VERSION "canboat-NMEA2000-curated"

NS_ :

BS_:

BU_: Vector__XXX
BO_ 2582645504 PGN_126987_alertThreshold: 18 Vector__XXX
 SG_ Alert_Type : 0|4@1+ (1.0,0) [0|15] "" Vector__XXX
 SG_ Alert_Category : 4|4@1+ (1.0,0) [0|15] "" Vector__XXX
 SG_ Alert_System : 8|8@1+ (1.0,0) [0|255] "" Vector__XXX
 SG_ Alert_Sub_System : 16|8@1+ (1.0,0) [0|255] "" Vector__XXX
 SG_ Alert_ID : 24|16@1+ (1.0,0) [0|65535] "" Vector__XXX
 SG_ Data_Source_Network_ID_NAME : 40|64@1+ (1.0,0) [0|18446744073709551615] "" Vector__XXX
 SG_ Data_Source_Instance : 104|8@1+ (1.0,0) [0|255] "" Vector__XXX
 SG_ Data_Source_Index_Source : 112|8@1+ (1.0,0) [0|255] "" Vector__XXX
 SG_ Alert_Occurrence_Number : 120|8@1+ (1.0,0) [0|255] "" Vector__XXX
 SG_ Number_of_Parameters : 128|8@1+ (1.0,0) [0|255] "" Vector__XXX
 SG_ field136 : 136|8@1+ (1.0,0) [0|255] "" Vector__XXX

BO_ 2582645760 PGN_126988_alertValue: 18 Vector__XXX
 SG_ Alert_Type : 0|4@1+ (1.0,0) [0|15] "" Vector__XXX
 SG_ Alert_Category : 4|4@1+ (1.0,0) [0|15] "" Vector__XXX
 SG_ Alert_System : 8|8@1+ (1.0,0) [0|255] "" Vector__XXX
 SG_ Alert_Sub_System : 16|8@1+ (1.0,0) [0|255] "" Vector__XXX
 SG_ Alert_ID : 24|16@1+ (1.0,0) [0|65535] "" Vector__XXX
 SG_ Data_Source_Network_ID_NAME : 40|64@1+ (1.0,0) [0|18446744073709551615] "" Vector__XXX
 SG_ Data_Source_Instance : 104|8@1+ (1.0,0) [0|255] "" Vector__XXX
 SG_ Data_Source_Index_Source : 112|8@1+ (1.0,0) [0|255] "" Vector__XXX
 SG_ Alert_Occurrence_Number : 120|8@1+ (1.0,0) [0|255] "" Vector__XXX
 SG_ Number_of_Parameters : 128|8@1+ (1.0,0) [0|255] "" Vector__XXX
 SG_ field136 : 136|8@1+ (1.0,0) [0|255] "" Vector__XXX

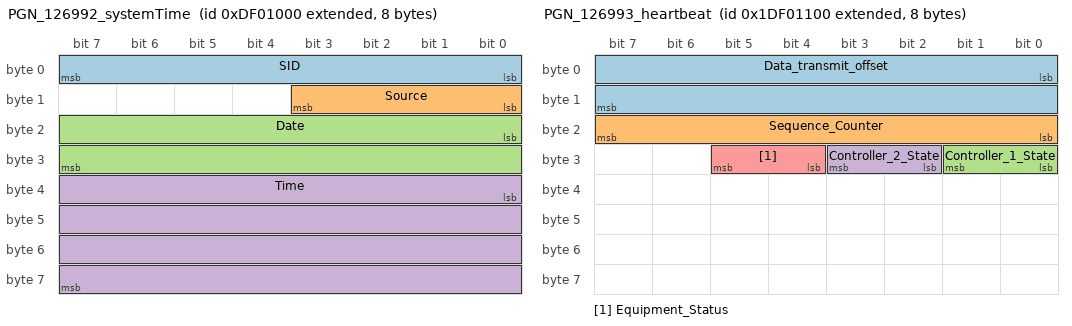
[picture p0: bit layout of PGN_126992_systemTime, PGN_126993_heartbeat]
BO_ 2381320192 PGN_126992_systemTime: 8 Vector__XXX
 SG_ SID : 0|8@1+ (1.0,0) [0|255] "" Vector__XXX
 SG_ Source : 8|4@1+ (1.0,0) [0|15] "" Vector__XXX
 SG_ Date : 16|16@1+ (1.0,0) [0|65535] "" Vector__XXX
 SG_ Time : 32|32@1+ (0.0001,0) [0.0|86401.0] "" Vector__XXX

BO_ 2649755904 PGN_126993_heartbeat: 8 Vector__XXX
 SG_ Data_transmit_offset : 0|16@1+ (0.001,0) [0.0|65.535] "" Vector__XXX
 SG_ Sequence_Counter : 16|8@1+ (1.0,0) [0|255] "" Vector__XXX
 SG_ Controller_1_State : 24|2@1+ (1.0,0) [0|3] "" Vector__XXX
 SG_ Controller_2_State : 26|2@1+ (1.0,0) [0|3] "" Vector__XXX
 SG_ Equipment_Status : 28|2@1+ (1.0,0) [0|3] "" Vector__XXX

BO_ 2582647808 PGN_126996_productInformation: 134 Vector__XXX
 SG_ NMEA_2000_Version : 0|16@1+ (0.001,0) [0.0|65.535] "" Vector__XXX
 SG_ Product_Code : 16|16@1+ (1.0,0) [0|65535] "" Vector__XXX
 SG_ Model_ID : 32|256@1+ (1.0,0) [0|115792089237316195423570985008687907853269984665640564039457584007913129639935] "" Vector__XXX
 SG_ Software_Version_Code : 288|256@1+ (1.0,0) [0|115792089237316195423570985008687907853269984665640564039457584007913129639935] "" Vector__XXX
 SG_ Model_Version : 544|256@1+ (1.0,0) [0|115792089237316195423570985008687907853269984665640564039457584007913129639935] "" Vector__XXX
 SG_ Model_Serial_Code : 800|256@1+ (1.0,0) [0|115792089237316195423570985008687907853269984665640564039457584007913129639935] "" Vector__XXX
 SG_ Certification_Level : 1056|8@1+ (1.0,0) [0|255] "" Vector__XXX
 SG_ Load_Equivalency : 1064|8@1+ (1.0,0) [0|255] "" Vector__XXX

BO_ 2582648320 PGN_126998_configurationInformation: 8 Vector__XXX
 SG_ Installation_Description__1 : 0|8@1+ (1.0,0) [0|255] "" Vector__XXX
 SG_ Installation_Description__2 : 8|8@1+ (1.0,0) [0|255] "" Vector__XXX
 SG_ Manufacturer_Information : 16|8@1+ (1.0,0) [0|255] "" Vector__XXX

BO_ 2582708480 PGN_127233_manOverboardNotification: 35 Vector__XXX
 SG_ SID : 0|8@1+ (1.0,0) [0|255] "" Vector__XXX
 SG_ MOB_Emitter_ID : 8|32@1+ (1.0,0) [0|4294967295] "" Vector__XXX
 SG_ Man_Overboard_Status : 40|3@1+ (1.0,0) [0|7] "" Vector__XXX
 SG_ Activation_Time : 48|32@1+ (0.0001,0) [0.0|86401.0] "" Vector__XXX
 SG_ Position_Source : 80|3@1+ (1.0,0) [0|7] "" Vector__XXX
 SG_ Position_Date : 88|16@1+ (1.0,0) [0|65535] "" Vector__XXX
 SG_ Position_Time : 104|32@1+ (0.0001,0) [0.0|86401.0] "" Vector__XXX
 SG_ Latitude : 136|32@1- (1e-07,0) [-90.0|90.0] "" Vector__XXX
 SG_ Longitude : 168|32@1- (1e-07,0) [-180.0|180.0] "" Vector__XXX
 SG_ COG_Reference : 200|2@1+ (1.0,0) [0|3] "" Vector__XXX
 SG_ COG : 208|16@1+ (0.0001,0) [0.0|6.5535000000000005] "" Vector__XXX
 SG_ SOG : 224|16@1+ (0.01,0) [0.0|655.35] "" Vector__XXX
 SG_ MMSI_of_vessel_of_origin : 240|32@1+ (1.0,0) [2000000.0|999999999.0] "" Vector__XXX
 SG_ MOB_Emitter_Battery_Low_Status : 272|3@1+ (1.0,0) [0|7] "" Vector__XXX

BO_ 2314274048 PGN_127237_headingTrackControl: 21 Vector__XXX
 SG_ Rudder_Limit_Exceeded : 0|2@1+ (1.0,0) [0|3] "" Vector__XXX
 SG_ Off_Heading_Limit_Exceeded : 2|2@1+ (1.0,0) [0|3] "" Vector__XXX
 SG_ Off_Track_Limit_Exceeded : 4|2@1+ (1.0,0) [0|3] "" Vector__XXX
 SG_ Override : 6|2@1+ (1.0,0) [0|3] "" Vector__XXX
 SG_ Steering_Mode : 8|3@1+ (1.0,0) [0|7] "" Vector__XXX
 SG_ Turn_Mode : 11|3@1+ (1.0,0) [0|7] "" Vector__XXX
 SG_ Heading_Reference : 14|2@1+ (1.0,0) [0|3] "" Vector__XXX
 SG_ Commanded_Rudder_Direction : 21|3@1+ (1.0,0) [0|7] "" Vector__XXX
 SG_ Commanded_Rudder_Angle : 24|16@1- (0.0001,0) [-3.2768|3.2767] "" Vector__XXX
 SG_ Heading_To_Steer__Course_ : 40|16@1+ (0.0001,0) [0.0|6.5535000000000005] "" Vector__XXX
 SG_ Track : 56|16@1+ (0.0001,0) [0.0|6.5535000000000005] "" Vector__XXX
 SG_ Rudder_Limit : 72|16@1+ (0.0001,0) [0.0|6.5535000000000005] "" Vector__XXX
 SG_ Off_Heading_Limit : 88|16@1+ (0.0001,0) [0.0|6.5535000000000005] "" Vector__XXX
 SG_ Radius_of_Turn_Order : 104|16@1- (1.0,0) [-32768|32767] "" Vector__XXX
 SG_ Rate_of_Turn_Order : 120|16@1- (3.125e-05,0) [-1.024|1.02396875] "" Vector__XXX
 SG_ Off_Track_Limit : 136|16@1- (1.0,0) [-32768|32767] "" Vector__XXX
 SG_ Vessel_Heading : 152|16@1+ (0.0001,0) [0.0|6.5535000000000005] "" Vector__XXX

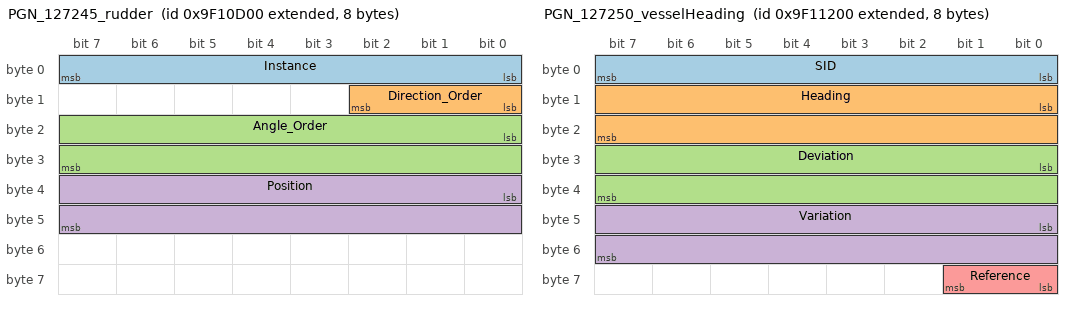
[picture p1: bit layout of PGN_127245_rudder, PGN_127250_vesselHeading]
BO_ 2314276096 PGN_127245_rudder: 8 Vector__XXX
 SG_ Instance : 0|8@1+ (1.0,0) [0|255] "" Vector__XXX
 SG_ Direction_Order : 8|3@1+ (1.0,0) [0|7] "" Vector__XXX
 SG_ Angle_Order : 16|16@1- (0.0001,0) [-3.2768|3.2767] "" Vector__XXX
 SG_ Position : 32|16@1- (0.0001,0) [-3.2768|3.2767] "" Vector__XXX

BO_ 2314277376 PGN_127250_vesselHeading: 8 Vector__XXX
 SG_ SID : 0|8@1+ (1.0,0) [0|255] "" Vector__XXX
 SG_ Heading : 8|16@1+ (0.0001,0) [0.0|6.5535000000000005] "" Vector__XXX
 SG_ Deviation : 24|16@1- (0.0001,0) [-3.2768|3.2767] "" Vector__XXX
 SG_ Variation : 40|16@1- (0.0001,0) [-3.2768|3.2767] "" Vector__XXX
 SG_ Reference : 56|2@1+ (1.0,0) [0|3] "" Vector__XXX

BO_ 2314277632 PGN_127251_rateOfTurn: 8 Vector__XXX
 SG_ SID : 0|8@1+ (1.0,0) [0|255] "" Vector__XXX
 SG_ Rate : 8|32@1- (3.125e-08,0) [-67.108864|67.10886396875] "" Vector__XXX

BO_ 2381386752 PGN_127252_heave: 8 Vector__XXX
 SG_ SID : 0|8@1+ (1.0,0) [0|255] "" Vector__XXX
 SG_ Heave : 8|16@1- (0.01,0) [-327.68|327.67] "" Vector__XXX

BO_ 2381388032 PGN_127257_attitude: 8 Vector__XXX
 SG_ SID : 0|8@1+ (1.0,0) [0|255] "" Vector__XXX
 SG_ Yaw : 8|16@1- (0.0001,0) [-3.2768|3.2767] "" Vector__XXX
 SG_ Pitch : 24|16@1- (0.0001,0) [-3.2768|3.2767] "" Vector__XXX
 SG_ Roll : 40|16@1- (0.0001,0) [-3.2768|3.2767] "" Vector__XXX

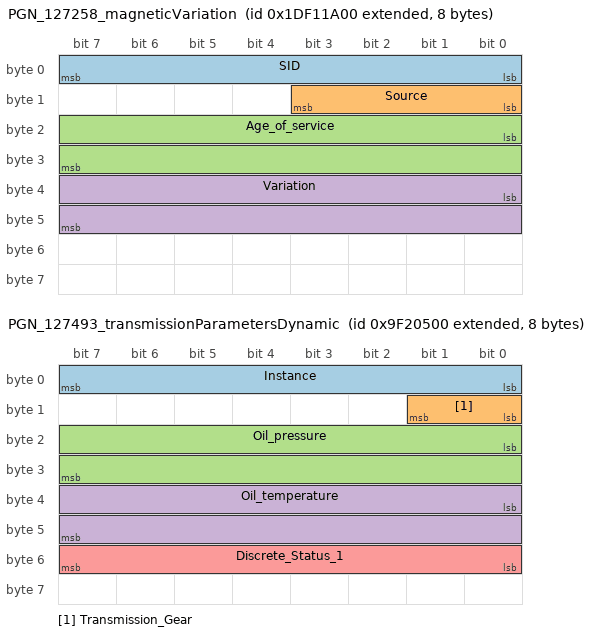
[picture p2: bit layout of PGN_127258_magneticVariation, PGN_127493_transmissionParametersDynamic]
BO_ 2649823744 PGN_127258_magneticVariation: 8 Vector__XXX
 SG_ SID : 0|8@1+ (1.0,0) [0|255] "" Vector__XXX
 SG_ Source : 8|4@1+ (1.0,0) [0|15] "" Vector__XXX
 SG_ Age_of_service : 16|16@1+ (1.0,0) [0|65535] "" Vector__XXX
 SG_ Variation : 32|16@1- (0.0001,0) [-3.2768|3.2767] "" Vector__XXX

BO_ 2314338304 PGN_127488_engineParametersRapidUpdate: 8 Vector__XXX
 SG_ Instance : 0|8@1+ (1.0,0) [0|255] "" Vector__XXX
 SG_ Speed : 8|16@1+ (0.25,0) [0.0|16383.75] "rpm" Vector__XXX
 SG_ Boost_Pressure : 24|16@1+ (100.0,0) [0.0|6553500.0] "" Vector__XXX
 SG_ Tilt_Trim : 40|8@1- (1.0,0) [-128|127] "%" Vector__XXX

BO_ 2314338560 PGN_127489_engineParametersDynamic: 26 Vector__XXX
 SG_ Instance : 0|8@1+ (1.0,0) [0|255] "" Vector__XXX
 SG_ Oil_pressure : 8|16@1+ (100.0,0) [0.0|6553500.0] "" Vector__XXX
 SG_ Oil_temperature : 24|16@1+ (0.1,0) [0.0|6553.5] "" Vector__XXX
 SG_ Temperature : 40|16@1+ (0.01,0) [0.0|655.35] "" Vector__XXX
 SG_ Alternator_Potential : 56|16@1- (0.01,0) [-327.68|327.67] "" Vector__XXX
 SG_ Fuel_Rate : 72|16@1- (0.1,0) [-3276.8|3276.7000000000003] "" Vector__XXX
 SG_ Total_Engine_hours : 88|32@1+ (1.0,0) [0|4294967295] "" Vector__XXX
 SG_ Coolant_Pressure : 120|16@1+ (100.0,0) [0.0|6553500.0] "" Vector__XXX
 SG_ Fuel_Pressure : 136|16@1+ (1000.0,0) [0.0|65535000.0] "" Vector__XXX
 SG_ Discrete_Status_1 : 160|16@1+ (1.0,0) [0|65535] "" Vector__XXX
 SG_ Discrete_Status_2 : 176|16@1+ (1.0,0) [0|65535] "" Vector__XXX
 SG_ Engine_Load : 192|8@1- (1.0,0) [-128|127] "%" Vector__XXX
 SG_ Engine_Torque : 200|8@1- (1.0,0) [-128|127] "%" Vector__XXX

BO_ 2582774272 PGN_127490_electricDriveStatusDynamic: 12 Vector__XXX
 SG_ Inverter_Motor_Identifier : 0|8@1+ (1.0,0) [0|255] "" Vector__XXX
 SG_ Operating_Mode : 8|4@1+ (1.0,0) [0|15] "" Vector__XXX
 SG_ Motor_Temperature : 16|16@1+ (0.01,0) [0.0|655.35] "" Vector__XXX
 SG_ Inverter_Temperature : 32|16@1+ (0.01,0) [0.0|655.35] "" Vector__XXX
 SG_ Coolant_Temperature : 48|16@1+ (0.01,0) [0.0|655.35] "" Vector__XXX
 SG_ Gear_Temperature : 64|16@1+ (0.01,0) [0.0|655.35] "" Vector__XXX
 SG_ Shaft_Torque : 80|16@1+ (1.0,0) [0|65535] "" Vector__XXX

BO_ 2582774528 PGN_127491_electricEnergyStorageStatusDynamic: 15 Vector__XXX
 SG_ Energy_Storage_Identifier : 0|8@1+ (1.0,0) [0|255] "" Vector__XXX
 SG_ State_of_Charge : 8|8@1+ (1.0,0) [0|255] "%" Vector__XXX
 SG_ Time_Remaining : 16|16@1+ (60.0,0) [0.0|3932100.0] "" Vector__XXX
 SG_ Highest_Cell_Temperature : 32|16@1+ (0.01,0) [0.0|655.35] "" Vector__XXX
 SG_ Lowest_Cell_Temperature : 48|16@1+ (0.01,0) [0.0|655.35] "" Vector__XXX
 SG_ Average_Cell_Temperature : 64|16@1+ (0.01,0) [0.0|655.35] "" Vector__XXX
 SG_ Max_Discharge_Current : 80|16@1- (0.1,0) [-3276.8|3276.7000000000003] "" Vector__XXX
 SG_ Max_Charge_Current : 96|16@1- (0.1,0) [-3276.8|3276.7000000000003] "" Vector__XXX
 SG_ Cooling_System_Status : 112|4@1+ (1.0,0) [0|15] "" Vector__XXX
 SG_ Heating_System_Status : 116|4@1+ (1.0,0) [0|15] "" Vector__XXX

BO_ 2314339584 PGN_127493_transmissionParametersDynamic: 8 Vector__XXX
 SG_ Instance : 0|8@1+ (1.0,0) [0|255] "" Vector__XXX
 SG_ Transmission_Gear : 8|2@1+ (1.0,0) [0|3] "" Vector__XXX
 SG_ Oil_pressure : 16|16@1+ (100.0,0) [0.0|6553500.0] "" Vector__XXX
 SG_ Oil_temperature : 32|16@1+ (0.1,0) [0.0|6553.5] "" Vector__XXX
 SG_ Discrete_Status_1 : 48|8@1+ (1.0,0) [0|255] "" Vector__XXX

BO_ 2582775296 PGN_127494_electricDriveInformation: 28 Vector__XXX
 SG_ Inverter_Motor_Identifier : 0|8@1+ (1.0,0) [0|255] "" Vector__XXX
 SG_ Motor_Type : 8|4@1+ (1.0,0) [0|15] "" Vector__XXX
 SG_ Motor_Voltage_Rating : 16|16@1+ (0.1,0) [0.0|6553.5] "" Vector__XXX
 SG_ Maximum_Continuous_Motor_Power : 32|32@1+ (1.0,0) [0|4294967295] "" Vector__XXX
 SG_ Maximum_Boost_Motor_Power : 64|32@1+ (1.0,0) [0|4294967295] "" Vector__XXX
 SG_ Maximum_Motor_Temperature_Rating : 96|16@1+ (0.01,0) [0.0|655.35] "" Vector__XXX
 SG_ Rated_Motor_Speed : 112|16@1+ (0.25,0) [0.0|16383.75] "rpm" Vector__XXX
 SG_ Maximum_Controller_Temperature_Rating : 128|16@1+ (0.01,0) [0.0|655.35] "" Vector__XXX
 SG_ Motor_Shaft_Torque_Rating : 144|16@1+ (1.0,0) [0|65535] "" Vector__XXX
 SG_ Motor_DC_Voltage_Derating_Threshold : 160|16@1+ (0.1,0) [0.0|6553.5] "" Vector__XXX
 SG_ Motor_DC_Voltage_Cut_Off_Threshold : 176|16@1+ (0.1,0) [0.0|6553.5] "" Vector__XXX
 SG_ Drive_Motor_Hours : 192|32@1+ (1.0,0) [0|4294967295] "" Vector__XXX

BO_ 2582775552 PGN_127495_electricEnergyStorageInformation: 21 Vector__XXX
 SG_ Energy_Storage_Identifier : 0|8@1+ (1.0,0) [0|255] "" Vector__XXX
 SG_ Motor_Type : 8|4@1+ (1.0,0) [0|15] "" Vector__XXX
 SG_ Storage_Chemistry_Conversion : 16|8@1+ (1.0,0) [0|255] "" Vector__XXX
 SG_ Maximum_Temperature_Derating : 24|16@1+ (0.01,0) [0.0|655.35] "" Vector__XXX
 SG_ Maximum_Temperature_Shut_Off : 40|16@1+ (0.01,0) [0.0|655.35] "" Vector__XXX
 SG_ Minimum_Temperature_Derating : 56|16@1+ (0.01,0) [0.0|655.35] "" Vector__XXX
 SG_ Minimum_Temperature_Shut_Off : 72|16@1+ (0.01,0) [0.0|655.35] "" Vector__XXX
 SG_ Usable_Battery_Energy : 88|32@1+ (1.0,0) [0|4294967295] "" Vector__XXX
 SG_ State_of_Health : 120|8@1+ (1.0,0) [0|255] "" Vector__XXX
 SG_ Battery_Cycle_Counter : 128|16@1+ (1.0,0) [0|65535] "" Vector__XXX
 SG_ Battery_Full_Status : 144|2@1+ (1.0,0) [0|3] "" Vector__XXX
 SG_ Battery_Empty_Status : 146|2@1+ (1.0,0) [0|3] "" Vector__XXX
 SG_ Maximum_Charge__SOC_ : 152|8@1+ (1.0,0) [0|255] "" Vector__XXX
 SG_ Minimum_Charge__SOC_ : 160|8@1+ (1.0,0) [0|255] "" Vector__XXX

BO_ 2515666944 PGN_127496_tripParametersVessel: 14 Vector__XXX
 SG_ Time_to_Empty : 0|32@1+ (0.001,0) [0.0|4294967.295] "" Vector__XXX
 SG_ Distance_to_Empty : 32|32@1+ (0.01,0) [0.0|42949672.95] "" Vector__XXX
 SG_ Estimated_Fuel_Remaining : 64|16@1+ (1.0,0) [0|65535] "" Vector__XXX
 SG_ Trip_Run_Time : 80|32@1+ (0.001,0) [0.0|4294967.295] "" Vector__XXX

BO_ 2515667200 PGN_127497_tripParametersEngine: 9 Vector__XXX
 SG_ Instance : 0|8@1+ (1.0,0) [0|255] "" Vector__XXX
 SG_ Trip_Fuel_Used : 8|16@1+ (1.0,0) [0|65535] "" Vector__XXX
 SG_ Fuel_Rate__Average : 24|16@1- (0.1,0) [-3276.8|3276.7000000000003] "" Vector__XXX
 SG_ Fuel_Rate__Economy : 40|16@1- (0.1,0) [-3276.8|3276.7000000000003] "" Vector__XXX
 SG_ Instantaneous_Fuel_Economy : 56|16@1- (0.1,0) [-3276.8|3276.7000000000003] "" Vector__XXX

BO_ 2515667456 PGN_127498_engineParametersStatic: 8 Vector__XXX
 SG_ Instance : 0|8@1+ (1.0,0) [0|255] "" Vector__XXX
 SG_ Rated_Engine_Speed : 8|16@1+ (0.25,0) [0.0|16383.75] "rpm" Vector__XXX
 SG_ VIN : 24|8@1+ (1.0,0) [0|255] "" Vector__XXX
 SG_ Software_ID : 32|8@1+ (1.0,0) [0|255] "" Vector__XXX

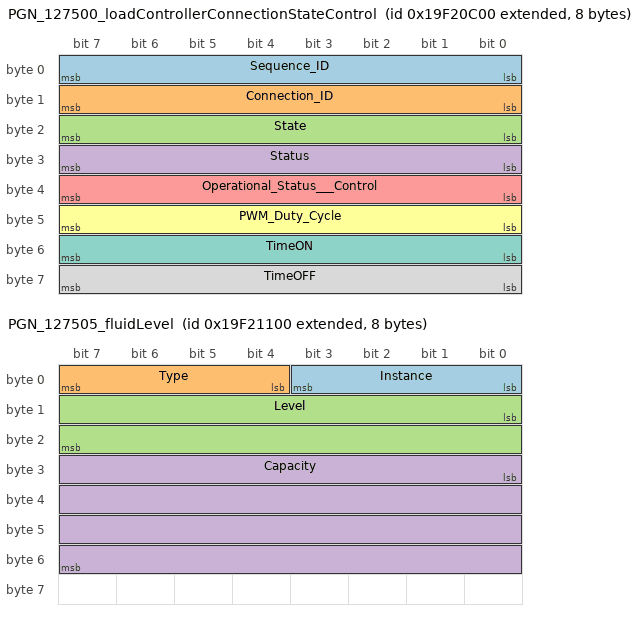
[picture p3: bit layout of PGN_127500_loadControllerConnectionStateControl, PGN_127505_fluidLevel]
BO_ 2582776832 PGN_127500_loadControllerConnectionStateControl: 8 Vector__XXX
 SG_ Sequence_ID : 0|8@1+ (1.0,0) [0|255] "" Vector__XXX
 SG_ Connection_ID : 8|8@1+ (1.0,0) [0|255] "" Vector__XXX
 SG_ State : 16|8@1+ (1.0,0) [0|255] "" Vector__XXX
 SG_ Status : 24|8@1+ (1.0,0) [0|255] "" Vector__XXX
 SG_ Operational_Status___Control : 32|8@1+ (1.0,0) [0|255] "" Vector__XXX
 SG_ PWM_Duty_Cycle : 40|8@1+ (1.0,0) [0|255] "" Vector__XXX
 SG_ TimeON : 48|8@1+ (1.0,0) [0|255] "" Vector__XXX
 SG_ TimeOFF : 56|8@1+ (1.0,0) [0|255] "" Vector__XXX

BO_ 2381450496 PGN_127501_binarySwitchBankStatus: 8 Vector__XXX
 SG_ Instance : 0|8@1+ (1.0,0) [0|255] "" Vector__XXX
 SG_ Indicator1 : 8|2@1+ (1.0,0) [0|3] "" Vector__XXX
 SG_ Indicator2 : 10|2@1+ (1.0,0) [0|3] "" Vector__XXX
 SG_ Indicator3 : 12|2@1+ (1.0,0) [0|3] "" Vector__XXX
 SG_ Indicator4 : 14|2@1+ (1.0,0) [0|3] "" Vector__XXX
 SG_ Indicator5 : 16|2@1+ (1.0,0) [0|3] "" Vector__XXX
 SG_ Indicator6 : 18|2@1+ (1.0,0) [0|3] "" Vector__XXX
 SG_ Indicator7 : 20|2@1+ (1.0,0) [0|3] "" Vector__XXX
 SG_ Indicator8 : 22|2@1+ (1.0,0) [0|3] "" Vector__XXX
 SG_ Indicator9 : 24|2@1+ (1.0,0) [0|3] "" Vector__XXX
 SG_ Indicator10 : 26|2@1+ (1.0,0) [0|3] "" Vector__XXX
 SG_ Indicator11 : 28|2@1+ (1.0,0) [0|3] "" Vector__XXX
 SG_ Indicator12 : 30|2@1+ (1.0,0) [0|3] "" Vector__XXX
 SG_ Indicator13 : 32|2@1+ (1.0,0) [0|3] "" Vector__XXX
 SG_ Indicator14 : 34|2@1+ (1.0,0) [0|3] "" Vector__XXX
 SG_ Indicator15 : 36|2@1+ (1.0,0) [0|3] "" Vector__XXX
 SG_ Indicator16 : 38|2@1+ (1.0,0) [0|3] "" Vector__XXX
 SG_ Indicator17 : 40|2@1+ (1.0,0) [0|3] "" Vector__XXX
 SG_ Indicator18 : 42|2@1+ (1.0,0) [0|3] "" Vector__XXX
 SG_ Indicator19 : 44|2@1+ (1.0,0) [0|3] "" Vector__XXX
 SG_ Indicator20 : 46|2@1+ (1.0,0) [0|3] "" Vector__XXX
 SG_ Indicator21 : 48|2@1+ (1.0,0) [0|3] "" Vector__XXX
 SG_ Indicator22 : 50|2@1+ (1.0,0) [0|3] "" Vector__XXX
 SG_ Indicator23 : 52|2@1+ (1.0,0) [0|3] "" Vector__XXX
 SG_ Indicator24 : 54|2@1+ (1.0,0) [0|3] "" Vector__XXX
 SG_ Indicator25 : 56|2@1+ (1.0,0) [0|3] "" Vector__XXX
 SG_ Indicator26 : 58|2@1+ (1.0,0) [0|3] "" Vector__XXX
 SG_ Indicator27 : 60|2@1+ (1.0,0) [0|3] "" Vector__XXX
 SG_ Indicator28 : 62|2@1+ (1.0,0) [0|3] "" Vector__XXX

BO_ 2381450752 PGN_127502_switchBankControl: 8 Vector__XXX
 SG_ Instance : 0|8@1+ (1.0,0) [0|255] "" Vector__XXX
 SG_ Switch1 : 8|2@1+ (1.0,0) [0|3] "" Vector__XXX
 SG_ Switch2 : 10|2@1+ (1.0,0) [0|3] "" Vector__XXX
 SG_ Switch3 : 12|2@1+ (1.0,0) [0|3] "" Vector__XXX
 SG_ Switch4 : 14|2@1+ (1.0,0) [0|3] "" Vector__XXX
 SG_ Switch5 : 16|2@1+ (1.0,0) [0|3] "" Vector__XXX
 SG_ Switch6 : 18|2@1+ (1.0,0) [0|3] "" Vector__XXX
 SG_ Switch7 : 20|2@1+ (1.0,0) [0|3] "" Vector__XXX
 SG_ Switch8 : 22|2@1+ (1.0,0) [0|3] "" Vector__XXX
 SG_ Switch9 : 24|2@1+ (1.0,0) [0|3] "" Vector__XXX
 SG_ Switch10 : 26|2@1+ (1.0,0) [0|3] "" Vector__XXX
 SG_ Switch11 : 28|2@1+ (1.0,0) [0|3] "" Vector__XXX
 SG_ Switch12 : 30|2@1+ (1.0,0) [0|3] "" Vector__XXX
 SG_ Switch13 : 32|2@1+ (1.0,0) [0|3] "" Vector__XXX
 SG_ Switch14 : 34|2@1+ (1.0,0) [0|3] "" Vector__XXX
 SG_ Switch15 : 36|2@1+ (1.0,0) [0|3] "" Vector__XXX
 SG_ Switch16 : 38|2@1+ (1.0,0) [0|3] "" Vector__XXX
 SG_ Switch17 : 40|2@1+ (1.0,0) [0|3] "" Vector__XXX
 SG_ Switch18 : 42|2@1+ (1.0,0) [0|3] "" Vector__XXX
 SG_ Switch19 : 44|2@1+ (1.0,0) [0|3] "" Vector__XXX
 SG_ Switch20 : 46|2@1+ (1.0,0) [0|3] "" Vector__XXX
 SG_ Switch21 : 48|2@1+ (1.0,0) [0|3] "" Vector__XXX
 SG_ Switch22 : 50|2@1+ (1.0,0) [0|3] "" Vector__XXX
 SG_ Switch23 : 52|2@1+ (1.0,0) [0|3] "" Vector__XXX
 SG_ Switch24 : 54|2@1+ (1.0,0) [0|3] "" Vector__XXX
 SG_ Switch25 : 56|2@1+ (1.0,0) [0|3] "" Vector__XXX
 SG_ Switch26 : 58|2@1+ (1.0,0) [0|3] "" Vector__XXX
 SG_ Switch27 : 60|2@1+ (1.0,0) [0|3] "" Vector__XXX
 SG_ Switch28 : 62|2@1+ (1.0,0) [0|3] "" Vector__XXX

BO_ 2582777600 PGN_127503_acInputStatus: 8 Vector__XXX
 SG_ Instance : 0|8@1+ (1.0,0) [0|255] "" Vector__XXX
 SG_ Number_of_Lines : 8|8@1+ (1.0,0) [0|255] "" Vector__XXX
 SG_ field16 : 16|8@1+ (1.0,0) [0|255] "" Vector__XXX

BO_ 2582777856 PGN_127504_acOutputStatus: 8 Vector__XXX
 SG_ Instance : 0|8@1+ (1.0,0) [0|255] "" Vector__XXX
 SG_ Number_of_Lines : 8|8@1+ (1.0,0) [0|255] "" Vector__XXX
 SG_ field16 : 16|8@1+ (1.0,0) [0|255] "" Vector__XXX

BO_ 2582778112 PGN_127505_fluidLevel: 8 Vector__XXX
 SG_ Instance : 0|4@1+ (1.0,0) [0|15] "" Vector__XXX
 SG_ Type : 4|4@1+ (1.0,0) [0|15] "" Vector__XXX
 SG_ Level : 8|16@1- (0.004,0) [-131.072|131.068] "%" Vector__XXX
 SG_ Capacity : 24|32@1+ (0.1,0) [0.0|429496729.5] "" Vector__XXX

BO_ 2582778368 PGN_127506_dcDetailedStatus: 11 Vector__XXX
 SG_ SID : 0|8@1+ (1.0,0) [0|255] "" Vector__XXX
 SG_ Instance : 8|8@1+ (1.0,0) [0|255] "" Vector__XXX
 SG_ DC_Type : 16|8@1+ (1.0,0) [0|255] "" Vector__XXX
 SG_ State_of_Charge : 24|8@1+ (1.0,0) [0|255] "%" Vector__XXX
 SG_ State_of_Health : 32|8@1+ (1.0,0) [0|255] "%" Vector__XXX
 SG_ Time_Remaining : 40|16@1+ (60.0,0) [0.0|3932100.0] "" Vector__XXX
 SG_ Ripple_Voltage : 56|16@1+ (0.001,0) [0.0|65.535] "" Vector__XXX
 SG_ Remaining_capacity : 72|16@1+ (1.0,0) [0|65535] "Ah" Vector__XXX

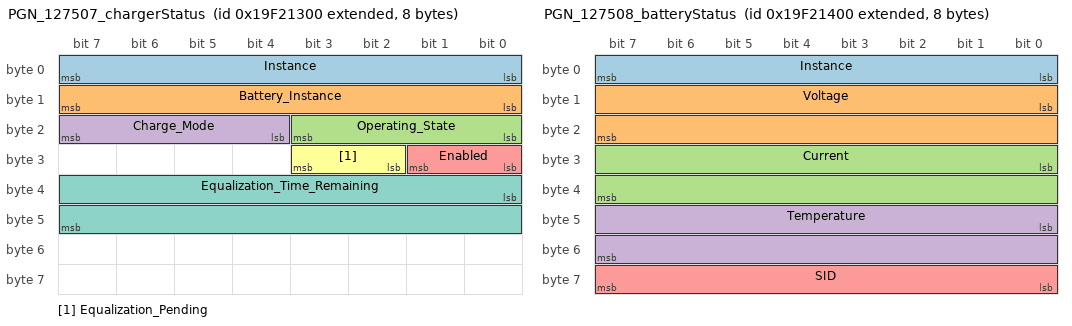
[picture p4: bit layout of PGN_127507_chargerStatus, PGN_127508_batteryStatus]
BO_ 2582778624 PGN_127507_chargerStatus: 8 Vector__XXX
 SG_ Instance : 0|8@1+ (1.0,0) [0|255] "" Vector__XXX
 SG_ Battery_Instance : 8|8@1+ (1.0,0) [0|255] "" Vector__XXX
 SG_ Operating_State : 16|4@1+ (1.0,0) [0|15] "" Vector__XXX
 SG_ Charge_Mode : 20|4@1+ (1.0,0) [0|15] "" Vector__XXX
 SG_ Enabled : 24|2@1+ (1.0,0) [0|3] "" Vector__XXX
 SG_ Equalization_Pending : 26|2@1+ (1.0,0) [0|3] "" Vector__XXX
 SG_ Equalization_Time_Remaining : 32|16@1+ (60.0,0) [0.0|3932100.0] "" Vector__XXX

BO_ 2582778880 PGN_127508_batteryStatus: 8 Vector__XXX
 SG_ Instance : 0|8@1+ (1.0,0) [0|255] "" Vector__XXX
 SG_ Voltage : 8|16@1- (0.01,0) [-327.68|327.67] "" Vector__XXX
 SG_ Current : 24|16@1- (0.1,0) [-3276.8|3276.7000000000003] "" Vector__XXX
 SG_ Temperature : 40|16@1+ (0.01,0) [0.0|655.35] "" Vector__XXX
 SG_ SID : 56|8@1+ (1.0,0) [0|255] "" Vector__XXX

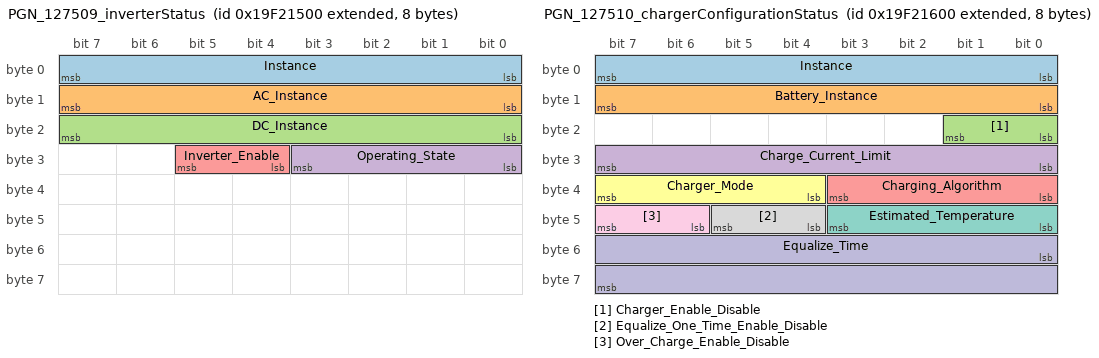
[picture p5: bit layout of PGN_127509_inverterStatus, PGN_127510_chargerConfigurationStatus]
BO_ 2582779136 PGN_127509_inverterStatus: 8 Vector__XXX
 SG_ Instance : 0|8@1+ (1.0,0) [0|255] "" Vector__XXX
 SG_ AC_Instance : 8|8@1+ (1.0,0) [0|255] "" Vector__XXX
 SG_ DC_Instance : 16|8@1+ (1.0,0) [0|255] "" Vector__XXX
 SG_ Operating_State : 24|4@1+ (1.0,0) [0|15] "" Vector__XXX
 SG_ Inverter_Enable : 28|2@1+ (1.0,0) [0|3] "" Vector__XXX

BO_ 2582779392 PGN_127510_chargerConfigurationStatus: 8 Vector__XXX
 SG_ Instance : 0|8@1+ (1.0,0) [0|255] "" Vector__XXX
 SG_ Battery_Instance : 8|8@1+ (1.0,0) [0|255] "" Vector__XXX
 SG_ Charger_Enable_Disable : 16|2@1+ (1.0,0) [0|3] "" Vector__XXX
 SG_ Charge_Current_Limit : 24|8@1+ (1.0,0) [0|255] "%" Vector__XXX
 SG_ Charging_Algorithm : 32|4@1+ (1.0,0) [0|15] "" Vector__XXX
 SG_ Charger_Mode : 36|4@1+ (1.0,0) [0|15] "" Vector__XXX
 SG_ Estimated_Temperature : 40|4@1+ (1.0,0) [0|15] "" Vector__XXX
 SG_ Equalize_One_Time_Enable_Disable : 44|2@1+ (1.0,0) [0|3] "" Vector__XXX
 SG_ Over_Charge_Enable_Disable : 46|2@1+ (1.0,0) [0|3] "" Vector__XXX
 SG_ Equalize_Time : 48|16@1+ (60.0,0) [0.0|3932100.0] "" Vector__XXX

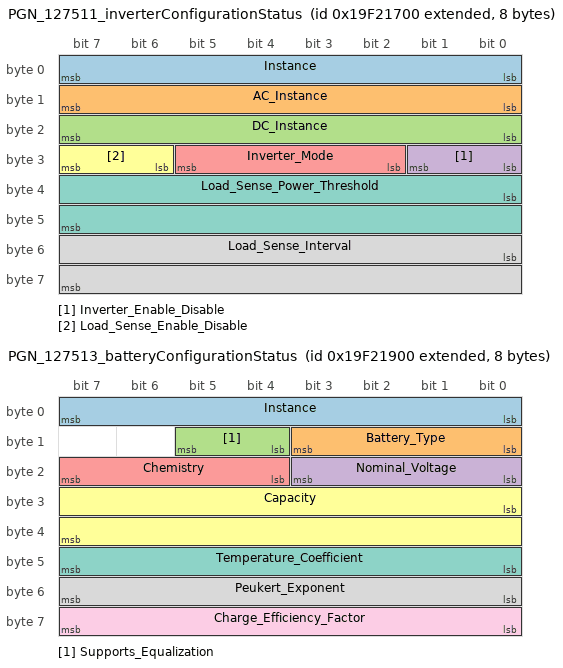
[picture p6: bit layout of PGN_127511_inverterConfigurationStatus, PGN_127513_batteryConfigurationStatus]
BO_ 2582779648 PGN_127511_inverterConfigurationStatus: 8 Vector__XXX
 SG_ Instance : 0|8@1+ (1.0,0) [0|255] "" Vector__XXX
 SG_ AC_Instance : 8|8@1+ (1.0,0) [0|255] "" Vector__XXX
 SG_ DC_Instance : 16|8@1+ (1.0,0) [0|255] "" Vector__XXX
 SG_ Inverter_Enable_Disable : 24|2@1+ (1.0,0) [0|3] "" Vector__XXX
 SG_ Inverter_Mode : 26|4@1+ (1.0,0) [0|15] "" Vector__XXX
 SG_ Load_Sense_Enable_Disable : 30|2@1+ (1.0,0) [0|3] "" Vector__XXX
 SG_ Load_Sense_Power_Threshold : 32|16@1+ (1.0,0) [0|65535] "" Vector__XXX
 SG_ Load_Sense_Interval : 48|16@1+ (0.01,0) [0.0|655.35] "" Vector__XXX

BO_ 2582779904 PGN_127512_agsConfigurationStatus: 8 Vector__XXX
 SG_ Instance : 0|8@1+ (1.0,0) [0|255] "" Vector__XXX
 SG_ Generator_Instance : 8|8@1+ (1.0,0) [0|255] "" Vector__XXX
 SG_ AGS_Mode : 16|4@1+ (1.0,0) [0|15] "" Vector__XXX

BO_ 2582780160 PGN_127513_batteryConfigurationStatus: 8 Vector__XXX
 SG_ Instance : 0|8@1+ (1.0,0) [0|255] "" Vector__XXX
 SG_ Battery_Type : 8|4@1+ (1.0,0) [0|15] "" Vector__XXX
 SG_ Supports_Equalization : 12|2@1+ (1.0,0) [0|3] "" Vector__XXX
 SG_ Nominal_Voltage : 16|4@1+ (1.0,0) [0|15] "" Vector__XXX
 SG_ Chemistry : 20|4@1+ (1.0,0) [0|15] "" Vector__XXX
 SG_ Capacity : 24|16@1+ (1.0,0) [0|65535] "Ah" Vector__XXX
 SG_ Temperature_Coefficient : 40|8@1- (1.0,0) [-128|127] "%" Vector__XXX
 SG_ Peukert_Exponent : 48|8@1+ (0.002,0) [1.0|1.5] "" Vector__XXX
 SG_ Charge_Efficiency_Factor : 56|8@1- (1.0,0) [-128|127] "%" Vector__XXX

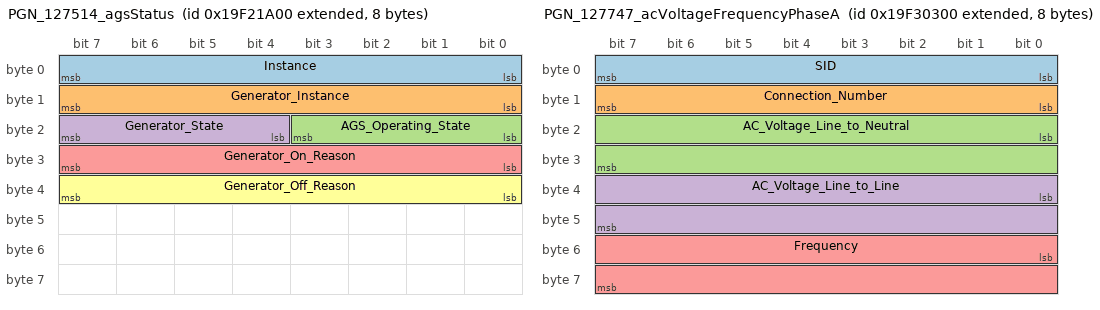
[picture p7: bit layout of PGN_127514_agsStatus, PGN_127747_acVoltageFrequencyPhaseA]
BO_ 2582780416 PGN_127514_agsStatus: 8 Vector__XXX
 SG_ Instance : 0|8@1+ (1.0,0) [0|255] "" Vector__XXX
 SG_ Generator_Instance : 8|8@1+ (1.0,0) [0|255] "" Vector__XXX
 SG_ AGS_Operating_State : 16|4@1+ (1.0,0) [0|15] "" Vector__XXX
 SG_ Generator_State : 20|4@1+ (1.0,0) [0|15] "" Vector__XXX
 SG_ Generator_On_Reason : 24|8@1+ (1.0,0) [0|255] "" Vector__XXX
 SG_ Generator_Off_Reason : 32|8@1+ (1.0,0) [0|255] "" Vector__XXX

BO_ 2582839296 PGN_127744_acPowerCurrentPhaseA: 8 Vector__XXX
 SG_ SID : 0|8@1+ (1.0,0) [0|255] "" Vector__XXX
 SG_ Connection_Number : 8|8@1+ (1.0,0) [0|255] "" Vector__XXX
 SG_ AC_RMS_Current : 16|16@1+ (0.1,0) [0.0|6553.5] "" Vector__XXX
 SG_ Power : 32|32@1- (1.0,0) [-2147483648|2147483647] "" Vector__XXX

BO_ 2582839552 PGN_127745_acPowerCurrentPhaseB: 8 Vector__XXX
 SG_ SID : 0|8@1+ (1.0,0) [0|255] "" Vector__XXX
 SG_ Connection_Number : 8|8@1+ (1.0,0) [0|255] "" Vector__XXX
 SG_ AC_RMS_Current : 16|16@1+ (0.1,0) [0.0|6553.5] "" Vector__XXX
 SG_ Power : 32|32@1- (1.0,0) [-2147483648|2147483647] "" Vector__XXX

BO_ 2582839808 PGN_127746_acPowerCurrentPhaseC: 8 Vector__XXX
 SG_ SID : 0|8@1+ (1.0,0) [0|255] "" Vector__XXX
 SG_ Connection_Number : 8|8@1+ (1.0,0) [0|255] "" Vector__XXX
 SG_ AC_RMS_Current : 16|16@1+ (0.1,0) [0.0|6553.5] "" Vector__XXX
 SG_ Power : 32|32@1- (1.0,0) [-2147483648|2147483647] "" Vector__XXX

BO_ 2582840064 PGN_127747_acVoltageFrequencyPhaseA: 8 Vector__XXX
 SG_ SID : 0|8@1+ (1.0,0) [0|255] "" Vector__XXX
 SG_ Connection_Number : 8|8@1+ (1.0,0) [0|255] "" Vector__XXX
 SG_ AC_Voltage_Line_to_Neutral : 16|16@1+ (0.1,0) [0.0|6553.5] "" Vector__XXX
 SG_ AC_Voltage_Line_to_Line : 32|16@1+ (0.1,0) [0.0|6553.5] "" Vector__XXX
 SG_ Frequency : 48|16@1+ (0.1,0) [0.0|6553.5] "" Vector__XXX

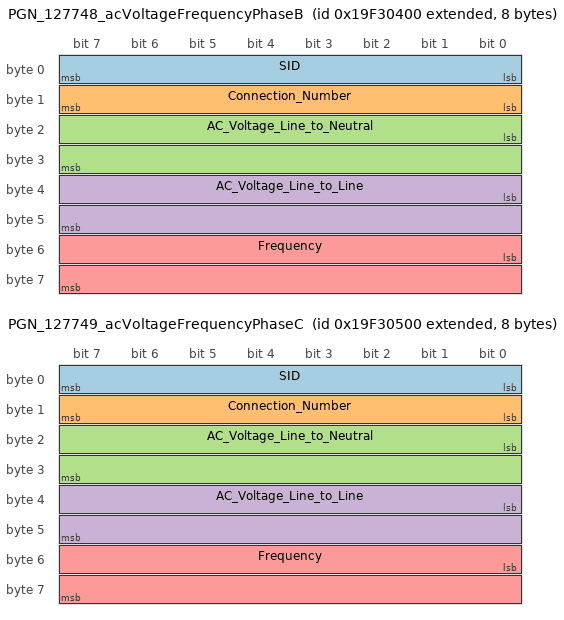
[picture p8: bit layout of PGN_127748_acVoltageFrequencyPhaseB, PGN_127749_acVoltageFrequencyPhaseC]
BO_ 2582840320 PGN_127748_acVoltageFrequencyPhaseB: 8 Vector__XXX
 SG_ SID : 0|8@1+ (1.0,0) [0|255] "" Vector__XXX
 SG_ Connection_Number : 8|8@1+ (1.0,0) [0|255] "" Vector__XXX
 SG_ AC_Voltage_Line_to_Neutral : 16|16@1+ (0.1,0) [0.0|6553.5] "" Vector__XXX
 SG_ AC_Voltage_Line_to_Line : 32|16@1+ (0.1,0) [0.0|6553.5] "" Vector__XXX
 SG_ Frequency : 48|16@1+ (0.1,0) [0.0|6553.5] "" Vector__XXX

BO_ 2582840576 PGN_127749_acVoltageFrequencyPhaseC: 8 Vector__XXX
 SG_ SID : 0|8@1+ (1.0,0) [0|255] "" Vector__XXX
 SG_ Connection_Number : 8|8@1+ (1.0,0) [0|255] "" Vector__XXX
 SG_ AC_Voltage_Line_to_Neutral : 16|16@1+ (0.1,0) [0.0|6553.5] "" Vector__XXX
 SG_ AC_Voltage_Line_to_Line : 32|16@1+ (0.1,0) [0.0|6553.5] "" Vector__XXX
 SG_ Frequency : 48|16@1+ (0.1,0) [0.0|6553.5] "" Vector__XXX

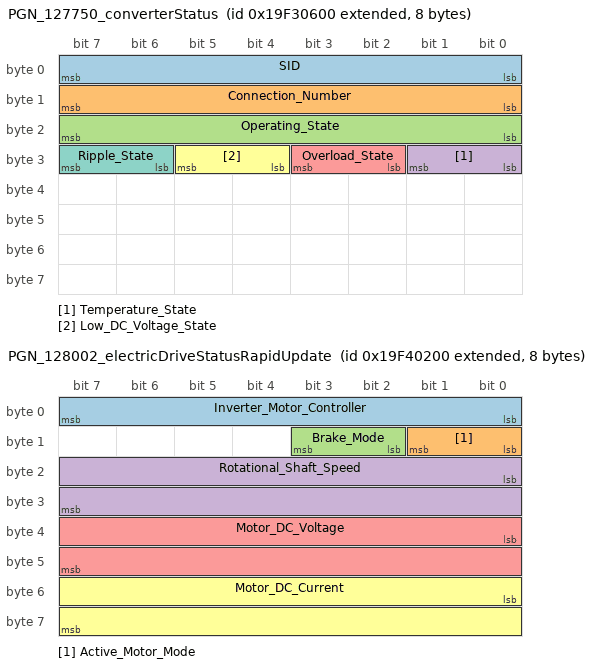
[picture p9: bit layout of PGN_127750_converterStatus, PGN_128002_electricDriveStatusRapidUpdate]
BO_ 2582840832 PGN_127750_converterStatus: 8 Vector__XXX
 SG_ SID : 0|8@1+ (1.0,0) [0|255] "" Vector__XXX
 SG_ Connection_Number : 8|8@1+ (1.0,0) [0|255] "" Vector__XXX
 SG_ Operating_State : 16|8@1+ (1.0,0) [0|255] "" Vector__XXX
 SG_ Temperature_State : 24|2@1+ (1.0,0) [0|3] "" Vector__XXX
 SG_ Overload_State : 26|2@1+ (1.0,0) [0|3] "" Vector__XXX
 SG_ Low_DC_Voltage_State : 28|2@1+ (1.0,0) [0|3] "" Vector__XXX
 SG_ Ripple_State : 30|2@1+ (1.0,0) [0|3] "" Vector__XXX

BO_ 2582841088 PGN_127751_dcVoltageCurrent: 8 Vector__XXX
 SG_ SID : 0|8@1+ (1.0,0) [0|255] "" Vector__XXX
 SG_ Connection_Number : 8|8@1+ (1.0,0) [0|255] "" Vector__XXX
 SG_ DC_Voltage : 16|16@1+ (0.1,0) [0.0|6553.5] "" Vector__XXX
 SG_ DC_Current : 32|24@1- (0.01,0) [-83886.08|83886.07] "" Vector__XXX

BO_ 2582904832 PGN_128000_leewayAngle: 8 Vector__XXX
 SG_ SID : 0|8@1+ (1.0,0) [0|255] "" Vector__XXX
 SG_ Leeway_Angle : 8|16@1- (0.0001,0) [-3.2768|3.2767] "" Vector__XXX

BO_ 2582905088 PGN_128001_vesselAcceleration: 8 Vector__XXX
 SG_ SID : 0|8@1+ (1.0,0) [0|255] "" Vector__XXX
 SG_ Longitudinal_Acceleration : 8|16@1- (1.0,0) [-32768|32767] "" Vector__XXX
 SG_ Transverse_Acceleration : 24|16@1- (1.0,0) [-32768|32767] "" Vector__XXX
 SG_ Vertical_Acceleration : 40|16@1- (1.0,0) [-32768|32767] "" Vector__XXX

BO_ 2582905344 PGN_128002_electricDriveStatusRapidUpdate: 8 Vector__XXX
 SG_ Inverter_Motor_Controller : 0|8@1+ (1.0,0) [0|255] "" Vector__XXX
 SG_ Active_Motor_Mode : 8|2@1+ (1.0,0) [0|3] "" Vector__XXX
 SG_ Brake_Mode : 10|2@1+ (1.0,0) [0|3] "" Vector__XXX
 SG_ Rotational_Shaft_Speed : 16|16@1+ (0.25,0) [0.0|16383.75] "rpm" Vector__XXX
 SG_ Motor_DC_Voltage : 32|16@1+ (0.1,0) [0.0|6553.5] "" Vector__XXX
 SG_ Motor_DC_Current : 48|16@1- (0.1,0) [-3276.8|3276.7000000000003] "" Vector__XXX

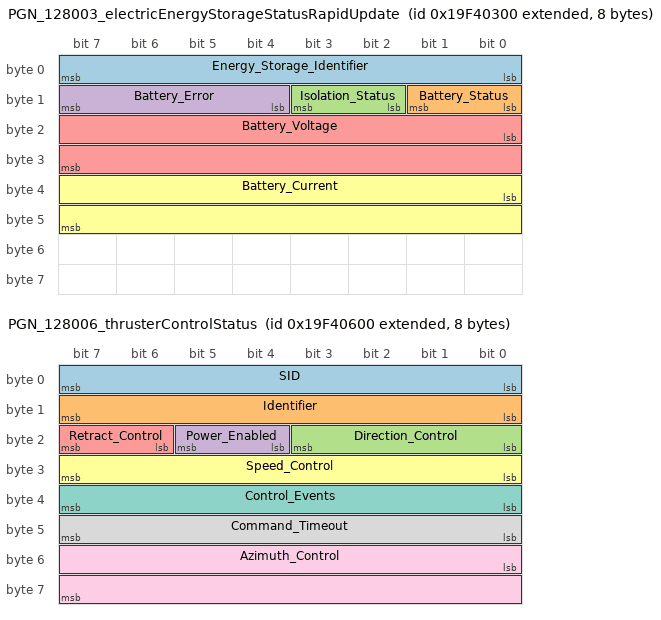
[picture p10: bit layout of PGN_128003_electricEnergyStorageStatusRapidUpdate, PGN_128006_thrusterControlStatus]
BO_ 2582905600 PGN_128003_electricEnergyStorageStatusRapidUpdate: 8 Vector__XXX
 SG_ Energy_Storage_Identifier : 0|8@1+ (1.0,0) [0|255] "" Vector__XXX
 SG_ Battery_Status : 8|2@1+ (1.0,0) [0|3] "" Vector__XXX
 SG_ Isolation_Status : 10|2@1+ (1.0,0) [0|3] "" Vector__XXX
 SG_ Battery_Error : 12|4@1+ (1.0,0) [0|15] "" Vector__XXX
 SG_ Battery_Voltage : 16|16@1+ (0.1,0) [0.0|6553.5] "" Vector__XXX
 SG_ Battery_Current : 32|16@1- (0.1,0) [-3276.8|3276.7000000000003] "" Vector__XXX

BO_ 2582906368 PGN_128006_thrusterControlStatus: 8 Vector__XXX
 SG_ SID : 0|8@1+ (1.0,0) [0|255] "" Vector__XXX
 SG_ Identifier : 8|8@1+ (1.0,0) [0|255] "" Vector__XXX
 SG_ Direction_Control : 16|4@1+ (1.0,0) [0|15] "" Vector__XXX
 SG_ Power_Enabled : 20|2@1+ (1.0,0) [0|3] "" Vector__XXX
 SG_ Retract_Control : 22|2@1+ (1.0,0) [0|3] "" Vector__XXX
 SG_ Speed_Control : 24|8@1+ (1.0,0) [0|255] "%" Vector__XXX
 SG_ Control_Events : 32|8@1+ (1.0,0) [0|255] "" Vector__XXX
 SG_ Command_Timeout : 40|8@1+ (0.005,0) [0.0|1.2750000000000001] "" Vector__XXX
 SG_ Azimuth_Control : 48|16@1+ (0.0001,0) [0.0|6.5535000000000005] "" Vector__XXX

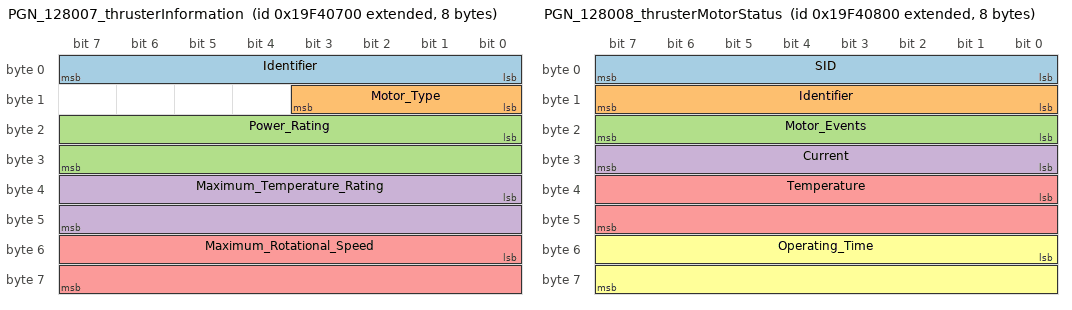
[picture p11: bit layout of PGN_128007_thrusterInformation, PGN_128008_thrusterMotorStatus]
BO_ 2582906624 PGN_128007_thrusterInformation: 8 Vector__XXX
 SG_ Identifier : 0|8@1+ (1.0,0) [0|255] "" Vector__XXX
 SG_ Motor_Type : 8|4@1+ (1.0,0) [0|15] "" Vector__XXX
 SG_ Power_Rating : 16|16@1+ (1.0,0) [0|65535] "" Vector__XXX
 SG_ Maximum_Temperature_Rating : 32|16@1+ (0.01,0) [0.0|655.35] "" Vector__XXX
 SG_ Maximum_Rotational_Speed : 48|16@1+ (0.25,0) [0.0|16383.75] "rpm" Vector__XXX

BO_ 2582906880 PGN_128008_thrusterMotorStatus: 8 Vector__XXX
 SG_ SID : 0|8@1+ (1.0,0) [0|255] "" Vector__XXX
 SG_ Identifier : 8|8@1+ (1.0,0) [0|255] "" Vector__XXX
 SG_ Motor_Events : 16|8@1+ (1.0,0) [0|255] "" Vector__XXX
 SG_ Current : 24|8@1+ (1.0,0) [0|255] "" Vector__XXX
 SG_ Temperature : 32|16@1+ (0.01,0) [0.0|655.35] "" Vector__XXX
 SG_ Operating_Time : 48|16@1+ (60.0,0) [0.0|3932100.0] "" Vector__XXX

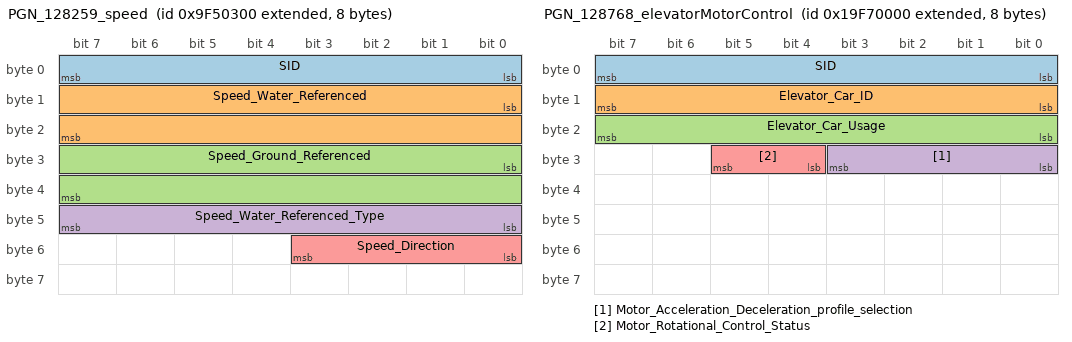
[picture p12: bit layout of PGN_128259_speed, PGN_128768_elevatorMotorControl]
BO_ 2314535680 PGN_128259_speed: 8 Vector__XXX
 SG_ SID : 0|8@1+ (1.0,0) [0|255] "" Vector__XXX
 SG_ Speed_Water_Referenced : 8|16@1+ (0.01,0) [0.0|655.35] "" Vector__XXX
 SG_ Speed_Ground_Referenced : 24|16@1+ (0.01,0) [0.0|655.35] "" Vector__XXX
 SG_ Speed_Water_Referenced_Type : 40|8@1+ (1.0,0) [0|255] "" Vector__XXX
 SG_ Speed_Direction : 48|4@1+ (1.0,0) [0|15] "" Vector__XXX

BO_ 2381646592 PGN_128267_waterDepth: 8 Vector__XXX
 SG_ SID : 0|8@1+ (1.0,0) [0|255] "" Vector__XXX
 SG_ Depth : 8|32@1+ (0.01,0) [0.0|42949672.95] "" Vector__XXX
 SG_ Offset : 40|16@1- (0.001,0) [-32.768|32.767] "" Vector__XXX
 SG_ Range : 56|8@1+ (10.0,0) [0.0|2550.0] "" Vector__XXX

BO_ 2582975232 PGN_128275_distanceLog: 14 Vector__XXX
 SG_ Date : 0|16@1+ (1.0,0) [0|65535] "" Vector__XXX
 SG_ Time : 16|32@1+ (0.0001,0) [0.0|86401.0] "" Vector__XXX
 SG_ Log : 48|32@1+ (1.0,0) [0|4294967295] "" Vector__XXX
 SG_ Trip_Log : 80|32@1+ (1.0,0) [0|4294967295] "" Vector__XXX

BO_ 2314602496 PGN_128520_trackedTargetData: 28 Vector__XXX
 SG_ SID : 0|8@1+ (1.0,0) [0|255] "" Vector__XXX
 SG_ Target_ID__ : 8|16@1+ (1.0,0) [0|65535] "" Vector__XXX
 SG_ Track_Status : 24|2@1+ (1.0,0) [0|3] "" Vector__XXX
 SG_ Reported_Target : 26|1@1+ (1.0,0) [0|1] "" Vector__XXX
 SG_ Target_Acquisition : 27|1@1+ (1.0,0) [0|1] "" Vector__XXX
 SG_ Bearing_Reference : 28|2@1+ (1.0,0) [0|3] "" Vector__XXX
 SG_ Bearing : 32|16@1+ (0.0001,0) [0.0|6.5535000000000005] "" Vector__XXX
 SG_ Distance : 48|32@1- (0.01,0) [-21474836.48|21474836.47] "" Vector__XXX
 SG_ Course : 80|16@1+ (0.0001,0) [0.0|6.5535000000000005] "" Vector__XXX
 SG_ Speed : 96|16@1+ (0.01,0) [0.0|655.35] "" Vector__XXX
 SG_ CPA : 112|32@1- (0.01,0) [-21474836.48|21474836.47] "" Vector__XXX
 SG_ TCPA : 144|32@1- (0.001,0) [-2147483.648|2147483.647] "" Vector__XXX
 SG_ UTC_of_Fix : 176|32@1+ (0.0001,0) [0.0|86401.0] "" Vector__XXX
 SG_ Name : 208|8@1+ (1.0,0) [0|255] "" Vector__XXX
 SG_ Reference_Target : 216|2@1+ (1.0,0) [0|3] "" Vector__XXX

BO_ 2583042560 PGN_128538_elevatorCarStatus: 22 Vector__XXX
 SG_ SID : 0|8@1+ (1.0,0) [0|255] "" Vector__XXX
 SG_ Elevator_Car_ID : 8|8@1+ (1.0,0) [0|255] "" Vector__XXX
 SG_ Elevator_Car_Usage : 16|8@1+ (1.0,0) [0|255] "" Vector__XXX
 SG_ Smoke_Sensor_Status : 24|2@1+ (1.0,0) [0|3] "" Vector__XXX
 SG_ Limit_Switch_Sensor_Status : 26|2@1+ (1.0,0) [0|3] "" Vector__XXX
 SG_ Proximity_Switch_Sensor_Status : 28|2@1+ (1.0,0) [0|3] "" Vector__XXX
 SG_ Inertial_Measurement_Unit__IMU__Sensor_Status : 30|2@1+ (1.0,0) [0|3] "" Vector__XXX
 SG_ Elevator_Load_Limit_Status : 32|2@1+ (1.0,0) [0|3] "" Vector__XXX
 SG_ Elevator_Load_Balance_Status : 34|2@1+ (1.0,0) [0|3] "" Vector__XXX
 SG_ Elevator_Load_Sensor_1_Status : 36|2@1+ (1.0,0) [0|3] "" Vector__XXX
 SG_ Elevator_Load_Sensor_2_Status : 38|2@1+ (1.0,0) [0|3] "" Vector__XXX
 SG_ Elevator_Load_Sensor_3_Status : 40|2@1+ (1.0,0) [0|3] "" Vector__XXX
 SG_ Elevator_Load_Sensor_4_Status : 42|2@1+ (1.0,0) [0|3] "" Vector__XXX
 SG_ Elevator_Car_Motion_Status : 48|2@1+ (1.0,0) [0|3] "" Vector__XXX
 SG_ Elevator_Car_Door_Status : 50|2@1+ (1.0,0) [0|3] "" Vector__XXX
 SG_ Elevator_Car_Emergency_Button_Status : 52|2@1+ (1.0,0) [0|3] "" Vector__XXX
 SG_ Elevator_Car_Buzzer_Status : 54|2@1+ (1.0,0) [0|3] "" Vector__XXX
 SG_ Open_Door_Button_Status : 56|2@1+ (1.0,0) [0|3] "" Vector__XXX
 SG_ Close_Door_Button_Status : 58|2@1+ (1.0,0) [0|3] "" Vector__XXX
 SG_ Current_Deck : 64|8@1+ (1.0,0) [0|255] "" Vector__XXX
 SG_ Destination_Deck : 72|8@1+ (1.0,0) [0|255] "" Vector__XXX
 SG_ Total_Number_of_Decks : 80|8@1+ (1.0,0) [0|255] "" Vector__XXX
 SG_ Weight_of_Load_Cell_1 : 88|16@1+ (1.0,0) [0|65535] "" Vector__XXX
 SG_ Weight_of_Load_Cell_2 : 104|16@1+ (1.0,0) [0|65535] "" Vector__XXX
 SG_ Weight_of_Load_Cell_3 : 120|16@1+ (1.0,0) [0|65535] "" Vector__XXX
 SG_ Weight_of_Load_Cell_4 : 136|16@1+ (1.0,0) [0|65535] "" Vector__XXX
 SG_ Speed_of_Elevator_Car : 152|16@1- (0.01,0) [-327.68|327.67] "" Vector__XXX
 SG_ Elevator_Brake_Status : 168|2@1+ (1.0,0) [0|3] "" Vector__XXX
 SG_ Elevator_Motor_rotation_control_Status : 170|2@1+ (1.0,0) [0|3] "" Vector__XXX

BO_ 2583101440 PGN_128768_elevatorMotorControl: 8 Vector__XXX
 SG_ SID : 0|8@1+ (1.0,0) [0|255] "" Vector__XXX
 SG_ Elevator_Car_ID : 8|8@1+ (1.0,0) [0|255] "" Vector__XXX
 SG_ Elevator_Car_Usage : 16|8@1+ (1.0,0) [0|255] "" Vector__XXX
 SG_ Motor_Acceleration_Deceleration_profile_selection : 24|4@1+ (1.0,0) [0|15] "" Vector__XXX
 SG_ Motor_Rotational_Control_Status : 28|2@1+ (1.0,0) [0|3] "" Vector__XXX

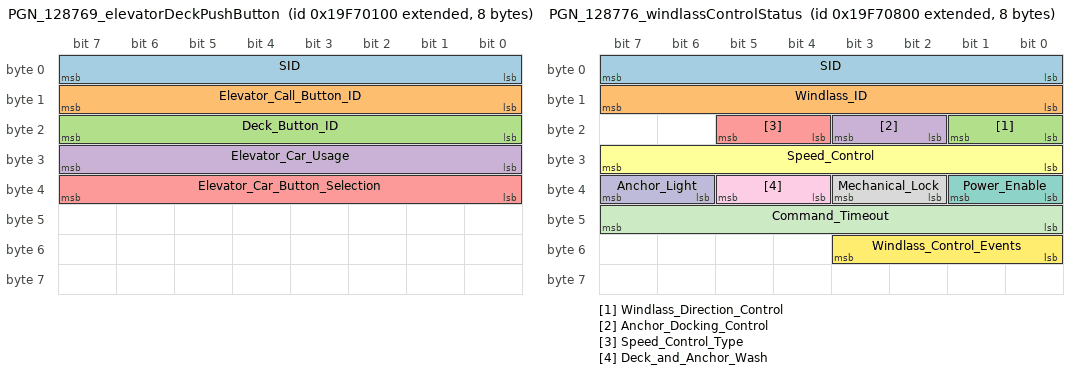
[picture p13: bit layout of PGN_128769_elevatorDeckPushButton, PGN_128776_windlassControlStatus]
BO_ 2583101696 PGN_128769_elevatorDeckPushButton: 8 Vector__XXX
 SG_ SID : 0|8@1+ (1.0,0) [0|255] "" Vector__XXX
 SG_ Elevator_Call_Button_ID : 8|8@1+ (1.0,0) [0|255] "" Vector__XXX
 SG_ Deck_Button_ID : 16|8@1+ (1.0,0) [0|255] "" Vector__XXX
 SG_ Elevator_Car_Usage : 24|8@1+ (1.0,0) [0|255] "" Vector__XXX
 SG_ Elevator_Car_Button_Selection : 32|8@1+ (1.0,0) [0|255] "" Vector__XXX

BO_ 2583103488 PGN_128776_windlassControlStatus: 8 Vector__XXX
 SG_ SID : 0|8@1+ (1.0,0) [0|255] "" Vector__XXX
 SG_ Windlass_ID : 8|8@1+ (1.0,0) [0|255] "" Vector__XXX
 SG_ Windlass_Direction_Control : 16|2@1+ (1.0,0) [0|3] "" Vector__XXX
 SG_ Anchor_Docking_Control : 18|2@1+ (1.0,0) [0|3] "" Vector__XXX
 SG_ Speed_Control_Type : 20|2@1+ (1.0,0) [0|3] "" Vector__XXX
 SG_ Speed_Control : 24|8@1+ (1.0,0) [0|255] "" Vector__XXX
 SG_ Power_Enable : 32|2@1+ (1.0,0) [0|3] "" Vector__XXX
 SG_ Mechanical_Lock : 34|2@1+ (1.0,0) [0|3] "" Vector__XXX
 SG_ Deck_and_Anchor_Wash : 36|2@1+ (1.0,0) [0|3] "" Vector__XXX
 SG_ Anchor_Light : 38|2@1+ (1.0,0) [0|3] "" Vector__XXX
 SG_ Command_Timeout : 40|8@1+ (0.005,0) [0.0|1.2750000000000001] "" Vector__XXX
 SG_ Windlass_Control_Events : 48|4@1+ (1.0,0) [0|15] "" Vector__XXX

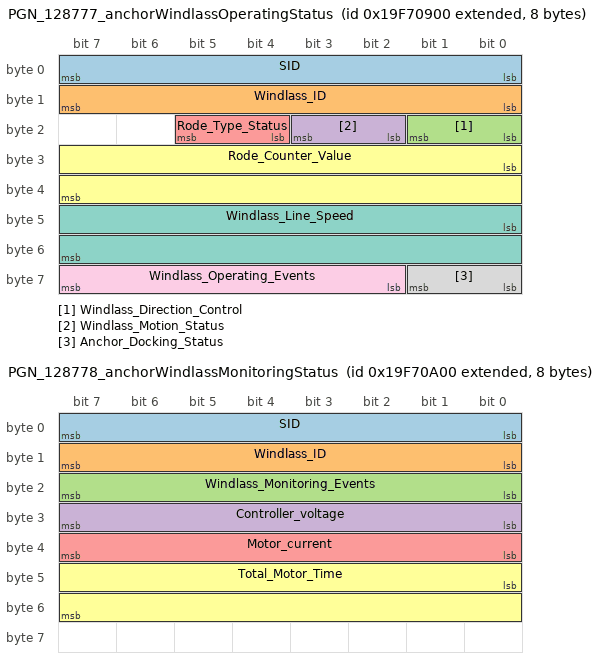
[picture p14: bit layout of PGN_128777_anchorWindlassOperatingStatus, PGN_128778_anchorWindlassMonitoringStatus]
BO_ 2583103744 PGN_128777_anchorWindlassOperatingStatus: 8 Vector__XXX
 SG_ SID : 0|8@1+ (1.0,0) [0|255] "" Vector__XXX
 SG_ Windlass_ID : 8|8@1+ (1.0,0) [0|255] "" Vector__XXX
 SG_ Windlass_Direction_Control : 16|2@1+ (1.0,0) [0|3] "" Vector__XXX
 SG_ Windlass_Motion_Status : 18|2@1+ (1.0,0) [0|3] "" Vector__XXX
 SG_ Rode_Type_Status : 20|2@1+ (1.0,0) [0|3] "" Vector__XXX
 SG_ Rode_Counter_Value : 24|16@1+ (0.1,0) [0.0|6553.5] "" Vector__XXX
 SG_ Windlass_Line_Speed : 40|16@1+ (0.01,0) [0.0|655.35] "" Vector__XXX
 SG_ Anchor_Docking_Status : 56|2@1+ (1.0,0) [0|3] "" Vector__XXX
 SG_ Windlass_Operating_Events : 58|6@1+ (1.0,0) [0|63] "" Vector__XXX

BO_ 2583104000 PGN_128778_anchorWindlassMonitoringStatus: 8 Vector__XXX
 SG_ SID : 0|8@1+ (1.0,0) [0|255] "" Vector__XXX
 SG_ Windlass_ID : 8|8@1+ (1.0,0) [0|255] "" Vector__XXX
 SG_ Windlass_Monitoring_Events : 16|8@1+ (1.0,0) [0|255] "" Vector__XXX
 SG_ Controller_voltage : 24|8@1+ (0.2,0) [0.0|51.0] "" Vector__XXX
 SG_ Motor_current : 32|8@1+ (1.0,0) [0|255] "" Vector__XXX
 SG_ Total_Motor_Time : 40|16@1+ (60.0,0) [0.0|3932100.0] "" Vector__XXX

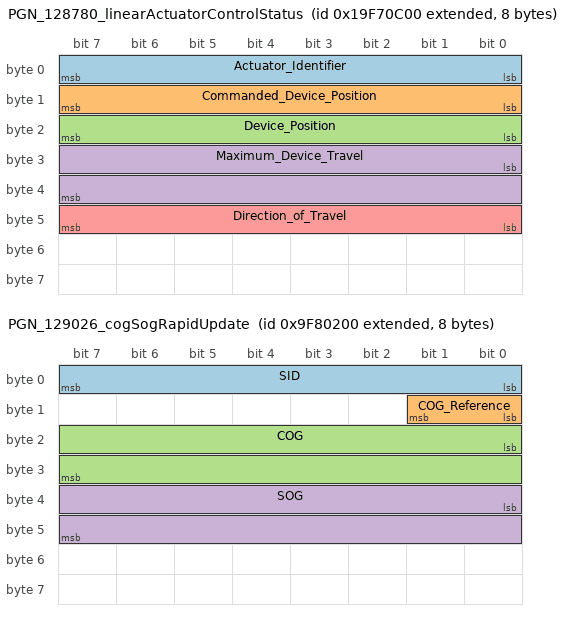
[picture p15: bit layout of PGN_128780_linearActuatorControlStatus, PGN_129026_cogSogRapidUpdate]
BO_ 2583104512 PGN_128780_linearActuatorControlStatus: 8 Vector__XXX
 SG_ Actuator_Identifier : 0|8@1+ (1.0,0) [0|255] "" Vector__XXX
 SG_ Commanded_Device_Position : 8|8@1+ (1.0,0) [0|255] "" Vector__XXX
 SG_ Device_Position : 16|8@1+ (1.0,0) [0|255] "" Vector__XXX
 SG_ Maximum_Device_Travel : 24|16@1+ (1.0,0) [0|65535] "" Vector__XXX
 SG_ Direction_of_Travel : 40|8@1+ (1.0,0) [0|255] "" Vector__XXX

BO_ 2314731776 PGN_129025_positionRapidUpdate: 8 Vector__XXX
 SG_ Latitude : 0|32@1- (1e-07,0) [-90.0|90.0] "" Vector__XXX
 SG_ Longitude : 32|32@1- (1e-07,0) [-180.0|180.0] "" Vector__XXX

BO_ 2314732032 PGN_129026_cogSogRapidUpdate: 8 Vector__XXX
 SG_ SID : 0|8@1+ (1.0,0) [0|255] "" Vector__XXX
 SG_ COG_Reference : 8|2@1+ (1.0,0) [0|3] "" Vector__XXX
 SG_ COG : 16|16@1+ (0.0001,0) [0.0|6.5535000000000005] "" Vector__XXX
 SG_ SOG : 32|16@1+ (0.01,0) [0.0|655.35] "" Vector__XXX

BO_ 2314732288 PGN_129027_positionDeltaRapidUpdate: 8 Vector__XXX
 SG_ SID : 0|8@1+ (1.0,0) [0|255] "" Vector__XXX
 SG_ Time_Delta : 8|8@1+ (0.005,0) [0.0|1.2750000000000001] "" Vector__XXX
 SG_ Latitude_Delta : 16|24@1- (2.777777777777778e-09,0) [-0.02330168888888889|0.023301686111111112] "deg" Vector__XXX
 SG_ Longitude_Delta : 40|24@1- (2.777777777777778e-09,0) [-0.02330168888888889|0.023301686111111112] "deg" Vector__XXX

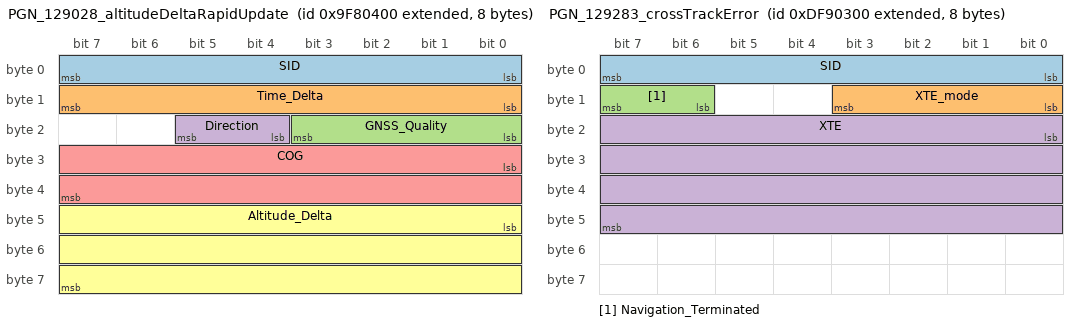
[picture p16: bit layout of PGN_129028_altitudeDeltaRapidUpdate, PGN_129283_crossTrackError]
BO_ 2314732544 PGN_129028_altitudeDeltaRapidUpdate: 8 Vector__XXX
 SG_ SID : 0|8@1+ (1.0,0) [0|255] "" Vector__XXX
 SG_ Time_Delta : 8|8@1+ (0.005,0) [0.0|1.2750000000000001] "" Vector__XXX
 SG_ GNSS_Quality : 16|4@1+ (1.0,0) [0|15] "" Vector__XXX
 SG_ Direction : 20|2@1+ (1.0,0) [0|3] "" Vector__XXX
 SG_ COG : 24|16@1+ (0.0001,0) [0.0|6.5535000000000005] "" Vector__XXX
 SG_ Altitude_Delta : 40|24@1- (0.001,0) [-8388.608|8388.607] "" Vector__XXX

BO_ 2381841664 PGN_129029_gnssPositionData: 44 Vector__XXX
 SG_ SID : 0|8@1+ (1.0,0) [0|255] "" Vector__XXX
 SG_ Date : 8|16@1+ (1.0,0) [0|65535] "" Vector__XXX
 SG_ Time : 24|32@1+ (0.0001,0) [0.0|86401.0] "" Vector__XXX
 SG_ Latitude : 56|64@1- (1e-16,0) [-90.0|90.0] "" Vector__XXX
 SG_ Longitude : 120|64@1- (1e-16,0) [-180.0|180.0] "" Vector__XXX
 SG_ Altitude : 184|64@1- (1e-06,0) [-9223372036854.775|9223372036854.775] "" Vector__XXX
 SG_ GNSS_type : 248|4@1+ (1.0,0) [0|15] "" Vector__XXX
 SG_ Method : 252|4@1+ (1.0,0) [0|15] "" Vector__XXX
 SG_ Integrity : 256|2@1+ (1.0,0) [0|3] "" Vector__XXX
 SG_ Number_of_SVs : 264|8@1+ (1.0,0) [0|255] "" Vector__XXX
 SG_ HDOP : 272|16@1- (0.01,0) [-327.68|327.67] "" Vector__XXX
 SG_ PDOP : 288|16@1- (0.01,0) [-327.68|327.67] "" Vector__XXX
 SG_ Geoidal_Separation : 304|32@1- (0.01,0) [-21474836.48|21474836.47] "" Vector__XXX
 SG_ Reference_Stations : 336|8@1+ (1.0,0) [0|255] "" Vector__XXX
 SG_ field344 : 344|8@1+ (1.0,0) [0|255] "" Vector__XXX

BO_ 2381842688 PGN_129033_timeDate: 8 Vector__XXX
 SG_ Date : 0|16@1+ (1.0,0) [0|65535] "" Vector__XXX
 SG_ Time : 16|32@1+ (0.0001,0) [0.0|86401.0] "" Vector__XXX
 SG_ Local_Offset : 48|16@1- (60.0,0) [-1966080.0|1966020.0] "" Vector__XXX

BO_ 2448952832 PGN_129038_aisClassAPositionReport: 28 Vector__XXX
 SG_ Message_ID : 0|6@1+ (1.0,0) [0|63] "" Vector__XXX
 SG_ Repeat_Indicator : 6|2@1+ (1.0,0) [0|3] "" Vector__XXX
 SG_ User_ID : 8|32@1+ (1.0,0) [2000000.0|999999999.0] "" Vector__XXX
 SG_ Longitude : 40|32@1- (1e-07,0) [-180.0|180.0] "" Vector__XXX
 SG_ Latitude : 72|32@1- (1e-07,0) [-90.0|90.0] "" Vector__XXX
 SG_ Position_Accuracy : 104|1@1+ (1.0,0) [0|1] "" Vector__XXX
 SG_ RAIM : 105|1@1+ (1.0,0) [0|1] "" Vector__XXX
 SG_ Time_Stamp : 106|6@1+ (1.0,0) [0|63] "" Vector__XXX
 SG_ COG : 112|16@1+ (0.0001,0) [0.0|6.5535000000000005] "" Vector__XXX
 SG_ SOG : 128|16@1+ (0.01,0) [0.0|655.35] "" Vector__XXX
 SG_ Communication_State : 144|19@1+ (1.0,0) [0|524287] "" Vector__XXX
 SG_ AIS_Transceiver_information : 163|5@1+ (1.0,0) [0|31] "" Vector__XXX
 SG_ Heading : 168|16@1+ (0.0001,0) [0.0|6.5535000000000005] "" Vector__XXX
 SG_ Rate_of_Turn : 184|16@1- (3.125e-05,0) [-1.024|1.02396875] "" Vector__XXX
 SG_ Nav_Status : 200|4@1+ (1.0,0) [0|15] "" Vector__XXX
 SG_ Special_Maneuver_Indicator : 204|2@1+ (1.0,0) [0|3] "" Vector__XXX
 SG_ Spare : 208|3@1+ (1.0,0) [0|7] "" Vector__XXX
 SG_ Sequence_ID : 216|8@1+ (1.0,0) [0|255] "" Vector__XXX

BO_ 2448953088 PGN_129039_aisClassBPositionReport: 27 Vector__XXX
 SG_ Message_ID : 0|6@1+ (1.0,0) [0|63] "" Vector__XXX
 SG_ Repeat_Indicator : 6|2@1+ (1.0,0) [0|3] "" Vector__XXX
 SG_ User_ID : 8|32@1+ (1.0,0) [2000000.0|999999999.0] "" Vector__XXX
 SG_ Longitude : 40|32@1- (1e-07,0) [-180.0|180.0] "" Vector__XXX
 SG_ Latitude : 72|32@1- (1e-07,0) [-90.0|90.0] "" Vector__XXX
 SG_ Position_Accuracy : 104|1@1+ (1.0,0) [0|1] "" Vector__XXX
 SG_ RAIM : 105|1@1+ (1.0,0) [0|1] "" Vector__XXX
 SG_ Time_Stamp : 106|6@1+ (1.0,0) [0|63] "" Vector__XXX
 SG_ COG : 112|16@1+ (0.0001,0) [0.0|6.5535000000000005] "" Vector__XXX
 SG_ SOG : 128|16@1+ (0.01,0) [0.0|655.35] "" Vector__XXX
 SG_ Communication_State : 144|19@1+ (1.0,0) [0|524287] "" Vector__XXX
 SG_ AIS_Transceiver_information : 163|5@1+ (1.0,0) [0|31] "" Vector__XXX
 SG_ Heading : 168|16@1+ (0.0001,0) [0.0|6.5535000000000005] "" Vector__XXX
 SG_ Regional_Application : 184|8@1+ (1.0,0) [0|255] "" Vector__XXX
 SG_ Regional_Application_B : 192|2@1+ (1.0,0) [0|3] "" Vector__XXX
 SG_ Unit_type : 194|1@1+ (1.0,0) [0|1] "" Vector__XXX
 SG_ Integrated_Display : 195|1@1+ (1.0,0) [0|1] "" Vector__XXX
 SG_ DSC : 196|1@1+ (1.0,0) [0|1] "" Vector__XXX
 SG_ Band : 197|1@1+ (1.0,0) [0|1] "" Vector__XXX
 SG_ Can_handle_Msg_22 : 198|1@1+ (1.0,0) [0|1] "" Vector__XXX
 SG_ AIS_mode : 199|1@1+ (1.0,0) [0|1] "" Vector__XXX
 SG_ AIS_communication_state : 200|1@1+ (1.0,0) [0|1] "" Vector__XXX
 SG_ Sequence_ID : 208|8@1+ (1.0,0) [0|255] "" Vector__XXX

BO_ 2448953344 PGN_129040_aisClassBExtendedPositionReport: 54 Vector__XXX
 SG_ Message_ID : 0|6@1+ (1.0,0) [0|63] "" Vector__XXX
 SG_ Repeat_Indicator : 6|2@1+ (1.0,0) [0|3] "" Vector__XXX
 SG_ User_ID : 8|32@1+ (1.0,0) [2000000.0|999999999.0] "" Vector__XXX
 SG_ Longitude : 40|32@1- (1e-07,0) [-180.0|180.0] "" Vector__XXX
 SG_ Latitude : 72|32@1- (1e-07,0) [-90.0|90.0] "" Vector__XXX
 SG_ Position_Accuracy : 104|1@1+ (1.0,0) [0|1] "" Vector__XXX
 SG_ RAIM : 105|1@1+ (1.0,0) [0|1] "" Vector__XXX
 SG_ Time_Stamp : 106|6@1+ (1.0,0) [0|63] "" Vector__XXX
 SG_ COG : 112|16@1+ (0.0001,0) [0.0|6.5535000000000005] "" Vector__XXX
 SG_ SOG : 128|16@1+ (0.01,0) [0.0|655.35] "" Vector__XXX
 SG_ Regional_Application : 144|8@1+ (1.0,0) [0|255] "" Vector__XXX
 SG_ Regional_Application_B : 152|4@1+ (1.0,0) [0|15] "" Vector__XXX
 SG_ Type_of_ship : 160|8@1+ (1.0,0) [0|255] "" Vector__XXX
 SG_ True_Heading : 168|16@1+ (0.0001,0) [0.0|6.5535000000000005] "" Vector__XXX
 SG_ GNSS_type : 188|4@1+ (1.0,0) [0|15] "" Vector__XXX
 SG_ Length : 192|16@1+ (0.1,0) [0.0|6553.5] "" Vector__XXX
 SG_ Beam : 208|16@1+ (0.1,0) [0.0|6553.5] "" Vector__XXX
 SG_ Position_reference_from_Starboard : 224|16@1+ (0.1,0) [0.0|6553.5] "" Vector__XXX
 SG_ Position_reference_from_Bow : 240|16@1+ (0.1,0) [0.0|6553.5] "" Vector__XXX
 SG_ Name : 256|160@1+ (1.0,0) [0|1461501637330902918203684832716283019655932542975] "" Vector__XXX
 SG_ DTE : 416|1@1+ (1.0,0) [0|1] "" Vector__XXX
 SG_ AIS_mode : 417|1@1+ (1.0,0) [0|1] "" Vector__XXX
 SG_ Spare : 418|4@1+ (1.0,0) [0|15] "" Vector__XXX
 SG_ AIS_Transceiver_information : 422|5@1+ (1.0,0) [0|31] "" Vector__XXX

BO_ 2448953600 PGN_129041_aisAidsToNavigationAtonReport: 27 Vector__XXX
 SG_ Message_ID : 0|6@1+ (1.0,0) [0|63] "" Vector__XXX
 SG_ Repeat_Indicator : 6|2@1+ (1.0,0) [0|3] "" Vector__XXX
 SG_ User_ID : 8|32@1+ (1.0,0) [2000000.0|999999999.0] "" Vector__XXX
 SG_ Longitude : 40|32@1- (1e-07,0) [-180.0|180.0] "" Vector__XXX
 SG_ Latitude : 72|32@1- (1e-07,0) [-90.0|90.0] "" Vector__XXX
 SG_ Position_Accuracy : 104|1@1+ (1.0,0) [0|1] "" Vector__XXX
 SG_ RAIM : 105|1@1+ (1.0,0) [0|1] "" Vector__XXX
 SG_ Time_Stamp : 106|6@1+ (1.0,0) [0|63] "" Vector__XXX
 SG_ Length_Diameter : 112|16@1+ (0.1,0) [0.0|6553.5] "" Vector__XXX
 SG_ Beam_Diameter : 128|16@1+ (0.1,0) [0.0|6553.5] "" Vector__XXX
 SG_ Position_Reference_from_Starboard_Edge : 144|16@1+ (0.1,0) [0.0|6553.5] "" Vector__XXX
 SG_ Position_Reference_from_True_North_Facing_Edge : 160|16@1+ (0.1,0) [0.0|6553.5] "" Vector__XXX
 SG_ AtoN_Type : 176|5@1+ (1.0,0) [0|31] "" Vector__XXX
 SG_ Off_Position_Indicator : 181|1@1+ (1.0,0) [0|1] "" Vector__XXX
 SG_ Virtual_AtoN_Flag : 182|1@1+ (1.0,0) [0|1] "" Vector__XXX
 SG_ Assigned_Mode_Flag : 183|1@1+ (1.0,0) [0|1] "" Vector__XXX
 SG_ Spare : 184|1@1+ (1.0,0) [0|1] "" Vector__XXX
 SG_ Position_Fixing_Device_Type : 185|4@1+ (1.0,0) [0|15] "" Vector__XXX
 SG_ AtoN_Status : 192|8@1+ (1.0,0) [0|255] "" Vector__XXX
 SG_ AIS_Transceiver_information : 200|5@1+ (1.0,0) [0|31] "" Vector__XXX
 SG_ AtoN_Name : 208|8@1+ (1.0,0) [0|255] "" Vector__XXX

BO_ 2583172096 PGN_129044_datum: 20 Vector__XXX
 SG_ Local_Datum : 0|32@1+ (1.0,0) [0|4294967295] "" Vector__XXX
 SG_ Delta_Latitude : 32|32@1- (1e-07,0) [-90.0|90.0] "" Vector__XXX
 SG_ Delta_Longitude : 64|32@1- (1e-07,0) [-180.0|180.0] "" Vector__XXX
 SG_ Delta_Altitude : 96|32@1- (0.01,0) [-21474836.48|21474836.47] "" Vector__XXX
 SG_ Reference_Datum : 128|32@1+ (1.0,0) [0|4294967295] "" Vector__XXX

BO_ 2583172352 PGN_129045_userDatum: 40 Vector__XXX
 SG_ Delta_X : 0|32@1- (0.01,0) [-21474836.48|21474836.47] "" Vector__XXX
 SG_ Delta_Y : 32|32@1- (0.01,0) [-21474836.48|21474836.47] "" Vector__XXX
 SG_ Delta_Z : 64|32@1- (0.01,0) [-21474836.48|21474836.47] "" Vector__XXX
 SG_ Rotation_in_X : 96|32@1- (1.0,0) [-2147483648|2147483647] "rad" Vector__XXX
 SG_ Rotation_in_Y : 128|32@1- (1.0,0) [-2147483648|2147483647] "rad" Vector__XXX
 SG_ Rotation_in_Z : 160|32@1- (1.0,0) [-2147483648|2147483647] "rad" Vector__XXX
 SG_ Scale : 192|32@1- (1.0,0) [-3.40282346638529e+38|3.40282346638529e+38] "ppm" Vector__XXX
 SG_ Ellipsoid_Semi_major_Axis : 224|32@1- (0.01,0) [-21474836.48|21474836.47] "" Vector__XXX
 SG_ Ellipsoid_Flattening_Inverse : 256|32@1- (1.0,0) [-3.40282346638529e+38|3.40282346638529e+38] "" Vector__XXX
 SG_ Datum_Name : 288|32@1+ (1.0,0) [0|4294967295] "" Vector__XXX

BO_ 2381906688 PGN_129283_crossTrackError: 8 Vector__XXX
 SG_ SID : 0|8@1+ (1.0,0) [0|255] "" Vector__XXX
 SG_ XTE_mode : 8|4@1+ (1.0,0) [0|15] "" Vector__XXX
 SG_ Navigation_Terminated : 14|2@1+ (1.0,0) [0|3] "" Vector__XXX
 SG_ XTE : 16|32@1- (0.01,0) [-21474836.48|21474836.47] "" Vector__XXX

BO_ 2381906944 PGN_129284_navigationData: 34 Vector__XXX
 SG_ SID : 0|8@1+ (1.0,0) [0|255] "" Vector__XXX
 SG_ Distance_to_Waypoint : 8|32@1+ (0.01,0) [0.0|42949672.95] "" Vector__XXX
 SG_ Course_Bearing_reference : 40|2@1+ (1.0,0) [0|3] "" Vector__XXX
 SG_ Perpendicular_Crossed : 42|2@1+ (1.0,0) [0|3] "" Vector__XXX
 SG_ Arrival_Circle_Entered : 44|2@1+ (1.0,0) [0|3] "" Vector__XXX
 SG_ Calculation_Type : 46|2@1+ (1.0,0) [0|3] "" Vector__XXX
 SG_ ETA_Time : 48|32@1+ (0.0001,0) [0.0|86401.0] "" Vector__XXX
 SG_ ETA_Date : 80|16@1+ (1.0,0) [0|65535] "" Vector__XXX
 SG_ Bearing__Origin_to_Destination_Waypoint : 96|16@1+ (0.0001,0) [0.0|6.5535000000000005] "" Vector__XXX
 SG_ Bearing__Position_to_Destination_Waypoint : 112|16@1+ (0.0001,0) [0.0|6.5535000000000005] "" Vector__XXX
 SG_ Origin_Waypoint_Number : 128|32@1+ (1.0,0) [0|4294967295] "" Vector__XXX
 SG_ Destination_Waypoint_Number : 160|32@1+ (1.0,0) [0|4294967295] "" Vector__XXX
 SG_ Destination_Latitude : 192|32@1- (1e-07,0) [-90.0|90.0] "" Vector__XXX
 SG_ Destination_Longitude : 224|32@1- (1e-07,0) [-180.0|180.0] "" Vector__XXX
 SG_ Waypoint_Closing_Velocity : 256|16@1- (0.01,0) [-327.68|327.67] "" Vector__XXX

BO_ 2583233792 PGN_129285_navigationRouteWpInformation: 12 Vector__XXX
 SG_ Start_RPS_ : 0|16@1+ (1.0,0) [0|65535] "" Vector__XXX
 SG_ nItems : 16|16@1+ (1.0,0) [0|65535] "" Vector__XXX
 SG_ Database_ID : 32|16@1+ (1.0,0) [0|65535] "" Vector__XXX
 SG_ Route_ID : 48|16@1+ (1.0,0) [0|65535] "" Vector__XXX
 SG_ Navigation_direction_in_route : 64|3@1+ (1.0,0) [0|7] "" Vector__XXX
 SG_ Supplementary_Route_WP_data_available : 67|2@1+ (1.0,0) [0|3] "" Vector__XXX
 SG_ Route_Name : 72|8@1+ (1.0,0) [0|255] "" Vector__XXX
 SG_ field88 : 88|8@1+ (1.0,0) [0|255] "" Vector__XXX

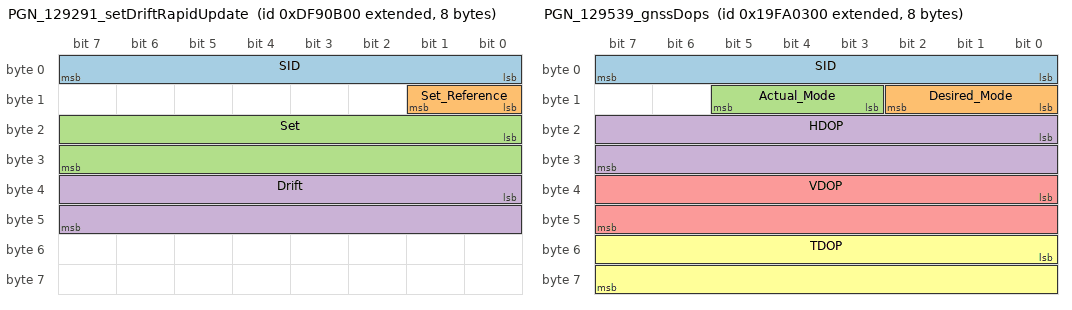
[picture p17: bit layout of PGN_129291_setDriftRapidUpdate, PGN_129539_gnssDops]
BO_ 2381908736 PGN_129291_setDriftRapidUpdate: 8 Vector__XXX
 SG_ SID : 0|8@1+ (1.0,0) [0|255] "" Vector__XXX
 SG_ Set_Reference : 8|2@1+ (1.0,0) [0|3] "" Vector__XXX
 SG_ Set : 16|16@1+ (0.0001,0) [0.0|6.5535000000000005] "" Vector__XXX
 SG_ Drift : 32|16@1+ (0.01,0) [0.0|655.35] "" Vector__XXX

BO_ 2381911296 PGN_129301_navigationRouteTimeToFromMark: 10 Vector__XXX
 SG_ SID : 0|8@1+ (1.0,0) [0|255] "" Vector__XXX
 SG_ Time_to_mark : 8|32@1- (0.001,0) [-2147483.648|2147483.647] "" Vector__XXX
 SG_ Mark_Type : 40|4@1+ (1.0,0) [0|15] "" Vector__XXX
 SG_ Mark_ID : 48|32@1+ (1.0,0) [0|4294967295] "" Vector__XXX

BO_ 2583238144 PGN_129302_bearingAndDistanceBetweenTwoMarks: 17 Vector__XXX
 SG_ SID : 0|8@1+ (1.0,0) [0|255] "" Vector__XXX
 SG_ Bearing_Reference : 8|2@1+ (1.0,0) [0|3] "" Vector__XXX
 SG_ Calculation_Type : 10|2@1+ (1.0,0) [0|3] "" Vector__XXX
 SG_ Bearing__Origin_to_Destination : 16|16@1+ (0.0001,0) [0.0|6.5535000000000005] "" Vector__XXX
 SG_ Distance : 32|32@1+ (0.01,0) [0.0|42949672.95] "" Vector__XXX
 SG_ Origin_Mark_Type : 64|4@1+ (1.0,0) [0|15] "" Vector__XXX
 SG_ Destination_Mark_Type : 68|4@1+ (1.0,0) [0|15] "" Vector__XXX
 SG_ Origin_Mark_ID : 72|32@1+ (1.0,0) [0|4294967295] "" Vector__XXX
 SG_ Destination_Mark_ID : 104|32@1+ (1.0,0) [0|4294967295] "" Vector__XXX

BO_ 2583298560 PGN_129538_gnssControlStatus: 16 Vector__XXX
 SG_ SV_Elevation_Mask : 0|16@1- (0.0001,0) [-3.2768|3.2767] "" Vector__XXX
 SG_ PDOP_Mask : 16|16@1- (0.01,0) [-327.68|327.67] "" Vector__XXX
 SG_ PDOP_Switch : 32|16@1- (0.01,0) [-327.68|327.67] "" Vector__XXX
 SG_ SNR_Mask : 48|16@1- (0.01,0) [-327.68|327.67] "" Vector__XXX
 SG_ GNSS_Mode__desired_ : 64|3@1+ (1.0,0) [0|7] "" Vector__XXX
 SG_ DGNSS_Mode__desired_ : 67|3@1+ (1.0,0) [0|7] "" Vector__XXX
 SG_ Position_Velocity_Filter : 70|2@1+ (1.0,0) [0|3] "" Vector__XXX
 SG_ Max_Correction_Age : 72|16@1+ (0.01,0) [0.0|655.35] "" Vector__XXX
 SG_ Antenna_Altitude_for_2D_Mode : 88|32@1- (0.01,0) [-21474836.48|21474836.47] "" Vector__XXX
 SG_ Use_Antenna_Altitude_for_2D_Mode : 120|2@1+ (1.0,0) [0|3] "" Vector__XXX

BO_ 2583298816 PGN_129539_gnssDops: 8 Vector__XXX
 SG_ SID : 0|8@1+ (1.0,0) [0|255] "" Vector__XXX
 SG_ Desired_Mode : 8|3@1+ (1.0,0) [0|7] "" Vector__XXX
 SG_ Actual_Mode : 11|3@1+ (1.0,0) [0|7] "" Vector__XXX
 SG_ HDOP : 16|16@1- (0.01,0) [-327.68|327.67] "" Vector__XXX
 SG_ VDOP : 32|16@1- (0.01,0) [-327.68|327.67] "" Vector__XXX
 SG_ TDOP : 48|16@1- (0.01,0) [-327.68|327.67] "" Vector__XXX

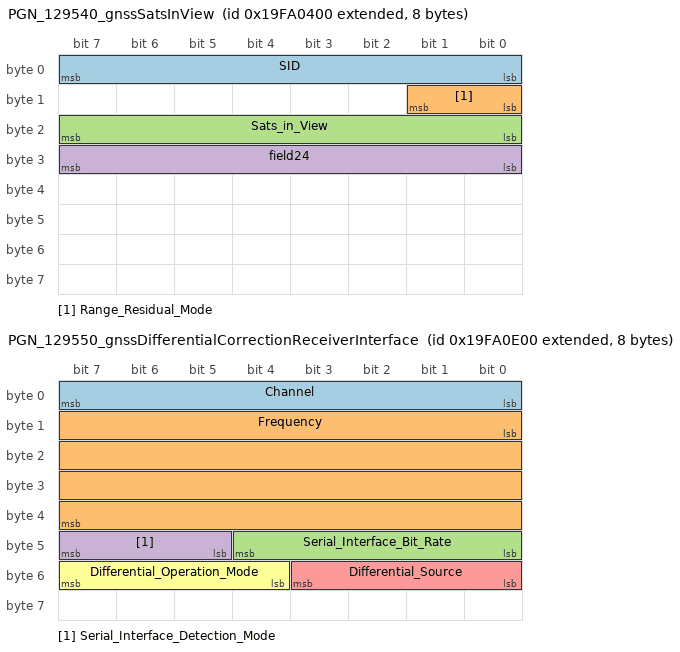
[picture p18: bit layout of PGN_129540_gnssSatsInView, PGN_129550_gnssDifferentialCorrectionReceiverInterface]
BO_ 2583299072 PGN_129540_gnssSatsInView: 8 Vector__XXX
 SG_ SID : 0|8@1+ (1.0,0) [0|255] "" Vector__XXX
 SG_ Range_Residual_Mode : 8|2@1+ (1.0,0) [0|3] "" Vector__XXX
 SG_ Sats_in_View : 16|8@1+ (1.0,0) [0|255] "" Vector__XXX
 SG_ field24 : 24|8@1+ (1.0,0) [0|255] "" Vector__XXX

BO_ 2583299328 PGN_129541_gpsAlmanacData: 26 Vector__XXX
 SG_ PRN : 0|8@1+ (1.0,0) [0|255] "" Vector__XXX
 SG_ GPS_Week_number : 8|16@1+ (1.0,0) [0|65535] "" Vector__XXX
 SG_ SV_Health_Bits : 24|8@1+ (1.0,0) [0|255] "" Vector__XXX
 SG_ Eccentricity : 32|16@1+ (4.76837158203125e-07,0) [0.0|0.031249523162841797] "m/m" Vector__XXX
 SG_ Almanac_Reference_Time : 48|8@1+ (4096.0,0) [0.0|1044480.0] "s" Vector__XXX
 SG_ Inclination_Angle : 56|16@1- (1.9073486328125e-06,0) [-0.0625|0.06249809265136719] "semi-circle" Vector__XXX
 SG_ Rate_of_Right_Ascension : 72|16@1- (3.637978807091713e-12,0) [-1.1920928955078125e-07|1.1920565157197416e-07] "semi-circle/s" Vector__XXX
 SG_ Root_of_Semi_major_Axis : 88|24@1+ (0.00048828125,0) [0.0|8191.99951171875] "sqrt(m)" Vector__XXX
 SG_ Argument_of_Perigee : 112|24@1- (1.1920928955078125e-07,0) [-1.0|0.9999998807907104] "semi-circle" Vector__XXX
 SG_ Longitude_of_Ascension_Node : 136|24@1- (1.1920928955078125e-07,0) [-1.0|0.9999998807907104] "semi-circle" Vector__XXX
 SG_ Mean_Anomaly : 160|24@1- (1.1920928955078125e-07,0) [-1.0|0.9999998807907104] "semi-circle" Vector__XXX
 SG_ Clock_Parameter_1 : 184|11@1- (9.5367431640625e-07,0) [-0.0009765625|0.0009756088256835938] "s" Vector__XXX
 SG_ Clock_Parameter_2 : 195|11@1- (3.637978807091713e-12,0) [-3.725290298461914e-09|3.7216523196548223e-09] "s/s" Vector__XXX

BO_ 2583299584 PGN_129542_gnssPseudorangeNoiseStatistics: 15 Vector__XXX
 SG_ SID : 0|8@1+ (1.0,0) [0|255] "" Vector__XXX
 SG_ RMS_of_Position_Uncertainty : 8|16@1+ (0.01,0) [0.0|655.35] "" Vector__XXX
 SG_ STD_of_Major_axis : 24|16@1+ (0.01,0) [0.0|655.35] "" Vector__XXX
 SG_ STD_of_Minor_axis : 40|16@1+ (0.01,0) [0.0|655.35] "" Vector__XXX
 SG_ Orientation_of_Major_axis : 56|16@1+ (0.0001,0) [0.0|6.5535000000000005] "" Vector__XXX
 SG_ STD_of_Lat_Error : 72|16@1+ (0.01,0) [0.0|655.35] "" Vector__XXX
 SG_ STD_of_Lon_Error : 88|16@1+ (0.01,0) [0.0|655.35] "" Vector__XXX
 SG_ STD_of_Alt_Error : 104|16@1+ (0.01,0) [0.0|655.35] "" Vector__XXX

BO_ 2583300352 PGN_129545_gnssRaimOutput: 15 Vector__XXX
 SG_ SID : 0|8@1+ (1.0,0) [0|255] "" Vector__XXX
 SG_ Integrity_flag : 8|2@1+ (1.0,0) [0|3] "" Vector__XXX
 SG_ Latitude_expected_error : 16|16@1- (0.01,0) [-327.68|327.67] "" Vector__XXX
 SG_ Longitude_expected_error : 32|16@1- (0.01,0) [-327.68|327.67] "" Vector__XXX
 SG_ Altitude_expected_error : 48|16@1- (0.01,0) [-327.68|327.67] "" Vector__XXX
 SG_ SV_ID_of_most_likely_failed_sat : 64|8@1+ (1.0,0) [0|255] "" Vector__XXX
 SG_ Probability_of_missed_detection : 72|16@1- (0.01,0) [-327.68|327.67] "" Vector__XXX
 SG_ Estimate_of_pseudorange_bias : 88|16@1- (0.01,0) [-327.68|327.67] "" Vector__XXX
 SG_ Std_Deviation_of_bias : 104|16@1- (0.01,0) [-327.68|327.67] "" Vector__XXX

BO_ 2583300608 PGN_129546_gnssRaimSettings: 8 Vector__XXX
 SG_ Radial_Position_Error_Maximum_Threshold : 0|16@1+ (0.01,0) [0.0|655.35] "" Vector__XXX
 SG_ Probability_of_False_Alarm : 16|8@1- (1.0,0) [-128|127] "%" Vector__XXX
 SG_ Probability_of_Missed_Detection : 24|8@1- (1.0,0) [-128|127] "%" Vector__XXX
 SG_ Pseudorange_Residual_Filtering_Time_Constant : 32|16@1+ (1.0,0) [0|65535] "" Vector__XXX

BO_ 2583300864 PGN_129547_gnssPseudorangeErrorStatistics: 15 Vector__XXX
 SG_ SID : 0|8@1+ (1.0,0) [0|255] "" Vector__XXX
 SG_ RMS_Std_Dev_of_Range_Inputs : 8|16@1+ (0.01,0) [0.0|655.35] "" Vector__XXX
 SG_ Std_Dev_of_Major_error_ellipse : 24|16@1+ (0.01,0) [0.0|655.35] "" Vector__XXX
 SG_ Std_Dev_of_Minor_error_ellipse : 40|16@1+ (0.01,0) [0.0|655.35] "" Vector__XXX
 SG_ Orientation_of_error_ellipse : 56|16@1+ (0.0001,0) [0.0|6.5535000000000005] "" Vector__XXX
 SG_ Std_Dev_Lat_Error : 72|16@1+ (0.01,0) [0.0|655.35] "" Vector__XXX
 SG_ Std_Dev_Lon_Error : 88|16@1+ (0.01,0) [0.0|655.35] "" Vector__XXX
 SG_ Std_Dev_Alt_Error : 104|16@1+ (0.01,0) [0.0|655.35] "" Vector__XXX

BO_ 2583301376 PGN_129549_dgnssCorrections: 16 Vector__XXX
 SG_ SID : 0|8@1+ (1.0,0) [0|255] "" Vector__XXX
 SG_ Reference_Station_ID : 8|12@1+ (1.0,0) [0|4095] "" Vector__XXX
 SG_ Reference_Station_Type : 20|4@1+ (1.0,0) [0|15] "" Vector__XXX
 SG_ Time_of_corrections : 24|16@1+ (0.1,0) [0.0|6553.5] "" Vector__XXX
 SG_ Station_Health : 40|4@1+ (1.0,0) [0|15] "" Vector__XXX
 SG_ Satellite_ID : 48|8@1+ (1.0,0) [0|255] "" Vector__XXX
 SG_ PRC : 56|32@1- (0.0001,0) [-214748.3648|214748.3647] "" Vector__XXX
 SG_ RRC : 88|16@1- (0.0001,0) [-3.2768|3.2767] "" Vector__XXX
 SG_ UDRE : 104|16@1+ (0.01,0) [0.0|655.35] "" Vector__XXX
 SG_ IOD : 120|8@1+ (1.0,0) [0|255] "" Vector__XXX

BO_ 2583301632 PGN_129550_gnssDifferentialCorrectionReceiverInterface: 8 Vector__XXX
 SG_ Channel : 0|8@1+ (1.0,0) [0|255] "" Vector__XXX
 SG_ Frequency : 8|32@1+ (10.0,0) [0.0|42949672950.0] "" Vector__XXX
 SG_ Serial_Interface_Bit_Rate : 40|5@1+ (1.0,0) [0|31] "" Vector__XXX
 SG_ Serial_Interface_Detection_Mode : 45|3@1+ (1.0,0) [0|7] "" Vector__XXX
 SG_ Differential_Source : 48|4@1+ (1.0,0) [0|15] "" Vector__XXX
 SG_ Differential_Operation_Mode : 52|4@1+ (1.0,0) [0|15] "" Vector__XXX

BO_ 2583301888 PGN_129551_gnssDifferentialCorrectionReceiverSignal: 20 Vector__XXX
 SG_ SID : 0|8@1+ (1.0,0) [0|255] "" Vector__XXX
 SG_ Channel : 8|8@1+ (1.0,0) [0|255] "" Vector__XXX
 SG_ Signal_Strength : 16|32@1- (0.01,0) [-21474836.48|21474836.47] "" Vector__XXX
 SG_ Signal_SNR : 48|16@1- (0.01,0) [-327.68|327.67] "" Vector__XXX
 SG_ Frequency : 64|32@1+ (10.0,0) [0.0|42949672950.0] "" Vector__XXX
 SG_ Station_Type : 96|4@1+ (1.0,0) [0|15] "" Vector__XXX
 SG_ Reference_Station_ID : 100|12@1+ (1.0,0) [0|4095] "" Vector__XXX
 SG_ Differential_Signal_Bit_Rate : 112|5@1+ (1.0,0) [0|31] "" Vector__XXX
 SG_ Differential_Signal_Detection_Mode : 117|3@1+ (1.0,0) [0|7] "" Vector__XXX
 SG_ Used_as_Correction_Source : 120|2@1+ (1.0,0) [0|3] "" Vector__XXX
 SG_ Differential_Source : 124|4@1+ (1.0,0) [0|15] "" Vector__XXX
 SG_ Time_since_Last_Sat_Differential_Sync : 128|16@1+ (0.01,0) [0.0|655.35] "" Vector__XXX
 SG_ Satellite_Service_ID_No_ : 144|16@1+ (1.0,0) [0|65535] "" Vector__XXX

BO_ 2583303168 PGN_129556_glonassAlmanacData: 26 Vector__XXX
 SG_ PRN : 0|8@1+ (1.0,0) [0|255] "" Vector__XXX
 SG_ NA : 8|16@1+ (1.0,0) [0|65535] "" Vector__XXX
 SG_ CnA : 26|1@1+ (1.0,0) [0|1] "" Vector__XXX
 SG_ HnA : 27|5@1+ (1.0,0) [0|31] "" Vector__XXX
 SG_ _epsilon_nA : 32|16@1+ (1.0,0) [0|65535] "" Vector__XXX
 SG_ _deltaTnA_DOT : 48|8@1+ (1.0,0) [0|255] "" Vector__XXX
 SG_ _omega_nA : 56|16@1+ (1.0,0) [0|65535] "" Vector__XXX
 SG_ _delta_TnA : 72|24@1+ (1.0,0) [0|16777215] "" Vector__XXX
 SG_ tnA : 96|24@1+ (1.0,0) [0|16777215] "" Vector__XXX
 SG_ _lambda_nA : 120|24@1+ (1.0,0) [0|16777215] "" Vector__XXX
 SG_ _delta_inA : 144|24@1+ (1.0,0) [0|16777215] "" Vector__XXX
 SG_ _tau_cA : 168|28@1+ (1.0,0) [0|268435455] "" Vector__XXX
 SG_ _tau_nA : 196|12@1+ (1.0,0) [0|4095] "" Vector__XXX

BO_ 2583363584 PGN_129792_aisDgnssBroadcastBinaryMessage: 18 Vector__XXX
 SG_ Message_ID : 0|6@1+ (1.0,0) [0|63] "" Vector__XXX
 SG_ Repeat_Indicator : 6|2@1+ (1.0,0) [0|3] "" Vector__XXX
 SG_ Source_ID : 8|32@1+ (1.0,0) [2000000.0|999999999.0] "" Vector__XXX
 SG_ AIS_Transceiver_information : 41|5@1+ (1.0,0) [0|31] "" Vector__XXX
 SG_ Spare : 46|2@1+ (1.0,0) [0|3] "" Vector__XXX
 SG_ Longitude : 48|32@1- (1e-07,0) [-180.0|180.0] "" Vector__XXX
 SG_ Latitude : 80|32@1- (1e-07,0) [-90.0|90.0] "" Vector__XXX
 SG_ Spare_1 : 115|5@1+ (1.0,0) [0|31] "" Vector__XXX
 SG_ Number_of_Bits_in_Binary_Data_Field : 120|16@1+ (1.0,0) [0|65535] "" Vector__XXX
 SG_ Binary_Data : 136|8@1+ (1.0,0) [0|255] "" Vector__XXX

BO_ 2650472704 PGN_129793_aisUtcAndDateReport: 27 Vector__XXX
 SG_ Message_ID : 0|6@1+ (1.0,0) [0|63] "" Vector__XXX
 SG_ Repeat_Indicator : 6|2@1+ (1.0,0) [0|3] "" Vector__XXX
 SG_ User_ID : 8|32@1+ (1.0,0) [2000000.0|999999999.0] "" Vector__XXX
 SG_ Longitude : 40|32@1- (1e-07,0) [-180.0|180.0] "" Vector__XXX
 SG_ Latitude : 72|32@1- (1e-07,0) [-90.0|90.0] "" Vector__XXX
 SG_ Position_Accuracy : 104|1@1+ (1.0,0) [0|1] "" Vector__XXX
 SG_ RAIM : 105|1@1+ (1.0,0) [0|1] "" Vector__XXX
 SG_ Position_Time : 112|32@1+ (0.0001,0) [0.0|86401.0] "" Vector__XXX
 SG_ Communication_State : 144|19@1+ (1.0,0) [0|524287] "" Vector__XXX
 SG_ AIS_Transceiver_information : 163|5@1+ (1.0,0) [0|31] "" Vector__XXX
 SG_ Position_Date : 168|16@1+ (1.0,0) [0|65535] "" Vector__XXX
 SG_ GNSS_type : 188|4@1+ (1.0,0) [0|15] "" Vector__XXX
 SG_ Spare : 192|10@1+ (1.0,0) [0|1023] "" Vector__XXX
 SG_ Sequence_ID : 208|8@1+ (1.0,0) [0|255] "" Vector__XXX

BO_ 2583364096 PGN_129794_aisClassAStaticAndVoyageRelatedData: 76 Vector__XXX
 SG_ Message_ID : 0|6@1+ (1.0,0) [0|63] "" Vector__XXX
 SG_ Repeat_Indicator : 6|2@1+ (1.0,0) [0|3] "" Vector__XXX
 SG_ User_ID : 8|32@1+ (1.0,0) [2000000.0|999999999.0] "" Vector__XXX
 SG_ IMO_number : 40|32@1+ (1.0,0) [0|4294967295] "" Vector__XXX
 SG_ Callsign : 72|56@1+ (1.0,0) [0|72057594037927935] "" Vector__XXX
 SG_ Name : 128|160@1+ (1.0,0) [0|1461501637330902918203684832716283019655932542975] "" Vector__XXX
 SG_ Type_of_ship : 288|8@1+ (1.0,0) [0|255] "" Vector__XXX
 SG_ Length : 296|16@1+ (0.1,0) [0.0|6553.5] "" Vector__XXX
 SG_ Beam : 312|16@1+ (0.1,0) [0.0|6553.5] "" Vector__XXX
 SG_ Position_reference_from_Starboard : 328|16@1+ (0.1,0) [0.0|6553.5] "" Vector__XXX
 SG_ Position_reference_from_Bow : 344|16@1+ (0.1,0) [0.0|6553.5] "" Vector__XXX
 SG_ ETA_Date : 360|16@1+ (1.0,0) [0|65535] "" Vector__XXX
 SG_ ETA_Time : 376|32@1+ (0.0001,0) [0.0|86401.0] "" Vector__XXX
 SG_ Draft : 408|16@1+ (0.01,0) [0.0|655.35] "" Vector__XXX
 SG_ Destination : 424|160@1+ (1.0,0) [0|1461501637330902918203684832716283019655932542975] "" Vector__XXX
 SG_ AIS_version_indicator : 584|2@1+ (1.0,0) [0|3] "" Vector__XXX
 SG_ GNSS_type : 586|4@1+ (1.0,0) [0|15] "" Vector__XXX
 SG_ DTE : 590|1@1+ (1.0,0) [0|1] "" Vector__XXX
 SG_ AIS_Transceiver_information : 592|5@1+ (1.0,0) [0|31] "" Vector__XXX
 SG_ Sequence_ID : 600|8@1+ (1.0,0) [0|255] "" Vector__XXX

BO_ 2516255488 PGN_129795_aisAddressedBinaryMessage: 14 Vector__XXX
 SG_ Message_ID : 0|6@1+ (1.0,0) [0|63] "" Vector__XXX
 SG_ Repeat_Indicator : 6|2@1+ (1.0,0) [0|3] "" Vector__XXX
 SG_ Source_ID : 8|32@1+ (1.0,0) [2000000.0|999999999.0] "" Vector__XXX
 SG_ AIS_Transceiver_information : 41|5@1+ (1.0,0) [0|31] "" Vector__XXX
 SG_ Sequence_Number : 46|2@1+ (1.0,0) [0|3] "" Vector__XXX
 SG_ Destination_ID : 48|32@1+ (1.0,0) [2000000.0|999999999.0] "" Vector__XXX
 SG_ Retransmit_flag : 86|1@1+ (1.0,0) [0|1] "" Vector__XXX
 SG_ Number_of_Bits_in_Binary_Data_Field : 88|16@1+ (1.0,0) [0|65535] "" Vector__XXX
 SG_ Binary_Data : 104|8@1+ (1.0,0) [0|255] "" Vector__XXX

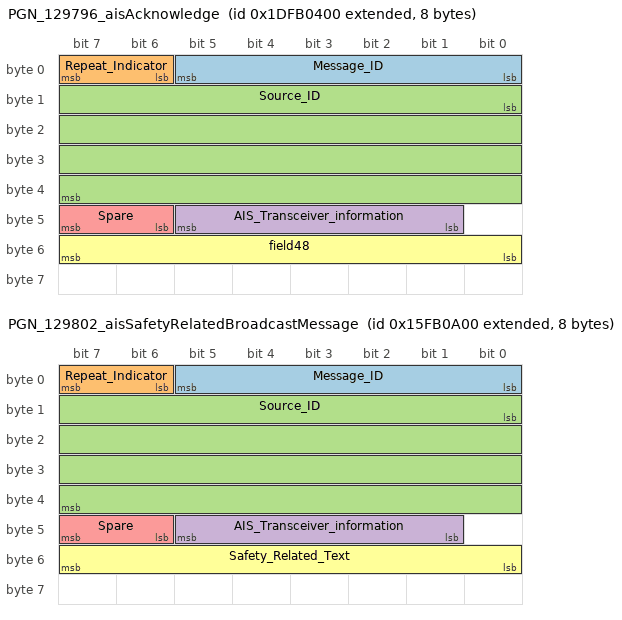
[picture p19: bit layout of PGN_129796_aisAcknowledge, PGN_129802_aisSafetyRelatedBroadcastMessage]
BO_ 2650473472 PGN_129796_aisAcknowledge: 8 Vector__XXX
 SG_ Message_ID : 0|6@1+ (1.0,0) [0|63] "" Vector__XXX
 SG_ Repeat_Indicator : 6|2@1+ (1.0,0) [0|3] "" Vector__XXX
 SG_ Source_ID : 8|32@1+ (1.0,0) [2000000.0|999999999.0] "" Vector__XXX
 SG_ AIS_Transceiver_information : 41|5@1+ (1.0,0) [0|31] "" Vector__XXX
 SG_ Spare : 46|2@1+ (1.0,0) [0|3] "" Vector__XXX
 SG_ field48 : 48|8@1+ (1.0,0) [0|255] "" Vector__XXX

BO_ 2516256000 PGN_129797_aisBinaryBroadcastMessage: 9 Vector__XXX
 SG_ Message_ID : 0|6@1+ (1.0,0) [0|63] "" Vector__XXX
 SG_ Repeat_Indicator : 6|2@1+ (1.0,0) [0|3] "" Vector__XXX
 SG_ Source_ID : 8|32@1+ (1.0,0) [2000000.0|999999999.0] "" Vector__XXX
 SG_ AIS_Transceiver_information : 41|5@1+ (1.0,0) [0|31] "" Vector__XXX
 SG_ Spare : 46|2@1+ (1.0,0) [0|3] "" Vector__XXX
 SG_ Number_of_Bits_in_Binary_Data_Field : 48|16@1+ (1.0,0) [0|65535] "" Vector__XXX
 SG_ Binary_Data : 64|8@1+ (1.0,0) [0|255] "" Vector__XXX

BO_ 2449147392 PGN_129798_aisSarAircraftPositionReport: 27 Vector__XXX
 SG_ Message_ID : 0|6@1+ (1.0,0) [0|63] "" Vector__XXX
 SG_ Repeat_Indicator : 6|2@1+ (1.0,0) [0|3] "" Vector__XXX
 SG_ User_ID : 8|32@1+ (1.0,0) [2000000.0|999999999.0] "" Vector__XXX
 SG_ Longitude : 40|32@1- (1e-07,0) [-180.0|180.0] "" Vector__XXX
 SG_ Latitude : 72|32@1- (1e-07,0) [-90.0|90.0] "" Vector__XXX
 SG_ Position_Accuracy : 104|1@1+ (1.0,0) [0|1] "" Vector__XXX
 SG_ RAIM : 105|1@1+ (1.0,0) [0|1] "" Vector__XXX
 SG_ Time_Stamp : 106|6@1+ (1.0,0) [0|63] "" Vector__XXX
 SG_ COG : 112|16@1+ (0.0001,0) [0.0|6.5535000000000005] "" Vector__XXX
 SG_ SOG : 128|16@1+ (0.1,0) [0.0|6553.5] "" Vector__XXX
 SG_ Communication_State : 144|19@1+ (1.0,0) [0|524287] "" Vector__XXX
 SG_ AIS_Transceiver_information : 163|5@1+ (1.0,0) [0|31] "" Vector__XXX
 SG_ Altitude : 168|32@1- (0.01,0) [-21474836.48|21474836.47] "" Vector__XXX
 SG_ Reserved_for_Regional_Applications : 200|8@1+ (1.0,0) [0|255] "" Vector__XXX
 SG_ DTE : 208|1@1+ (1.0,0) [0|1] "" Vector__XXX
 SG_ Spare : 209|5@1+ (1.0,0) [0|31] "" Vector__XXX

BO_ 2382038784 PGN_129799_radioFrequencyModePower: 19 Vector__XXX
 SG_ Rx_Frequency : 0|32@1+ (10.0,0) [0.0|42949672950.0] "" Vector__XXX
 SG_ Tx_Frequency : 32|32@1+ (10.0,0) [0.0|42949672950.0] "" Vector__XXX
 SG_ Radio_Channel : 64|48@1+ (1.0,0) [0|281474976710655] "" Vector__XXX
 SG_ Tx_Power : 112|16@1+ (1.0,0) [0|65535] "" Vector__XXX
 SG_ Mode : 128|8@1+ (1.0,0) [0|255] "" Vector__XXX
 SG_ Channel_Bandwidth : 136|16@1+ (1.0,0) [0|65535] "" Vector__XXX

BO_ 2650474496 PGN_129800_aisUtcDateInquiry: 10 Vector__XXX
 SG_ Message_ID : 0|6@1+ (1.0,0) [0|63] "" Vector__XXX
 SG_ Repeat_Indicator : 6|2@1+ (1.0,0) [0|3] "" Vector__XXX
 SG_ Source_ID : 8|32@1+ (1.0,0) [2000000.0|999999999.0] "" Vector__XXX
 SG_ AIS_Transceiver_information : 41|5@1+ (1.0,0) [0|31] "" Vector__XXX
 SG_ Spare : 46|2@1+ (1.0,0) [0|3] "" Vector__XXX
 SG_ Destination_ID : 48|32@1+ (1.0,0) [2000000.0|999999999.0] "" Vector__XXX

BO_ 2516257024 PGN_129801_aisAddressedSafetyRelatedMessage: 12 Vector__XXX
 SG_ Message_ID : 0|6@1+ (1.0,0) [0|63] "" Vector__XXX
 SG_ Repeat_Indicator : 6|2@1+ (1.0,0) [0|3] "" Vector__XXX
 SG_ Source_ID : 8|32@1+ (1.0,0) [2000000.0|999999999.0] "" Vector__XXX
 SG_ AIS_Transceiver_information : 41|5@1+ (1.0,0) [0|31] "" Vector__XXX
 SG_ Sequence_Number : 46|2@1+ (1.0,0) [0|3] "" Vector__XXX
 SG_ Destination_ID : 48|32@1+ (1.0,0) [2000000.0|999999999.0] "" Vector__XXX
 SG_ Retransmit_flag : 86|1@1+ (1.0,0) [0|1] "" Vector__XXX
 SG_ Spare : 87|1@1+ (1.0,0) [0|1] "" Vector__XXX
 SG_ Safety_Related_Text : 88|8@1+ (1.0,0) [0|255] "" Vector__XXX

BO_ 2516257280 PGN_129802_aisSafetyRelatedBroadcastMessage: 8 Vector__XXX
 SG_ Message_ID : 0|6@1+ (1.0,0) [0|63] "" Vector__XXX
 SG_ Repeat_Indicator : 6|2@1+ (1.0,0) [0|3] "" Vector__XXX
 SG_ Source_ID : 8|32@1+ (1.0,0) [2000000.0|999999999.0] "" Vector__XXX
 SG_ AIS_Transceiver_information : 41|5@1+ (1.0,0) [0|31] "" Vector__XXX
 SG_ Spare : 46|2@1+ (1.0,0) [0|3] "" Vector__XXX
 SG_ Safety_Related_Text : 48|8@1+ (1.0,0) [0|255] "" Vector__XXX

BO_ 2650475264 PGN_129803_aisInterrogation: 26 Vector__XXX
 SG_ Message_ID : 0|6@1+ (1.0,0) [0|63] "" Vector__XXX
 SG_ Repeat_Indicator : 6|2@1+ (1.0,0) [0|3] "" Vector__XXX
 SG_ Source_ID : 8|32@1+ (1.0,0) [2000000.0|999999999.0] "" Vector__XXX
 SG_ AIS_Transceiver_information : 41|5@1+ (1.0,0) [0|31] "" Vector__XXX
 SG_ Spare : 46|2@1+ (1.0,0) [0|3] "" Vector__XXX
 SG_ Destination_ID_1 : 48|32@1+ (1.0,0) [2000000.0|999999999.0] "" Vector__XXX
 SG_ Message_ID_1_1 : 82|6@1+ (1.0,0) [0|63] "" Vector__XXX
 SG_ Slot_Offset_1_1 : 88|16@1+ (1.0,0) [0|65535] "" Vector__XXX
 SG_ Spare_1 : 104|2@1+ (1.0,0) [0|3] "" Vector__XXX
 SG_ Message_ID_1_2 : 106|6@1+ (1.0,0) [0|63] "" Vector__XXX
 SG_ Slot_Offset_1_2 : 112|16@1+ (1.0,0) [0|65535] "" Vector__XXX
 SG_ Destination_ID_2 : 136|32@1+ (1.0,0) [2000000.0|999999999.0] "" Vector__XXX
 SG_ Message_ID_2_1 : 170|6@1+ (1.0,0) [0|63] "" Vector__XXX
 SG_ Slot_Offset_2_1 : 176|16@1+ (1.0,0) [0|65535] "" Vector__XXX
 SG_ Spare_2 : 192|2@1+ (1.0,0) [0|3] "" Vector__XXX
 SG_ SID : 200|8@1+ (1.0,0) [0|255] "" Vector__XXX

BO_ 2650475520 PGN_129804_aisAssignmentModeCommand: 23 Vector__XXX
 SG_ Message_ID : 0|6@1+ (1.0,0) [0|63] "" Vector__XXX
 SG_ Repeat_Indicator : 6|2@1+ (1.0,0) [0|3] "" Vector__XXX
 SG_ Source_ID : 8|32@1+ (1.0,0) [2000000.0|999999999.0] "" Vector__XXX
 SG_ AIS_Transceiver_information : 41|5@1+ (1.0,0) [0|31] "" Vector__XXX
 SG_ Spare : 46|2@1+ (1.0,0) [0|3] "" Vector__XXX
 SG_ Destination_ID_A : 48|32@1+ (1.0,0) [2000000.0|999999999.0] "" Vector__XXX
 SG_ Offset_A : 80|16@1+ (1.0,0) [0|65535] "" Vector__XXX
 SG_ Increment_A : 96|16@1+ (1.0,0) [0|65535] "" Vector__XXX
 SG_ Destination_ID_B : 112|32@1+ (1.0,0) [2000000.0|999999999.0] "" Vector__XXX
 SG_ Offset_B : 144|16@1+ (1.0,0) [0|65535] "" Vector__XXX
 SG_ Increment_B : 160|16@1+ (1.0,0) [0|65535] "" Vector__XXX
 SG_ Spare_1 : 176|4@1+ (1.0,0) [0|15] "" Vector__XXX

CM_ BO_ 2582645504 "NMEA2000: PGN 126987 - Alert Threshold (type: Fast)";
CM_ BO_ 2582645760 "NMEA2000: PGN 126988 - Alert Value (type: Fast)";
CM_ BO_ 2381320192 "NMEA2000: PGN 126992 - System Time (type: Single)";
CM_ BO_ 2649755904 "NMEA2000: PGN 126993 - Heartbeat (type: Single)";
CM_ BO_ 2582647808 "NMEA2000: PGN 126996 - Product Information (type: Fast)";
CM_ BO_ 2582648320 "NMEA2000: PGN 126998 - Configuration Information (type: Fast)";
CM_ BO_ 2582708480 "NMEA2000: PGN 127233 - Man Overboard Notification (type: Fast)";
CM_ BO_ 2314274048 "NMEA2000: PGN 127237 - Heading/Track control (type: Fast)";
CM_ BO_ 2314276096 "NMEA2000: PGN 127245 - Rudder (type: Single)";
CM_ BO_ 2314277376 "NMEA2000: PGN 127250 - Vessel Heading (type: Single)";
CM_ BO_ 2314277632 "NMEA2000: PGN 127251 - Rate of Turn (type: Single)";
CM_ BO_ 2381386752 "NMEA2000: PGN 127252 - Heave (type: Single)";
CM_ BO_ 2381388032 "NMEA2000: PGN 127257 - Attitude (type: Single)";
CM_ BO_ 2649823744 "NMEA2000: PGN 127258 - Magnetic Variation (type: Single)";
CM_ BO_ 2314338304 "NMEA2000: PGN 127488 - Engine Parameters, Rapid Update (type: Single)";
CM_ BO_ 2314338560 "NMEA2000: PGN 127489 - Engine Parameters, Dynamic (type: Fast)";
CM_ BO_ 2582774272 "NMEA2000: PGN 127490 - Electric Drive Status, Dynamic (type: Fast)";
CM_ BO_ 2582774528 "NMEA2000: PGN 127491 - Electric Energy Storage Status, Dynamic (type: Fast)";
CM_ BO_ 2314339584 "NMEA2000: PGN 127493 - Transmission Parameters, Dynamic (type: Single)";
CM_ BO_ 2582775296 "NMEA2000: PGN 127494 - Electric Drive Information (type: Fast)";
CM_ BO_ 2582775552 "NMEA2000: PGN 127495 - Electric Energy Storage Information (type: Fast)";
CM_ BO_ 2515666944 "NMEA2000: PGN 127496 - Trip Parameters, Vessel (type: Fast)";
CM_ BO_ 2515667200 "NMEA2000: PGN 127497 - Trip Parameters, Engine (type: Fast)";
CM_ BO_ 2515667456 "NMEA2000: PGN 127498 - Engine Parameters, Static (type: Fast)";
CM_ BO_ 2582776832 "NMEA2000: PGN 127500 - Load Controller Connection State/Control (type: Single)";
CM_ BO_ 2381450496 "NMEA2000: PGN 127501 - Binary Switch Bank Status (type: Single)";
CM_ BO_ 2381450752 "NMEA2000: PGN 127502 - Switch Bank Control (type: Single)";
CM_ BO_ 2582777600 "NMEA2000: PGN 127503 - AC Input Status (type: Fast)";
CM_ BO_ 2582777856 "NMEA2000: PGN 127504 - AC Output Status (type: Fast)";
CM_ BO_ 2582778112 "NMEA2000: PGN 127505 - Fluid Level (type: Single)";
CM_ BO_ 2582778368 "NMEA2000: PGN 127506 - DC Detailed Status (type: Fast)";
CM_ BO_ 2582778624 "NMEA2000: PGN 127507 - Charger Status (type: Fast)";
CM_ BO_ 2582778880 "NMEA2000: PGN 127508 - Battery Status (type: Single)";
CM_ BO_ 2582779136 "NMEA2000: PGN 127509 - Inverter Status (type: Fast)";
CM_ BO_ 2582779392 "NMEA2000: PGN 127510 - Charger Configuration Status (type: Fast)";
CM_ BO_ 2582779648 "NMEA2000: PGN 127511 - Inverter Configuration Status (type: Fast)";
CM_ BO_ 2582779904 "NMEA2000: PGN 127512 - AGS Configuration Status (type: Fast)";
CM_ BO_ 2582780160 "NMEA2000: PGN 127513 - Battery Configuration Status (type: Fast)";
CM_ BO_ 2582780416 "NMEA2000: PGN 127514 - AGS Status (type: Fast)";
CM_ BO_ 2582839296 "NMEA2000: PGN 127744 - AC Power / Current - Phase A (type: Single)";
CM_ BO_ 2582839552 "NMEA2000: PGN 127745 - AC Power / Current - Phase B (type: Single)";
CM_ BO_ 2582839808 "NMEA2000: PGN 127746 - AC Power / Current - Phase C (type: Single)";
CM_ BO_ 2582840064 "NMEA2000: PGN 127747 - AC Voltage / Frequency - Phase A (type: Single)";
CM_ BO_ 2582840320 "NMEA2000: PGN 127748 - AC Voltage / Frequency - Phase B (type: Single)";
CM_ BO_ 2582840576 "NMEA2000: PGN 127749 - AC Voltage / Frequency - Phase C (type: Single)";
CM_ BO_ 2582840832 "NMEA2000: PGN 127750 - Converter Status (type: Single)";
CM_ BO_ 2582841088 "NMEA2000: PGN 127751 - DC Voltage/Current (type: Single)";
CM_ BO_ 2582904832 "NMEA2000: PGN 128000 - Leeway Angle (type: Single)";
CM_ BO_ 2582905088 "NMEA2000: PGN 128001 - Vessel Acceleration (type: Single)";
CM_ BO_ 2582905344 "NMEA2000: PGN 128002 - Electric Drive Status, Rapid Update (type: Single)";
CM_ BO_ 2582905600 "NMEA2000: PGN 128003 - Electric Energy Storage Status, Rapid Update (type: Single)";
CM_ BO_ 2582906368 "NMEA2000: PGN 128006 - Thruster Control Status (type: Single)";
CM_ BO_ 2582906624 "NMEA2000: PGN 128007 - Thruster Information (type: Single)";
CM_ BO_ 2582906880 "NMEA2000: PGN 128008 - Thruster Motor Status (type: Single)";
CM_ BO_ 2314535680 "NMEA2000: PGN 128259 - Speed (type: Single)";
CM_ BO_ 2381646592 "NMEA2000: PGN 128267 - Water Depth (type: Single)";
CM_ BO_ 2582975232 "NMEA2000: PGN 128275 - Distance Log (type: Fast)";
CM_ BO_ 2314602496 "NMEA2000: PGN 128520 - Tracked Target Data (type: Fast)";
CM_ BO_ 2583042560 "NMEA2000: PGN 128538 - Elevator Car Status (type: Fast)";
CM_ BO_ 2583101440 "NMEA2000: PGN 128768 - Elevator Motor Control (type: Single)";
CM_ BO_ 2583101696 "NMEA2000: PGN 128769 - Elevator Deck Push Button (type: Single)";
CM_ BO_ 2583103488 "NMEA2000: PGN 128776 - Windlass Control Status (type: Single)";
CM_ BO_ 2583103744 "NMEA2000: PGN 128777 - Anchor Windlass Operating Status (type: Single)";
CM_ BO_ 2583104000 "NMEA2000: PGN 128778 - Anchor Windlass Monitoring Status (type: Single)";
CM_ BO_ 2583104512 "NMEA2000: PGN 128780 - Linear Actuator Control/Status (type: Single)";
CM_ BO_ 2314731776 "NMEA2000: PGN 129025 - Position, Rapid Update (type: Single)";
CM_ BO_ 2314732032 "NMEA2000: PGN 129026 - COG & SOG, Rapid Update (type: Single)";
CM_ BO_ 2314732288 "NMEA2000: PGN 129027 - Position Delta, Rapid Update (type: Single)";
CM_ BO_ 2314732544 "NMEA2000: PGN 129028 - Altitude Delta, Rapid Update (type: Single)";
CM_ BO_ 2381841664 "NMEA2000: PGN 129029 - GNSS Position Data (type: Fast)";
CM_ BO_ 2381842688 "NMEA2000: PGN 129033 - Time & Date (type: Single)";
CM_ BO_ 2448952832 "NMEA2000: PGN 129038 - AIS Class A Position Report (type: Fast)";
CM_ BO_ 2448953088 "NMEA2000: PGN 129039 - AIS Class B Position Report (type: Fast)";
CM_ BO_ 2448953344 "NMEA2000: PGN 129040 - AIS Class B Extended Position Report (type: Fast)";
CM_ BO_ 2448953600 "NMEA2000: PGN 129041 - AIS Aids to Navigation (AtoN) Report (type: Fast)";
CM_ BO_ 2583172096 "NMEA2000: PGN 129044 - Datum (type: Fast)";
CM_ BO_ 2583172352 "NMEA2000: PGN 129045 - User Datum (type: Fast)";
CM_ BO_ 2381906688 "NMEA2000: PGN 129283 - Cross Track Error (type: Single)";
CM_ BO_ 2381906944 "NMEA2000: PGN 129284 - Navigation Data (type: Fast)";
CM_ BO_ 2583233792 "NMEA2000: PGN 129285 - Navigation - Route/WP Information (type: Fast)";
CM_ BO_ 2381908736 "NMEA2000: PGN 129291 - Set & Drift, Rapid Update (type: Single)";
CM_ BO_ 2381911296 "NMEA2000: PGN 129301 - Navigation - Route / Time to+from Mark (type: Fast)";
CM_ BO_ 2583238144 "NMEA2000: PGN 129302 - Bearing and Distance between two Marks (type: Fast)";
CM_ BO_ 2583298560 "NMEA2000: PGN 129538 - GNSS Control Status (type: Fast)";
CM_ BO_ 2583298816 "NMEA2000: PGN 129539 - GNSS DOPs (type: Single)";
CM_ BO_ 2583299072 "NMEA2000: PGN 129540 - GNSS Sats in View (type: Fast)";
CM_ BO_ 2583299328 "NMEA2000: PGN 129541 - GPS Almanac Data (type: Fast)";
CM_ BO_ 2583299584 "NMEA2000: PGN 129542 - GNSS Pseudorange Noise Statistics (type: Fast)";
CM_ BO_ 2583300352 "NMEA2000: PGN 129545 - GNSS RAIM Output (type: Fast)";
CM_ BO_ 2583300608 "NMEA2000: PGN 129546 - GNSS RAIM Settings (type: Single)";
CM_ BO_ 2583300864 "NMEA2000: PGN 129547 - GNSS Pseudorange Error Statistics (type: Fast)";
CM_ BO_ 2583301376 "NMEA2000: PGN 129549 - DGNSS Corrections (type: Fast)";
CM_ BO_ 2583301632 "NMEA2000: PGN 129550 - GNSS Differential Correction Receiver Interface (type: Single)";
CM_ BO_ 2583301888 "NMEA2000: PGN 129551 - GNSS Differential Correction Receiver Signal (type: Fast)";
CM_ BO_ 2583303168 "NMEA2000: PGN 129556 - GLONASS Almanac Data (type: Fast)";
CM_ BO_ 2583363584 "NMEA2000: PGN 129792 - AIS DGNSS Broadcast Binary Message (type: Fast)";
CM_ BO_ 2650472704 "NMEA2000: PGN 129793 - AIS UTC and Date Report (type: Fast)";
CM_ BO_ 2583364096 "NMEA2000: PGN 129794 - AIS Class A Static and Voyage Related Data (type: Fast)";
CM_ BO_ 2516255488 "NMEA2000: PGN 129795 - AIS Addressed Binary Message (type: Fast)";
CM_ BO_ 2650473472 "NMEA2000: PGN 129796 - AIS Acknowledge (type: Fast)";
CM_ BO_ 2516256000 "NMEA2000: PGN 129797 - AIS Binary Broadcast Message (type: Fast)";
CM_ BO_ 2449147392 "NMEA2000: PGN 129798 - AIS SAR Aircraft Position Report (type: Fast)";
CM_ BO_ 2382038784 "NMEA2000: PGN 129799 - Radio Frequency/Mode/Power (type: Fast)";
CM_ BO_ 2650474496 "NMEA2000: PGN 129800 - AIS UTC/Date Inquiry (type: Fast)";
CM_ BO_ 2516257024 "NMEA2000: PGN 129801 - AIS Addressed Safety Related Message (type: Fast)";
CM_ BO_ 2516257280 "NMEA2000: PGN 129802 - AIS Safety Related Broadcast Message (type: Fast)";
CM_ BO_ 2650475264 "NMEA2000: PGN 129803 - AIS Interrogation (type: Fast)";
CM_ BO_ 2650475520 "NMEA2000: PGN 129804 - AIS Assignment Mode Command (type: Fast)";
CM_ SG_ 2582645504 Alert_Type "canboat type: LOOKUP";
CM_ SG_ 2582645504 Alert_Category "canboat type: LOOKUP";
CM_ SG_ 2582645504 Alert_System "canboat type: UINT8";
CM_ SG_ 2582645504 Alert_Sub_System "canboat type: UINT8";
CM_ SG_ 2582645504 Alert_ID "canboat type: UINT16";
CM_ SG_ 2582645504 Data_Source_Network_ID_NAME "canboat type: ISO_NAME";
CM_ SG_ 2582645504 Data_Source_Instance "canboat type: UINT8";
CM_ SG_ 2582645504 Data_Source_Index_Source "canboat type: UINT8";
CM_ SG_ 2582645504 Alert_Occurrence_Number "canboat type: UINT8";
CM_ SG_ 2582645504 Number_of_Parameters "Total Number of Threshold Parameters; canboat type: UINT8";
CM_ SG_ 2582645504 field136 "canboat type: NUMBER";
CM_ SG_ 2582645760 Alert_Type "canboat type: LOOKUP";
CM_ SG_ 2582645760 Alert_Category "canboat type: LOOKUP";
CM_ SG_ 2582645760 Alert_System "canboat type: UINT8";
CM_ SG_ 2582645760 Alert_Sub_System "canboat type: UINT8";
CM_ SG_ 2582645760 Alert_ID "canboat type: UINT16";
CM_ SG_ 2582645760 Data_Source_Network_ID_NAME "canboat type: ISO_NAME";
CM_ SG_ 2582645760 Data_Source_Instance "canboat type: UINT8";
CM_ SG_ 2582645760 Data_Source_Index_Source "canboat type: UINT8";
CM_ SG_ 2582645760 Alert_Occurrence_Number "canboat type: UINT8";
CM_ SG_ 2582645760 Number_of_Parameters "Total Number of Value Parameters; canboat type: UINT8";
CM_ SG_ 2582645760 field136 "canboat type: NUMBER";
CM_ SG_ 2381320192 SID "An upward counting number used to tie related information together between different PGNs. For example the SID would be used to tie together the COG, SOG and RAIM values to a given position.; canboat type: UINT8";
CM_ SG_ 2381320192 Source "canboat type: LOOKUP";
CM_ SG_ 2381320192 Date "canboat type: DATE";
CM_ SG_ 2381320192 Time "Seconds since midnight; canboat type: TIME";
CM_ SG_ 2649755904 Data_transmit_offset "Offset in transmit time from time of request command: 0x0 = transmit immediately, 0xFFFF = Do not change offset.; canboat type: DURATION_UFIX16_MS";
CM_ SG_ 2649755904 Sequence_Counter "canboat type: UINT8";
CM_ SG_ 2649755904 Controller_1_State "canboat type: LOOKUP";
CM_ SG_ 2649755904 Controller_2_State "canboat type: LOOKUP";
CM_ SG_ 2649755904 Equipment_Status "canboat type: LOOKUP";
CM_ SG_ 2582647808 NMEA_2000_Version "Binary number containing a decimal number of format AABBB, where AA is the major and BBB is the minor release. The decimal point position is assumed.; canboat type: VERSION";
CM_ SG_ 2582647808 Product_Code "canboat type: UINT16";
CM_ SG_ 2582647808 Model_ID "canboat type: STRING_FIX";
CM_ SG_ 2582647808 Software_Version_Code "canboat type: STRING_FIX";
CM_ SG_ 2582647808 Model_Version "canboat type: STRING_FIX";
CM_ SG_ 2582647808 Model_Serial_Code "canboat type: STRING_FIX";
CM_ SG_ 2582647808 Certification_Level "canboat type: LOOKUP";
CM_ SG_ 2582647808 Load_Equivalency "Garantueed maximum power consumption, 50 mA per LEN; canboat type: UINT8";
CM_ SG_ 2582648320 Installation_Description__1 "canboat type: STRING_LAU";
CM_ SG_ 2582648320 Installation_Description__2 "canboat type: STRING_LAU";
CM_ SG_ 2582648320 Manufacturer_Information "canboat type: STRING_LAU";
CM_ SG_ 2582708480 SID "canboat type: UINT8";
CM_ SG_ 2582708480 MOB_Emitter_ID "Identifier for each MOB emitter, unique to the vessel; canboat type: UINT32";
CM_ SG_ 2582708480 Man_Overboard_Status "canboat type: LOOKUP";
CM_ SG_ 2582708480 Activation_Time "Seconds since midnight; canboat type: TIME";
CM_ SG_ 2582708480 Position_Source "canboat type: LOOKUP";
CM_ SG_ 2582708480 Position_Date "canboat type: DATE";
CM_ SG_ 2582708480 Position_Time "Seconds since midnight; canboat type: TIME";
CM_ SG_ 2582708480 Latitude "canboat type: GEO_LAT_FIX32";
CM_ SG_ 2582708480 Longitude "canboat type: GEO_LON_FIX32";
CM_ SG_ 2582708480 COG_Reference "canboat type: LOOKUP";
CM_ SG_ 2582708480 COG "canboat type: ANGLE_UFIX16";
CM_ SG_ 2582708480 SOG "canboat type: SPEED_UFIX16_CM";
CM_ SG_ 2582708480 MMSI_of_vessel_of_origin "canboat type: MMSI";
CM_ SG_ 2582708480 MOB_Emitter_Battery_Low_Status "canboat type: LOOKUP";
CM_ SG_ 2314274048 Rudder_Limit_Exceeded "canboat type: LOOKUP";
CM_ SG_ 2314274048 Off_Heading_Limit_Exceeded "canboat type: LOOKUP";
CM_ SG_ 2314274048 Off_Track_Limit_Exceeded "canboat type: LOOKUP";
CM_ SG_ 2314274048 Override "canboat type: LOOKUP";
CM_ SG_ 2314274048 Steering_Mode "canboat type: LOOKUP";
CM_ SG_ 2314274048 Turn_Mode "canboat type: LOOKUP";
CM_ SG_ 2314274048 Heading_Reference "canboat type: LOOKUP";
CM_ SG_ 2314274048 Commanded_Rudder_Direction "canboat type: LOOKUP";
CM_ SG_ 2314274048 Commanded_Rudder_Angle "canboat type: ANGLE_FIX16";
CM_ SG_ 2314274048 Heading_To_Steer__Course_ "canboat type: ANGLE_UFIX16";
CM_ SG_ 2314274048 Track "canboat type: ANGLE_UFIX16";
CM_ SG_ 2314274048 Rudder_Limit "canboat type: ANGLE_UFIX16";
CM_ SG_ 2314274048 Off_Heading_Limit "canboat type: ANGLE_UFIX16";
CM_ SG_ 2314274048 Radius_of_Turn_Order "canboat type: DISTANCE_FIX16_M";
CM_ SG_ 2314274048 Rate_of_Turn_Order "canboat type: ROTATION_FIX16";
CM_ SG_ 2314274048 Off_Track_Limit "canboat type: DISTANCE_FIX16_M";
CM_ SG_ 2314274048 Vessel_Heading "canboat type: ANGLE_UFIX16";
CM_ SG_ 2314276096 Instance "canboat type: UINT8";
CM_ SG_ 2314276096 Direction_Order "canboat type: LOOKUP";
CM_ SG_ 2314276096 Angle_Order "canboat type: ANGLE_FIX16";
CM_ SG_ 2314276096 Position "canboat type: ANGLE_FIX16";
CM_ SG_ 2314277376 SID "canboat type: UINT8";
CM_ SG_ 2314277376 Heading "canboat type: ANGLE_UFIX16";
CM_ SG_ 2314277376 Deviation "canboat type: ANGLE_FIX16";
CM_ SG_ 2314277376 Variation "canboat type: ANGLE_FIX16";
CM_ SG_ 2314277376 Reference "canboat type: LOOKUP";
CM_ SG_ 2314277632 SID "canboat type: UINT8";
CM_ SG_ 2314277632 Rate "canboat type: ROTATION_FIX32";
CM_ SG_ 2381386752 SID "canboat type: UINT8";
CM_ SG_ 2381386752 Heave "canboat type: DISTANCE_FIX16_CM";
CM_ SG_ 2381388032 SID "canboat type: UINT8";
CM_ SG_ 2381388032 Yaw "canboat type: ANGLE_FIX16";
CM_ SG_ 2381388032 Pitch "canboat type: ANGLE_FIX16";
CM_ SG_ 2381388032 Roll "canboat type: ANGLE_FIX16";
CM_ SG_ 2649823744 SID "canboat type: UINT8";
CM_ SG_ 2649823744 Source "canboat type: LOOKUP";
CM_ SG_ 2649823744 Age_of_service "canboat type: DATE";
CM_ SG_ 2649823744 Variation "canboat type: ANGLE_FIX16";
CM_ SG_ 2314338304 Instance "canboat type: LOOKUP";
CM_ SG_ 2314338304 Speed "canboat type: ROTATION_UFIX16_RPM";
CM_ SG_ 2314338304 Boost_Pressure "canboat type: PRESSURE_UFIX16_HPA";
CM_ SG_ 2314338304 Tilt_Trim "canboat type: PERCENTAGE_INT8";
CM_ SG_ 2314338560 Instance "canboat type: LOOKUP";
CM_ SG_ 2314338560 Oil_pressure "canboat type: PRESSURE_UFIX16_HPA";
CM_ SG_ 2314338560 Oil_temperature "canboat type: TEMPERATURE_HIGH";
CM_ SG_ 2314338560 Temperature "canboat type: TEMPERATURE";
CM_ SG_ 2314338560 Alternator_Potential "canboat type: VOLTAGE_FIX16_10MV";
CM_ SG_ 2314338560 Fuel_Rate "canboat type: VOLUMETRIC_FLOW";
CM_ SG_ 2314338560 Total_Engine_hours "canboat type: DURATION_UFIX32_S";
CM_ SG_ 2314338560 Coolant_Pressure "canboat type: PRESSURE_UFIX16_HPA";
CM_ SG_ 2314338560 Fuel_Pressure "canboat type: PRESSURE_UFIX16_KPA";
CM_ SG_ 2314338560 Discrete_Status_1 "canboat type: BITLOOKUP";
CM_ SG_ 2314338560 Discrete_Status_2 "canboat type: BITLOOKUP";
CM_ SG_ 2314338560 Engine_Load "canboat type: PERCENTAGE_INT8";
CM_ SG_ 2314338560 Engine_Torque "canboat type: PERCENTAGE_INT8";
CM_ SG_ 2582774272 Inverter_Motor_Identifier "canboat type: UINT8";
CM_ SG_ 2582774272 Operating_Mode "canboat type: UNSIGNED_INTEGER";
CM_ SG_ 2582774272 Motor_Temperature "canboat type: TEMPERATURE";
CM_ SG_ 2582774272 Inverter_Temperature "canboat type: TEMPERATURE";
CM_ SG_ 2582774272 Coolant_Temperature "canboat type: TEMPERATURE";
CM_ SG_ 2582774272 Gear_Temperature "canboat type: TEMPERATURE";
CM_ SG_ 2582774272 Shaft_Torque "canboat type: UINT16";
CM_ SG_ 2582774528 Energy_Storage_Identifier "canboat type: UINT8";
CM_ SG_ 2582774528 State_of_Charge "canboat type: PERCENTAGE_UINT8";
CM_ SG_ 2582774528 Time_Remaining "Time remaining at current rate of discharge; canboat type: DURATION_UFIX16_MIN";
CM_ SG_ 2582774528 Highest_Cell_Temperature "canboat type: TEMPERATURE";
CM_ SG_ 2582774528 Lowest_Cell_Temperature "canboat type: TEMPERATURE";
CM_ SG_ 2582774528 Average_Cell_Temperature "canboat type: TEMPERATURE";
CM_ SG_ 2582774528 Max_Discharge_Current "canboat type: CURRENT_FIX16_DA";
CM_ SG_ 2582774528 Max_Charge_Current "canboat type: CURRENT_FIX16_DA";
CM_ SG_ 2582774528 Cooling_System_Status "canboat type: UNSIGNED_INTEGER";
CM_ SG_ 2582774528 Heating_System_Status "canboat type: UNSIGNED_INTEGER";
CM_ SG_ 2314339584 Instance "canboat type: LOOKUP";
CM_ SG_ 2314339584 Transmission_Gear "canboat type: LOOKUP";
CM_ SG_ 2314339584 Oil_pressure "canboat type: PRESSURE_UFIX16_HPA";
CM_ SG_ 2314339584 Oil_temperature "canboat type: TEMPERATURE_HIGH";
CM_ SG_ 2314339584 Discrete_Status_1 "canboat type: BITLOOKUP";
CM_ SG_ 2582775296 Inverter_Motor_Identifier "canboat type: UINT8";
CM_ SG_ 2582775296 Motor_Type "canboat type: UNSIGNED_INTEGER";
CM_ SG_ 2582775296 Motor_Voltage_Rating "canboat type: VOLTAGE_UFIX16_100MV";
CM_ SG_ 2582775296 Maximum_Continuous_Motor_Power "canboat type: POWER_UINT32";
CM_ SG_ 2582775296 Maximum_Boost_Motor_Power "canboat type: POWER_UINT32";
CM_ SG_ 2582775296 Maximum_Motor_Temperature_Rating "canboat type: TEMPERATURE";
CM_ SG_ 2582775296 Rated_Motor_Speed "canboat type: ROTATION_UFIX16_RPM";
CM_ SG_ 2582775296 Maximum_Controller_Temperature_Rating "canboat type: TEMPERATURE";
CM_ SG_ 2582775296 Motor_Shaft_Torque_Rating "canboat type: UINT16";
CM_ SG_ 2582775296 Motor_DC_Voltage_Derating_Threshold "canboat type: VOLTAGE_UFIX16_100MV";
CM_ SG_ 2582775296 Motor_DC_Voltage_Cut_Off_Threshold "canboat type: VOLTAGE_UFIX16_100MV";
CM_ SG_ 2582775296 Drive_Motor_Hours "canboat type: DURATION_UFIX32_S";
CM_ SG_ 2582775552 Energy_Storage_Identifier "canboat type: UINT8";
CM_ SG_ 2582775552 Motor_Type "canboat type: UNSIGNED_INTEGER";
CM_ SG_ 2582775552 Storage_Chemistry_Conversion "canboat type: UINT8";
CM_ SG_ 2582775552 Maximum_Temperature_Derating "canboat type: TEMPERATURE";
CM_ SG_ 2582775552 Maximum_Temperature_Shut_Off "canboat type: TEMPERATURE";
CM_ SG_ 2582775552 Minimum_Temperature_Derating "canboat type: TEMPERATURE";
CM_ SG_ 2582775552 Minimum_Temperature_Shut_Off "canboat type: TEMPERATURE";
CM_ SG_ 2582775552 Usable_Battery_Energy "canboat type: ENERGY_UINT32";
CM_ SG_ 2582775552 State_of_Health "canboat type: UINT8";
CM_ SG_ 2582775552 Battery_Cycle_Counter "canboat type: UINT16";
CM_ SG_ 2582775552 Battery_Full_Status "canboat type: UNSIGNED_INTEGER";
CM_ SG_ 2582775552 Battery_Empty_Status "canboat type: UNSIGNED_INTEGER";
CM_ SG_ 2582775552 Maximum_Charge__SOC_ "canboat type: UINT8";
CM_ SG_ 2582775552 Minimum_Charge__SOC_ "canboat type: UINT8";
CM_ SG_ 2515666944 Time_to_Empty "canboat type: DURATION_UFIX32_MS";
CM_ SG_ 2515666944 Distance_to_Empty "canboat type: LENGTH_UFIX32_CM";
CM_ SG_ 2515666944 Estimated_Fuel_Remaining "canboat type: VOLUME_UFIX16_L";
CM_ SG_ 2515666944 Trip_Run_Time "canboat type: DURATION_UFIX32_MS";
CM_ SG_ 2515667200 Instance "canboat type: LOOKUP";
CM_ SG_ 2515667200 Trip_Fuel_Used "canboat type: VOLUME_UFIX16_L";
CM_ SG_ 2515667200 Fuel_Rate__Average "canboat type: VOLUMETRIC_FLOW";
CM_ SG_ 2515667200 Fuel_Rate__Economy "canboat type: VOLUMETRIC_FLOW";
CM_ SG_ 2515667200 Instantaneous_Fuel_Economy "canboat type: VOLUMETRIC_FLOW";
CM_ SG_ 2515667456 Instance "canboat type: LOOKUP";
CM_ SG_ 2515667456 Rated_Engine_Speed "canboat type: ROTATION_UFIX16_RPM";
CM_ SG_ 2515667456 VIN "canboat type: STRING_LAU";
CM_ SG_ 2515667456 Software_ID "canboat type: STRING_LAU";
CM_ SG_ 2582776832 Sequence_ID "canboat type: UINT8";
CM_ SG_ 2582776832 Connection_ID "canboat type: UINT8";
CM_ SG_ 2582776832 State "canboat type: UINT8";
CM_ SG_ 2582776832 Status "canboat type: UINT8";
CM_ SG_ 2582776832 Operational_Status___Control "canboat type: UINT8";
CM_ SG_ 2582776832 PWM_Duty_Cycle "canboat type: UINT8";
CM_ SG_ 2582776832 TimeON "canboat type: UINT8";
CM_ SG_ 2582776832 TimeOFF "canboat type: UINT8";
CM_ SG_ 2381450496 Instance "canboat type: UINT8";
CM_ SG_ 2381450496 Indicator1 "canboat type: LOOKUP";
CM_ SG_ 2381450496 Indicator2 "canboat type: LOOKUP";
CM_ SG_ 2381450496 Indicator3 "canboat type: LOOKUP";
CM_ SG_ 2381450496 Indicator4 "canboat type: LOOKUP";
CM_ SG_ 2381450496 Indicator5 "canboat type: LOOKUP";
CM_ SG_ 2381450496 Indicator6 "canboat type: LOOKUP";
CM_ SG_ 2381450496 Indicator7 "canboat type: LOOKUP";
CM_ SG_ 2381450496 Indicator8 "canboat type: LOOKUP";
CM_ SG_ 2381450496 Indicator9 "canboat type: LOOKUP";
CM_ SG_ 2381450496 Indicator10 "canboat type: LOOKUP";
CM_ SG_ 2381450496 Indicator11 "canboat type: LOOKUP";
CM_ SG_ 2381450496 Indicator12 "canboat type: LOOKUP";
CM_ SG_ 2381450496 Indicator13 "canboat type: LOOKUP";
CM_ SG_ 2381450496 Indicator14 "canboat type: LOOKUP";
CM_ SG_ 2381450496 Indicator15 "canboat type: LOOKUP";
CM_ SG_ 2381450496 Indicator16 "canboat type: LOOKUP";
CM_ SG_ 2381450496 Indicator17 "canboat type: LOOKUP";
CM_ SG_ 2381450496 Indicator18 "canboat type: LOOKUP";
CM_ SG_ 2381450496 Indicator19 "canboat type: LOOKUP";
CM_ SG_ 2381450496 Indicator20 "canboat type: LOOKUP";
CM_ SG_ 2381450496 Indicator21 "canboat type: LOOKUP";
CM_ SG_ 2381450496 Indicator22 "canboat type: LOOKUP";
CM_ SG_ 2381450496 Indicator23 "canboat type: LOOKUP";
CM_ SG_ 2381450496 Indicator24 "canboat type: LOOKUP";
CM_ SG_ 2381450496 Indicator25 "canboat type: LOOKUP";
CM_ SG_ 2381450496 Indicator26 "canboat type: LOOKUP";
CM_ SG_ 2381450496 Indicator27 "canboat type: LOOKUP";
CM_ SG_ 2381450496 Indicator28 "canboat type: LOOKUP";
CM_ SG_ 2381450752 Instance "canboat type: UINT8";
CM_ SG_ 2381450752 Switch1 "canboat type: LOOKUP";
CM_ SG_ 2381450752 Switch2 "canboat type: LOOKUP";
CM_ SG_ 2381450752 Switch3 "canboat type: LOOKUP";
CM_ SG_ 2381450752 Switch4 "canboat type: LOOKUP";
CM_ SG_ 2381450752 Switch5 "canboat type: LOOKUP";
CM_ SG_ 2381450752 Switch6 "canboat type: LOOKUP";
CM_ SG_ 2381450752 Switch7 "canboat type: LOOKUP";
CM_ SG_ 2381450752 Switch8 "canboat type: LOOKUP";
CM_ SG_ 2381450752 Switch9 "canboat type: LOOKUP";
CM_ SG_ 2381450752 Switch10 "canboat type: LOOKUP";
CM_ SG_ 2381450752 Switch11 "canboat type: LOOKUP";
CM_ SG_ 2381450752 Switch12 "canboat type: LOOKUP";
CM_ SG_ 2381450752 Switch13 "canboat type: LOOKUP";
CM_ SG_ 2381450752 Switch14 "canboat type: LOOKUP";
CM_ SG_ 2381450752 Switch15 "canboat type: LOOKUP";
CM_ SG_ 2381450752 Switch16 "canboat type: LOOKUP";
CM_ SG_ 2381450752 Switch17 "canboat type: LOOKUP";
CM_ SG_ 2381450752 Switch18 "canboat type: LOOKUP";
CM_ SG_ 2381450752 Switch19 "canboat type: LOOKUP";
CM_ SG_ 2381450752 Switch20 "canboat type: LOOKUP";
CM_ SG_ 2381450752 Switch21 "canboat type: LOOKUP";
CM_ SG_ 2381450752 Switch22 "canboat type: LOOKUP";
CM_ SG_ 2381450752 Switch23 "canboat type: LOOKUP";
CM_ SG_ 2381450752 Switch24 "canboat type: LOOKUP";
CM_ SG_ 2381450752 Switch25 "canboat type: LOOKUP";
CM_ SG_ 2381450752 Switch26 "canboat type: LOOKUP";
CM_ SG_ 2381450752 Switch27 "canboat type: LOOKUP";
CM_ SG_ 2381450752 Switch28 "canboat type: LOOKUP";
CM_ SG_ 2582777600 Instance "canboat type: UINT8";
CM_ SG_ 2582777600 Number_of_Lines "canboat type: UINT8";
CM_ SG_ 2582777600 field16 "canboat type: NUMBER";
CM_ SG_ 2582777856 Instance "canboat type: UINT8";
CM_ SG_ 2582777856 Number_of_Lines "canboat type: UINT8";
CM_ SG_ 2582777856 field16 "canboat type: NUMBER";
CM_ SG_ 2582778112 Instance "canboat type: UNSIGNED_INTEGER";
CM_ SG_ 2582778112 Type "canboat type: LOOKUP";
CM_ SG_ 2582778112 Level "canboat type: PERCENTAGE_FIX16";
CM_ SG_ 2582778112 Capacity "canboat type: VOLUME_UFIX32_DL";
CM_ SG_ 2582778368 SID "canboat type: UINT8";
CM_ SG_ 2582778368 Instance "canboat type: UINT8";
CM_ SG_ 2582778368 DC_Type "canboat type: LOOKUP";
CM_ SG_ 2582778368 State_of_Charge "canboat type: PERCENTAGE_UINT8";
CM_ SG_ 2582778368 State_of_Health "canboat type: PERCENTAGE_UINT8";
CM_ SG_ 2582778368 Time_Remaining "Time remaining at current rate of discharge; canboat type: DURATION_UFIX16_MIN";
CM_ SG_ 2582778368 Ripple_Voltage "canboat type: VOLTAGE_UFIX16_1MV";
CM_ SG_ 2582778368 Remaining_capacity "canboat type: ELECTRIC_CHARGE_UFIX16_AH";
CM_ SG_ 2582778624 Instance "canboat type: UINT8";
CM_ SG_ 2582778624 Battery_Instance "canboat type: UINT8";
CM_ SG_ 2582778624 Operating_State "canboat type: LOOKUP";
CM_ SG_ 2582778624 Charge_Mode "canboat type: LOOKUP";
CM_ SG_ 2582778624 Enabled "canboat type: LOOKUP";
CM_ SG_ 2582778624 Equalization_Pending "canboat type: LOOKUP";
CM_ SG_ 2582778624 Equalization_Time_Remaining "canboat type: DURATION_UFIX16_MIN";
CM_ SG_ 2582778880 Instance "canboat type: UINT8";
CM_ SG_ 2582778880 Voltage "canboat type: VOLTAGE_FIX16_10MV";
CM_ SG_ 2582778880 Current "canboat type: CURRENT_FIX16_DA";
CM_ SG_ 2582778880 Temperature "canboat type: TEMPERATURE";
CM_ SG_ 2582778880 SID "canboat type: UINT8";
CM_ SG_ 2582779136 Instance "canboat type: UINT8";
CM_ SG_ 2582779136 AC_Instance "canboat type: UINT8";
CM_ SG_ 2582779136 DC_Instance "canboat type: UINT8";
CM_ SG_ 2582779136 Operating_State "canboat type: LOOKUP";
CM_ SG_ 2582779136 Inverter_Enable "canboat type: LOOKUP";
CM_ SG_ 2582779392 Instance "canboat type: UINT8";
CM_ SG_ 2582779392 Battery_Instance "canboat type: UINT8";
CM_ SG_ 2582779392 Charger_Enable_Disable "canboat type: LOOKUP";
CM_ SG_ 2582779392 Charge_Current_Limit "canboat type: PERCENTAGE_UINT8";
CM_ SG_ 2582779392 Charging_Algorithm "canboat type: LOOKUP";
CM_ SG_ 2582779392 Charger_Mode "canboat type: LOOKUP";
CM_ SG_ 2582779392 Estimated_Temperature "If there is no battery temperature sensor the charger will use this field to steer the charging algorithm; canboat type: LOOKUP";
CM_ SG_ 2582779392 Equalize_One_Time_Enable_Disable "canboat type: LOOKUP";
CM_ SG_ 2582779392 Over_Charge_Enable_Disable "canboat type: LOOKUP";
CM_ SG_ 2582779392 Equalize_Time "canboat type: DURATION_UFIX16_MIN";
CM_ SG_ 2582779648 Instance "canboat type: UINT8";
CM_ SG_ 2582779648 AC_Instance "canboat type: UINT8";
CM_ SG_ 2582779648 DC_Instance "canboat type: UINT8";
CM_ SG_ 2582779648 Inverter_Enable_Disable "canboat type: LOOKUP";
CM_ SG_ 2582779648 Inverter_Mode "canboat type: LOOKUP";
CM_ SG_ 2582779648 Load_Sense_Enable_Disable "canboat type: LOOKUP";
CM_ SG_ 2582779648 Load_Sense_Power_Threshold "canboat type: POWER_UINT16";
CM_ SG_ 2582779648 Load_Sense_Interval "canboat type: DURATION_UFIX16_CS";
CM_ SG_ 2582779904 Instance "canboat type: UINT8";
CM_ SG_ 2582779904 Generator_Instance "canboat type: UINT8";
CM_ SG_ 2582779904 AGS_Mode "canboat type: LOOKUP";
CM_ SG_ 2582780160 Instance "canboat type: UINT8";
CM_ SG_ 2582780160 Battery_Type "canboat type: LOOKUP";
CM_ SG_ 2582780160 Supports_Equalization "canboat type: LOOKUP";
CM_ SG_ 2582780160 Nominal_Voltage "canboat type: LOOKUP";
CM_ SG_ 2582780160 Chemistry "canboat type: LOOKUP";
CM_ SG_ 2582780160 Capacity "canboat type: ELECTRIC_CHARGE_UFIX16_AH";
CM_ SG_ 2582780160 Temperature_Coefficient "canboat type: PERCENTAGE_INT8";
CM_ SG_ 2582780160 Peukert_Exponent "canboat type: PEUKERT_EXPONENT";
CM_ SG_ 2582780160 Charge_Efficiency_Factor "canboat type: PERCENTAGE_INT8";
CM_ SG_ 2582780416 Instance "canboat type: UINT8";
CM_ SG_ 2582780416 Generator_Instance "canboat type: UINT8";
CM_ SG_ 2582780416 AGS_Operating_State "canboat type: LOOKUP";
CM_ SG_ 2582780416 Generator_State "canboat type: LOOKUP";
CM_ SG_ 2582780416 Generator_On_Reason "canboat type: LOOKUP";
CM_ SG_ 2582780416 Generator_Off_Reason "canboat type: LOOKUP";
CM_ SG_ 2582839296 SID "canboat type: UINT8";
CM_ SG_ 2582839296 Connection_Number "canboat type: UINT8";
CM_ SG_ 2582839296 AC_RMS_Current "canboat type: CURRENT_UFIX16_DA";
CM_ SG_ 2582839296 Power "canboat type: POWER_INT32";
CM_ SG_ 2582839552 SID "canboat type: UINT8";
CM_ SG_ 2582839552 Connection_Number "canboat type: UINT8";
CM_ SG_ 2582839552 AC_RMS_Current "canboat type: CURRENT_UFIX16_DA";
CM_ SG_ 2582839552 Power "canboat type: POWER_INT32";
CM_ SG_ 2582839808 SID "canboat type: UINT8";
CM_ SG_ 2582839808 Connection_Number "canboat type: UINT8";
CM_ SG_ 2582839808 AC_RMS_Current "canboat type: CURRENT_UFIX16_DA";
CM_ SG_ 2582839808 Power "canboat type: POWER_INT32";
CM_ SG_ 2582840064 SID "canboat type: UINT8";
CM_ SG_ 2582840064 Connection_Number "canboat type: UINT8";
CM_ SG_ 2582840064 AC_Voltage_Line_to_Neutral "canboat type: VOLTAGE_UFIX16_100MV";
CM_ SG_ 2582840064 AC_Voltage_Line_to_Line "canboat type: VOLTAGE_UFIX16_100MV";
CM_ SG_ 2582840064 Frequency "canboat type: FREQUENCY_UFIX16";
CM_ SG_ 2582840320 SID "canboat type: UINT8";
CM_ SG_ 2582840320 Connection_Number "canboat type: UINT8";
CM_ SG_ 2582840320 AC_Voltage_Line_to_Neutral "canboat type: VOLTAGE_UFIX16_100MV";
CM_ SG_ 2582840320 AC_Voltage_Line_to_Line "canboat type: VOLTAGE_UFIX16_100MV";
CM_ SG_ 2582840320 Frequency "canboat type: FREQUENCY_UFIX16";
CM_ SG_ 2582840576 SID "canboat type: UINT8";
CM_ SG_ 2582840576 Connection_Number "canboat type: UINT8";
CM_ SG_ 2582840576 AC_Voltage_Line_to_Neutral "canboat type: VOLTAGE_UFIX16_100MV";
CM_ SG_ 2582840576 AC_Voltage_Line_to_Line "canboat type: VOLTAGE_UFIX16_100MV";
CM_ SG_ 2582840576 Frequency "canboat type: FREQUENCY_UFIX16";
CM_ SG_ 2582840832 SID "canboat type: UINT8";
CM_ SG_ 2582840832 Connection_Number "canboat type: UINT8";
CM_ SG_ 2582840832 Operating_State "canboat type: LOOKUP";
CM_ SG_ 2582840832 Temperature_State "canboat type: LOOKUP";
CM_ SG_ 2582840832 Overload_State "canboat type: LOOKUP";
CM_ SG_ 2582840832 Low_DC_Voltage_State "canboat type: LOOKUP";
CM_ SG_ 2582840832 Ripple_State "canboat type: LOOKUP";
CM_ SG_ 2582841088 SID "canboat type: UINT8";
CM_ SG_ 2582841088 Connection_Number "canboat type: UINT8";
CM_ SG_ 2582841088 DC_Voltage "canboat type: VOLTAGE_UFIX16_100MV";
CM_ SG_ 2582841088 DC_Current "canboat type: CURRENT_FIX24_CA";
CM_ SG_ 2582904832 SID "canboat type: UINT8";
CM_ SG_ 2582904832 Leeway_Angle "canboat type: ANGLE_FIX16";
CM_ SG_ 2582905088 SID "canboat type: UINT8";
CM_ SG_ 2582905088 Longitudinal_Acceleration "canboat type: INT16";
CM_ SG_ 2582905088 Transverse_Acceleration "canboat type: INT16";
CM_ SG_ 2582905088 Vertical_Acceleration "canboat type: INT16";
CM_ SG_ 2582905344 Inverter_Motor_Controller "canboat type: UINT8";
CM_ SG_ 2582905344 Active_Motor_Mode "canboat type: UNSIGNED_INTEGER";
CM_ SG_ 2582905344 Brake_Mode "canboat type: UNSIGNED_INTEGER";
CM_ SG_ 2582905344 Rotational_Shaft_Speed "canboat type: ROTATION_UFIX16_RPM";
CM_ SG_ 2582905344 Motor_DC_Voltage "canboat type: VOLTAGE_UFIX16_100MV";
CM_ SG_ 2582905344 Motor_DC_Current "canboat type: CURRENT_FIX16_DA";
CM_ SG_ 2582905600 Energy_Storage_Identifier "canboat type: UINT8";
CM_ SG_ 2582905600 Battery_Status "canboat type: UNSIGNED_INTEGER";
CM_ SG_ 2582905600 Isolation_Status "canboat type: UNSIGNED_INTEGER";
CM_ SG_ 2582905600 Battery_Error "canboat type: UNSIGNED_INTEGER";
CM_ SG_ 2582905600 Battery_Voltage "canboat type: VOLTAGE_UFIX16_100MV";
CM_ SG_ 2582905600 Battery_Current "canboat type: CURRENT_FIX16_DA";
CM_ SG_ 2582906368 SID "canboat type: UINT8";
CM_ SG_ 2582906368 Identifier "canboat type: UINT8";
CM_ SG_ 2582906368 Direction_Control "canboat type: LOOKUP";
CM_ SG_ 2582906368 Power_Enabled "canboat type: LOOKUP";
CM_ SG_ 2582906368 Retract_Control "canboat type: LOOKUP";
CM_ SG_ 2582906368 Speed_Control "canboat type: PERCENTAGE_UINT8";
CM_ SG_ 2582906368 Control_Events "canboat type: BITLOOKUP";
CM_ SG_ 2582906368 Command_Timeout "canboat type: DURATION_UFIX8_5MS";
CM_ SG_ 2582906368 Azimuth_Control "canboat type: ANGLE_UFIX16";
CM_ SG_ 2582906624 Identifier "canboat type: UINT8";
CM_ SG_ 2582906624 Motor_Type "canboat type: LOOKUP";
CM_ SG_ 2582906624 Power_Rating "canboat type: POWER_UINT16";
CM_ SG_ 2582906624 Maximum_Temperature_Rating "canboat type: TEMPERATURE";
CM_ SG_ 2582906624 Maximum_Rotational_Speed "canboat type: ROTATION_UFIX16_RPM";
CM_ SG_ 2582906880 SID "canboat type: UINT8";
CM_ SG_ 2582906880 Identifier "canboat type: UINT8";
CM_ SG_ 2582906880 Motor_Events "canboat type: BITLOOKUP";
CM_ SG_ 2582906880 Current "canboat type: CURRENT_UFIX8_A";
CM_ SG_ 2582906880 Temperature "canboat type: TEMPERATURE";
CM_ SG_ 2582906880 Operating_Time "canboat type: DURATION_UFIX16_MIN";
CM_ SG_ 2314535680 SID "canboat type: UINT8";
CM_ SG_ 2314535680 Speed_Water_Referenced "canboat type: SPEED_UFIX16_CM";
CM_ SG_ 2314535680 Speed_Ground_Referenced "canboat type: SPEED_UFIX16_CM";
CM_ SG_ 2314535680 Speed_Water_Referenced_Type "canboat type: LOOKUP";
CM_ SG_ 2314535680 Speed_Direction "canboat type: UNSIGNED_INTEGER";
CM_ SG_ 2381646592 SID "canboat type: UINT8";
CM_ SG_ 2381646592 Depth "Depth below transducer; canboat type: LENGTH_UFIX32_CM";
CM_ SG_ 2381646592 Offset "Distance between transducer and surface (positive) or keel (negative); canboat type: DISTANCE_FIX16_MM";
CM_ SG_ 2381646592 Range "Max measurement range; canboat type: LENGTH_UFIX8_DAM";
CM_ SG_ 2582975232 Date "canboat type: DATE";
CM_ SG_ 2582975232 Time "Seconds since midnight; canboat type: TIME";
CM_ SG_ 2582975232 Log "Total cumulative distance; canboat type: LENGTH_UFIX32_M";
CM_ SG_ 2582975232 Trip_Log "Distance since last reset; canboat type: LENGTH_UFIX32_M";
CM_ SG_ 2314602496 SID "canboat type: UINT8";
CM_ SG_ 2314602496 Target_ID__ "Number of route, waypoint, event, mark, etc.; canboat type: UINT16";
CM_ SG_ 2314602496 Track_Status "canboat type: LOOKUP";
CM_ SG_ 2314602496 Reported_Target "canboat type: LOOKUP";
CM_ SG_ 2314602496 Target_Acquisition "canboat type: LOOKUP";
CM_ SG_ 2314602496 Bearing_Reference "canboat type: LOOKUP";
CM_ SG_ 2314602496 Bearing "canboat type: ANGLE_UFIX16";
CM_ SG_ 2314602496 Distance "canboat type: DISTANCE_FIX32_CM";
CM_ SG_ 2314602496 Course "canboat type: ANGLE_UFIX16";
CM_ SG_ 2314602496 Speed "canboat type: SPEED_UFIX16_CM";
CM_ SG_ 2314602496 CPA "canboat type: DISTANCE_FIX32_CM";
CM_ SG_ 2314602496 TCPA "negative = time elapsed since event, positive = time to go; canboat type: DURATION_FIX32_MS";
CM_ SG_ 2314602496 UTC_of_Fix "Seconds since midnight; canboat type: TIME";
CM_ SG_ 2314602496 Name "canboat type: STRING_LAU";
CM_ SG_ 2314602496 Reference_Target "canboat type: LOOKUP";
CM_ SG_ 2583042560 SID "canboat type: UINT8";
CM_ SG_ 2583042560 Elevator_Car_ID "canboat type: UINT8";
CM_ SG_ 2583042560 Elevator_Car_Usage "canboat type: UINT8";
CM_ SG_ 2583042560 Smoke_Sensor_Status "canboat type: UNSIGNED_INTEGER";
CM_ SG_ 2583042560 Limit_Switch_Sensor_Status "canboat type: UNSIGNED_INTEGER";
CM_ SG_ 2583042560 Proximity_Switch_Sensor_Status "canboat type: UNSIGNED_INTEGER";
CM_ SG_ 2583042560 Inertial_Measurement_Unit__IMU__Sensor_Status "canboat type: UNSIGNED_INTEGER";
CM_ SG_ 2583042560 Elevator_Load_Limit_Status "canboat type: UNSIGNED_INTEGER";
CM_ SG_ 2583042560 Elevator_Load_Balance_Status "canboat type: UNSIGNED_INTEGER";
CM_ SG_ 2583042560 Elevator_Load_Sensor_1_Status "canboat type: UNSIGNED_INTEGER";
CM_ SG_ 2583042560 Elevator_Load_Sensor_2_Status "canboat type: UNSIGNED_INTEGER";
CM_ SG_ 2583042560 Elevator_Load_Sensor_3_Status "canboat type: UNSIGNED_INTEGER";
CM_ SG_ 2583042560 Elevator_Load_Sensor_4_Status "canboat type: UNSIGNED_INTEGER";
CM_ SG_ 2583042560 Elevator_Car_Motion_Status "canboat type: UNSIGNED_INTEGER";
CM_ SG_ 2583042560 Elevator_Car_Door_Status "canboat type: UNSIGNED_INTEGER";
CM_ SG_ 2583042560 Elevator_Car_Emergency_Button_Status "canboat type: UNSIGNED_INTEGER";
CM_ SG_ 2583042560 Elevator_Car_Buzzer_Status "canboat type: UNSIGNED_INTEGER";
CM_ SG_ 2583042560 Open_Door_Button_Status "canboat type: UNSIGNED_INTEGER";
CM_ SG_ 2583042560 Close_Door_Button_Status "canboat type: UNSIGNED_INTEGER";
CM_ SG_ 2583042560 Current_Deck "canboat type: UINT8";
CM_ SG_ 2583042560 Destination_Deck "canboat type: UINT8";
CM_ SG_ 2583042560 Total_Number_of_Decks "canboat type: UINT8";
CM_ SG_ 2583042560 Weight_of_Load_Cell_1 "canboat type: UINT16";
CM_ SG_ 2583042560 Weight_of_Load_Cell_2 "canboat type: UINT16";
CM_ SG_ 2583042560 Weight_of_Load_Cell_3 "canboat type: UINT16";
CM_ SG_ 2583042560 Weight_of_Load_Cell_4 "canboat type: UINT16";
CM_ SG_ 2583042560 Speed_of_Elevator_Car "canboat type: SPEED_FIX16_CM";
CM_ SG_ 2583042560 Elevator_Brake_Status "canboat type: UNSIGNED_INTEGER";
CM_ SG_ 2583042560 Elevator_Motor_rotation_control_Status "canboat type: UNSIGNED_INTEGER";
CM_ SG_ 2583101440 SID "canboat type: UINT8";
CM_ SG_ 2583101440 Elevator_Car_ID "canboat type: UINT8";
CM_ SG_ 2583101440 Elevator_Car_Usage "canboat type: UINT8";
CM_ SG_ 2583101440 Motor_Acceleration_Deceleration_profile_selection "canboat type: UNSIGNED_INTEGER";
CM_ SG_ 2583101440 Motor_Rotational_Control_Status "canboat type: UNSIGNED_INTEGER";
CM_ SG_ 2583101696 SID "canboat type: UINT8";
CM_ SG_ 2583101696 Elevator_Call_Button_ID "canboat type: UINT8";
CM_ SG_ 2583101696 Deck_Button_ID "canboat type: UINT8";
CM_ SG_ 2583101696 Elevator_Car_Usage "canboat type: UINT8";
CM_ SG_ 2583101696 Elevator_Car_Button_Selection "canboat type: UINT8";
CM_ SG_ 2583103488 SID "canboat type: UINT8";
CM_ SG_ 2583103488 Windlass_ID "canboat type: UINT8";
CM_ SG_ 2583103488 Windlass_Direction_Control "canboat type: LOOKUP";
CM_ SG_ 2583103488 Anchor_Docking_Control "canboat type: LOOKUP";
CM_ SG_ 2583103488 Speed_Control_Type "canboat type: LOOKUP";
CM_ SG_ 2583103488 Speed_Control "0=Off,Single speed:1-100=On,Dual Speed:1-49=Slow/50-100=Fast,Proportional:10-100; canboat type: BINARY";
CM_ SG_ 2583103488 Power_Enable "canboat type: LOOKUP";
CM_ SG_ 2583103488 Mechanical_Lock "canboat type: LOOKUP";
CM_ SG_ 2583103488 Deck_and_Anchor_Wash "canboat type: LOOKUP";
CM_ SG_ 2583103488 Anchor_Light "canboat type: LOOKUP";
CM_ SG_ 2583103488 Command_Timeout "If timeout elapses the thruster stops operating and reverts to static mode; canboat type: DURATION_UFIX8_5MS";
CM_ SG_ 2583103488 Windlass_Control_Events "canboat type: BITLOOKUP";
CM_ SG_ 2583103744 SID "canboat type: UINT8";
CM_ SG_ 2583103744 Windlass_ID "canboat type: UINT8";
CM_ SG_ 2583103744 Windlass_Direction_Control "canboat type: LOOKUP";
CM_ SG_ 2583103744 Windlass_Motion_Status "canboat type: LOOKUP";
CM_ SG_ 2583103744 Rode_Type_Status "canboat type: LOOKUP";
CM_ SG_ 2583103744 Rode_Counter_Value "canboat type: LENGTH_UFIX16_DM";
CM_ SG_ 2583103744 Windlass_Line_Speed "canboat type: SPEED_UFIX16_CM";
CM_ SG_ 2583103744 Anchor_Docking_Status "canboat type: LOOKUP";
CM_ SG_ 2583103744 Windlass_Operating_Events "canboat type: BITLOOKUP";
CM_ SG_ 2583104000 SID "canboat type: UINT8";
CM_ SG_ 2583104000 Windlass_ID "canboat type: UINT8";
CM_ SG_ 2583104000 Windlass_Monitoring_Events "canboat type: BITLOOKUP";
CM_ SG_ 2583104000 Controller_voltage "canboat type: VOLTAGE_UFIX8_200MV";
CM_ SG_ 2583104000 Motor_current "canboat type: CURRENT_UFIX8_A";
CM_ SG_ 2583104000 Total_Motor_Time "canboat type: DURATION_UFIX16_MIN";
CM_ SG_ 2583104512 Actuator_Identifier "canboat type: UINT8";
CM_ SG_ 2583104512 Commanded_Device_Position "canboat type: UINT8";
CM_ SG_ 2583104512 Device_Position "canboat type: UINT8";
CM_ SG_ 2583104512 Maximum_Device_Travel "canboat type: UINT16";
CM_ SG_ 2583104512 Direction_of_Travel "canboat type: UINT8";
CM_ SG_ 2314731776 Latitude "canboat type: GEO_LAT_FIX32";
CM_ SG_ 2314731776 Longitude "canboat type: GEO_LON_FIX32";
CM_ SG_ 2314732032 SID "canboat type: UINT8";
CM_ SG_ 2314732032 COG_Reference "canboat type: LOOKUP";
CM_ SG_ 2314732032 COG "canboat type: ANGLE_UFIX16";
CM_ SG_ 2314732032 SOG "canboat type: SPEED_UFIX16_CM";
CM_ SG_ 2314732288 SID "canboat type: UINT8";
CM_ SG_ 2314732288 Time_Delta "canboat type: DURATION_UFIX8_5MS";
CM_ SG_ 2314732288 Latitude_Delta "canboat type: GEO_DELTA_FIX24";
CM_ SG_ 2314732288 Longitude_Delta "canboat type: GEO_DELTA_FIX24";
CM_ SG_ 2314732544 SID "canboat type: UINT8";
CM_ SG_ 2314732544 Time_Delta "canboat type: DURATION_UFIX8_5MS";
CM_ SG_ 2314732544 GNSS_Quality "canboat type: LOOKUP";
CM_ SG_ 2314732544 Direction "canboat type: LOOKUP";
CM_ SG_ 2314732544 COG "canboat type: ANGLE_UFIX16";
CM_ SG_ 2314732544 Altitude_Delta "canboat type: DISTANCE_FIX24_MM";
CM_ SG_ 2381841664 SID "canboat type: UINT8";
CM_ SG_ 2381841664 Date "canboat type: DATE";
CM_ SG_ 2381841664 Time "Seconds since midnight; canboat type: TIME";
CM_ SG_ 2381841664 Latitude "canboat type: GEO_LAT_FIX64";
CM_ SG_ 2381841664 Longitude "canboat type: GEO_LON_FIX64";
CM_ SG_ 2381841664 Altitude "Altitude referenced to WGS-84; canboat type: DISTANCE_FIX64";
CM_ SG_ 2381841664 GNSS_type "canboat type: LOOKUP";
CM_ SG_ 2381841664 Method "canboat type: LOOKUP";
CM_ SG_ 2381841664 Integrity "canboat type: LOOKUP";
CM_ SG_ 2381841664 Number_of_SVs "Number of satellites used in solution; canboat type: UINT8";
CM_ SG_ 2381841664 HDOP "Horizontal dilution of precision; canboat type: DILUTION_OF_PRECISION_FIX16";
CM_ SG_ 2381841664 PDOP "Positional dilution of precision; canboat type: DILUTION_OF_PRECISION_FIX16";
CM_ SG_ 2381841664 Geoidal_Separation "Geoidal Separation; canboat type: DISTANCE_FIX32_CM";
CM_ SG_ 2381841664 Reference_Stations "Number of reference stations; canboat type: UINT8";
CM_ SG_ 2381841664 field344 "canboat type: NUMBER";
CM_ SG_ 2381842688 Date "canboat type: DATE";
CM_ SG_ 2381842688 Time "Seconds since midnight; canboat type: TIME";
CM_ SG_ 2381842688 Local_Offset "canboat type: DURATION_FIX16_MIN";
CM_ SG_ 2448952832 Message_ID "canboat type: LOOKUP";
CM_ SG_ 2448952832 Repeat_Indicator "canboat type: LOOKUP";
CM_ SG_ 2448952832 User_ID "canboat type: MMSI";
CM_ SG_ 2448952832 Longitude "canboat type: GEO_LON_FIX32";
CM_ SG_ 2448952832 Latitude "canboat type: GEO_LAT_FIX32";
CM_ SG_ 2448952832 Position_Accuracy "canboat type: LOOKUP";
CM_ SG_ 2448952832 RAIM "canboat type: LOOKUP";
CM_ SG_ 2448952832 Time_Stamp "0-59 = UTC second when the report was generated; canboat type: LOOKUP";
CM_ SG_ 2448952832 COG "canboat type: ANGLE_UFIX16";
CM_ SG_ 2448952832 SOG "canboat type: SPEED_UFIX16_CM";
CM_ SG_ 2448952832 Communication_State "Information used by the TDMA slot allocation algorithm and synchronization information; canboat type: BINARY";
CM_ SG_ 2448952832 AIS_Transceiver_information "canboat type: LOOKUP";
CM_ SG_ 2448952832 Heading "True heading; canboat type: ANGLE_UFIX16";
CM_ SG_ 2448952832 Rate_of_Turn "canboat type: ROTATION_FIX16";
CM_ SG_ 2448952832 Nav_Status "canboat type: LOOKUP";
CM_ SG_ 2448952832 Special_Maneuver_Indicator "canboat type: LOOKUP";
CM_ SG_ 2448952832 Spare "canboat type: SPARE";
CM_ SG_ 2448952832 Sequence_ID "canboat type: UINT8";
CM_ SG_ 2448953088 Message_ID "canboat type: LOOKUP";
CM_ SG_ 2448953088 Repeat_Indicator "canboat type: LOOKUP";
CM_ SG_ 2448953088 User_ID "canboat type: MMSI";
CM_ SG_ 2448953088 Longitude "canboat type: GEO_LON_FIX32";
CM_ SG_ 2448953088 Latitude "canboat type: GEO_LAT_FIX32";
CM_ SG_ 2448953088 Position_Accuracy "canboat type: LOOKUP";
CM_ SG_ 2448953088 RAIM "canboat type: LOOKUP";
CM_ SG_ 2448953088 Time_Stamp "canboat type: LOOKUP";
CM_ SG_ 2448953088 COG "canboat type: ANGLE_UFIX16";
CM_ SG_ 2448953088 SOG "canboat type: SPEED_UFIX16_CM";
CM_ SG_ 2448953088 Communication_State "Information used by the TDMA slot allocation algorithm and synchronization information; canboat type: BINARY";
CM_ SG_ 2448953088 AIS_Transceiver_information "canboat type: LOOKUP";
CM_ SG_ 2448953088 Heading "True heading; canboat type: ANGLE_UFIX16";
CM_ SG_ 2448953088 Regional_Application "canboat type: SPARE";
CM_ SG_ 2448953088 Regional_Application_B "canboat type: SPARE";
CM_ SG_ 2448953088 Unit_type "canboat type: LOOKUP";
CM_ SG_ 2448953088 Integrated_Display "Whether the unit can show messages 12 and 14; canboat type: LOOKUP";
CM_ SG_ 2448953088 DSC "canboat type: LOOKUP";
CM_ SG_ 2448953088 Band "canboat type: LOOKUP";
CM_ SG_ 2448953088 Can_handle_Msg_22 "canboat type: LOOKUP";
CM_ SG_ 2448953088 AIS_mode "canboat type: LOOKUP";
CM_ SG_ 2448953088 AIS_communication_state "canboat type: LOOKUP";
CM_ SG_ 2448953088 Sequence_ID "canboat type: UINT8";
CM_ SG_ 2448953344 Message_ID "canboat type: LOOKUP";
CM_ SG_ 2448953344 Repeat_Indicator "canboat type: LOOKUP";
CM_ SG_ 2448953344 User_ID "canboat type: MMSI";
CM_ SG_ 2448953344 Longitude "canboat type: GEO_LON_FIX32";
CM_ SG_ 2448953344 Latitude "canboat type: GEO_LAT_FIX32";
CM_ SG_ 2448953344 Position_Accuracy "canboat type: LOOKUP";
CM_ SG_ 2448953344 RAIM "canboat type: LOOKUP";
CM_ SG_ 2448953344 Time_Stamp "canboat type: LOOKUP";
CM_ SG_ 2448953344 COG "canboat type: ANGLE_UFIX16";
CM_ SG_ 2448953344 SOG "canboat type: SPEED_UFIX16_CM";
CM_ SG_ 2448953344 Regional_Application "canboat type: SPARE";
CM_ SG_ 2448953344 Regional_Application_B "canboat type: SPARE";
CM_ SG_ 2448953344 Type_of_ship "canboat type: LOOKUP";
CM_ SG_ 2448953344 True_Heading "canboat type: ANGLE_UFIX16";
CM_ SG_ 2448953344 GNSS_type "canboat type: LOOKUP";
CM_ SG_ 2448953344 Length "canboat type: LENGTH_UFIX16_DM";
CM_ SG_ 2448953344 Beam "canboat type: LENGTH_UFIX16_DM";
CM_ SG_ 2448953344 Position_reference_from_Starboard "canboat type: LENGTH_UFIX16_DM";
CM_ SG_ 2448953344 Position_reference_from_Bow "canboat type: LENGTH_UFIX16_DM";
CM_ SG_ 2448953344 Name "canboat type: STRING_FIX";
CM_ SG_ 2448953344 DTE "canboat type: LOOKUP";
CM_ SG_ 2448953344 AIS_mode "canboat type: LOOKUP";
CM_ SG_ 2448953344 Spare "canboat type: SPARE";
CM_ SG_ 2448953344 AIS_Transceiver_information "canboat type: LOOKUP";
CM_ SG_ 2448953600 Message_ID "canboat type: LOOKUP";
CM_ SG_ 2448953600 Repeat_Indicator "canboat type: LOOKUP";
CM_ SG_ 2448953600 User_ID "canboat type: MMSI";
CM_ SG_ 2448953600 Longitude "canboat type: GEO_LON_FIX32";
CM_ SG_ 2448953600 Latitude "canboat type: GEO_LAT_FIX32";
CM_ SG_ 2448953600 Position_Accuracy "canboat type: LOOKUP";
CM_ SG_ 2448953600 RAIM "canboat type: LOOKUP";
CM_ SG_ 2448953600 Time_Stamp "canboat type: LOOKUP";
CM_ SG_ 2448953600 Length_Diameter "canboat type: LENGTH_UFIX16_DM";
CM_ SG_ 2448953600 Beam_Diameter "canboat type: LENGTH_UFIX16_DM";
CM_ SG_ 2448953600 Position_Reference_from_Starboard_Edge "canboat type: LENGTH_UFIX16_DM";
CM_ SG_ 2448953600 Position_Reference_from_True_North_Facing_Edge "canboat type: LENGTH_UFIX16_DM";
CM_ SG_ 2448953600 AtoN_Type "canboat type: LOOKUP";
CM_ SG_ 2448953600 Off_Position_Indicator "canboat type: LOOKUP";
CM_ SG_ 2448953600 Virtual_AtoN_Flag "canboat type: LOOKUP";
CM_ SG_ 2448953600 Assigned_Mode_Flag "canboat type: LOOKUP";
CM_ SG_ 2448953600 Spare "canboat type: SPARE";
CM_ SG_ 2448953600 Position_Fixing_Device_Type "canboat type: LOOKUP";
CM_ SG_ 2448953600 AtoN_Status "00000000 = default; canboat type: BINARY";
CM_ SG_ 2448953600 AIS_Transceiver_information "canboat type: LOOKUP";
CM_ SG_ 2448953600 AtoN_Name "canboat type: STRING_LAU";
CM_ SG_ 2583172096 Local_Datum "defined in IHO Publication S-60, Appendices B and C. First three chars are datum ID as per IHO tables. Fourth char is local datum subdivision code.; canboat type: STRING_FIX";
CM_ SG_ 2583172096 Delta_Latitude "canboat type: GEO_LAT_FIX32";
CM_ SG_ 2583172096 Delta_Longitude "canboat type: GEO_LON_FIX32";
CM_ SG_ 2583172096 Delta_Altitude "canboat type: DISTANCE_FIX32_CM";
CM_ SG_ 2583172096 Reference_Datum "defined in IHO Publication S-60, Appendices B and C. First three chars are datum ID as per IHO tables. Fourth char is local datum subdivision code.; canboat type: STRING_FIX";
CM_ SG_ 2583172352 Delta_X "Delta shift in X axis from WGS 84; canboat type: DISTANCE_FIX32_CM";
CM_ SG_ 2583172352 Delta_Y "Delta shift in Y axis from WGS 84; canboat type: DISTANCE_FIX32_CM";
CM_ SG_ 2583172352 Delta_Z "Delta shift in Z axis from WGS 84; canboat type: DISTANCE_FIX32_CM";
CM_ SG_ 2583172352 Rotation_in_X "Rotational shift in X axis from WGS 84. Rotations presented use the geodetic sign convention.  When looking along the positive axis towards the origin, counter-clockwise rotations are positive.; canboat type: FLOAT_RAD";
CM_ SG_ 2583172352 Rotation_in_Y "Rotational shift in Y axis from WGS 84. Rotations presented use the geodetic sign convention.  When looking along the positive axis towards the origin, counter-clockwise rotations are positive.; canboat type: FLOAT_RAD";
CM_ SG_ 2583172352 Rotation_in_Z "Rotational shift in Z axis from WGS 84. Rotations presented use the geodetic sign convention.  When looking along the positive axis towards the origin, counter-clockwise rotations are positive.; canboat type: FLOAT_RAD";
CM_ SG_ 2583172352 Scale "canboat type: FLOAT_PPM";
CM_ SG_ 2583172352 Ellipsoid_Semi_major_Axis "Semi-major axis (a) of the User Datum ellipsoid; canboat type: DISTANCE_FIX32_CM";
CM_ SG_ 2583172352 Ellipsoid_Flattening_Inverse "Flattening (1/f) of the User Datum ellipsoid; canboat type: FLOAT";
CM_ SG_ 2583172352 Datum_Name "4 character code from IHO Publication S-60,Appendices B and C. First three chars are datum ID as per IHO tables. Fourth char is local datum subdivision code.; canboat type: STRING_FIX";
CM_ SG_ 2381906688 SID "canboat type: UINT8";
CM_ SG_ 2381906688 XTE_mode "canboat type: LOOKUP";
CM_ SG_ 2381906688 Navigation_Terminated "canboat type: LOOKUP";
CM_ SG_ 2381906688 XTE "canboat type: DISTANCE_FIX32_CM";
CM_ SG_ 2381906944 SID "canboat type: UINT8";
CM_ SG_ 2381906944 Distance_to_Waypoint "canboat type: LENGTH_UFIX32_CM";
CM_ SG_ 2381906944 Course_Bearing_reference "canboat type: LOOKUP";
CM_ SG_ 2381906944 Perpendicular_Crossed "canboat type: LOOKUP";
CM_ SG_ 2381906944 Arrival_Circle_Entered "canboat type: LOOKUP";
CM_ SG_ 2381906944 Calculation_Type "canboat type: LOOKUP";
CM_ SG_ 2381906944 ETA_Time "Seconds since midnight; canboat type: TIME";
CM_ SG_ 2381906944 ETA_Date "canboat type: DATE";
CM_ SG_ 2381906944 Bearing__Origin_to_Destination_Waypoint "canboat type: ANGLE_UFIX16";
CM_ SG_ 2381906944 Bearing__Position_to_Destination_Waypoint "canboat type: ANGLE_UFIX16";
CM_ SG_ 2381906944 Origin_Waypoint_Number "canboat type: UINT32";
CM_ SG_ 2381906944 Destination_Waypoint_Number "canboat type: UINT32";
CM_ SG_ 2381906944 Destination_Latitude "canboat type: GEO_LAT_FIX32";
CM_ SG_ 2381906944 Destination_Longitude "canboat type: GEO_LON_FIX32";
CM_ SG_ 2381906944 Waypoint_Closing_Velocity "canboat type: SPEED_FIX16_CM";
CM_ SG_ 2583233792 Start_RPS_ "canboat type: UINT16";
CM_ SG_ 2583233792 nItems "canboat type: UINT16";
CM_ SG_ 2583233792 Database_ID "canboat type: UINT16";
CM_ SG_ 2583233792 Route_ID "canboat type: UINT16";
CM_ SG_ 2583233792 Navigation_direction_in_route "canboat type: LOOKUP";
CM_ SG_ 2583233792 Supplementary_Route_WP_data_available "canboat type: LOOKUP";
CM_ SG_ 2583233792 Route_Name "canboat type: STRING_LAU";
CM_ SG_ 2583233792 field88 "canboat type: NUMBER";
CM_ SG_ 2381908736 SID "canboat type: UINT8";
CM_ SG_ 2381908736 Set_Reference "canboat type: LOOKUP";
CM_ SG_ 2381908736 Set "canboat type: ANGLE_UFIX16";
CM_ SG_ 2381908736 Drift "canboat type: SPEED_UFIX16_CM";
CM_ SG_ 2381911296 SID "canboat type: UINT8";
CM_ SG_ 2381911296 Time_to_mark "negative = elapsed since event, positive = time to go; canboat type: DURATION_FIX32_MS";
CM_ SG_ 2381911296 Mark_Type "canboat type: LOOKUP";
CM_ SG_ 2381911296 Mark_ID "canboat type: UINT32";
CM_ SG_ 2583238144 SID "canboat type: UINT8";
CM_ SG_ 2583238144 Bearing_Reference "canboat type: LOOKUP";
CM_ SG_ 2583238144 Calculation_Type "canboat type: LOOKUP";
CM_ SG_ 2583238144 Bearing__Origin_to_Destination "canboat type: ANGLE_UFIX16";
CM_ SG_ 2583238144 Distance "canboat type: LENGTH_UFIX32_CM";
CM_ SG_ 2583238144 Origin_Mark_Type "canboat type: LOOKUP";
CM_ SG_ 2583238144 Destination_Mark_Type "canboat type: LOOKUP";
CM_ SG_ 2583238144 Origin_Mark_ID "canboat type: UINT32";
CM_ SG_ 2583238144 Destination_Mark_ID "canboat type: UINT32";
CM_ SG_ 2583298560 SV_Elevation_Mask "Will not use SV below this elevation; canboat type: ANGLE_FIX16";
CM_ SG_ 2583298560 PDOP_Mask "Will not report position above this PDOP; canboat type: DILUTION_OF_PRECISION_FIX16";
CM_ SG_ 2583298560 PDOP_Switch "Will report 2D position above this PDOP; canboat type: DILUTION_OF_PRECISION_FIX16";
CM_ SG_ 2583298560 SNR_Mask "Will not use SV below this SNR; canboat type: SIGNALTONOISERATIO_FIX16";
CM_ SG_ 2583298560 GNSS_Mode__desired_ "canboat type: LOOKUP";
CM_ SG_ 2583298560 DGNSS_Mode__desired_ "canboat type: LOOKUP";
CM_ SG_ 2583298560 Position_Velocity_Filter "canboat type: LOOKUP";
CM_ SG_ 2583298560 Max_Correction_Age "canboat type: DURATION_UFIX16_CS";
CM_ SG_ 2583298560 Antenna_Altitude_for_2D_Mode "canboat type: DISTANCE_FIX32_CM";
CM_ SG_ 2583298560 Use_Antenna_Altitude_for_2D_Mode "canboat type: LOOKUP";
CM_ SG_ 2583298816 SID "canboat type: UINT8";
CM_ SG_ 2583298816 Desired_Mode "canboat type: LOOKUP";
CM_ SG_ 2583298816 Actual_Mode "canboat type: LOOKUP";
CM_ SG_ 2583298816 HDOP "Horizontal dilution of precision; canboat type: DILUTION_OF_PRECISION_FIX16";
CM_ SG_ 2583298816 VDOP "Vertical dilution of precision; canboat type: DILUTION_OF_PRECISION_FIX16";
CM_ SG_ 2583298816 TDOP "Time dilution of precision; canboat type: DILUTION_OF_PRECISION_FIX16";
CM_ SG_ 2583299072 SID "canboat type: UINT8";
CM_ SG_ 2583299072 Range_Residual_Mode "canboat type: LOOKUP";
CM_ SG_ 2583299072 Sats_in_View "canboat type: UINT8";
CM_ SG_ 2583299072 field24 "canboat type: NUMBER";
CM_ SG_ 2583299328 PRN "canboat type: UINT8";
CM_ SG_ 2583299328 GPS_Week_number "canboat type: UINT16";
CM_ SG_ 2583299328 SV_Health_Bits "canboat type: BINARY";
CM_ SG_ 2583299328 Eccentricity "'e' in table 20-VI in ICD-GPS-200; canboat type: UNSIGNED_ALMANAC_PARAMETER_RATIO";
CM_ SG_ 2583299328 Almanac_Reference_Time "'t oa' in table 20-VI in ICD-GPS-200; canboat type: UNSIGNED_ALMANAC_PARAMETER_DURATION";
CM_ SG_ 2583299328 Inclination_Angle "'delta i' in table 20-VI in ICD-GPS-200; canboat type: SIGNED_ALMANAC_PARAMETER_SEMI_CIRCLE";
CM_ SG_ 2583299328 Rate_of_Right_Ascension "'OMEGADOT' in table 20-VI in ICD-GPS-200; canboat type: SIGNED_ALMANAC_PARAMETER_SEMI_CIRCLE_PER_S";
CM_ SG_ 2583299328 Root_of_Semi_major_Axis "'(A)^0.5' in table 20-VI in ICD-GPS-200; canboat type: UNSIGNED_ALMANAC_PARAMETER_SQRT_M";
CM_ SG_ 2583299328 Argument_of_Perigee "'(OMEGA)0' in table 20-VI in ICD-GPS-200; canboat type: SIGNED_ALMANAC_PARAMETER_SEMI_CIRCLE";
CM_ SG_ 2583299328 Longitude_of_Ascension_Node "'small-omega' in table 20-VI in ICD-GPS-200; canboat type: SIGNED_ALMANAC_PARAMETER_SEMI_CIRCLE";
CM_ SG_ 2583299328 Mean_Anomaly "'M 0' in table 20-VI in ICD-GPS-200; canboat type: SIGNED_ALMANAC_PARAMETER_SEMI_CIRCLE";
CM_ SG_ 2583299328 Clock_Parameter_1 "'a f0' in table 20-VI in ICD-GPS-200; canboat type: SIGNED_ALMANAC_PARAMETER_DURATION";
CM_ SG_ 2583299328 Clock_Parameter_2 "'a f1' in table 20-VI in ICD-GPS-200; canboat type: SIGNED_ALMANAC_PARAMETER_RATIO";
CM_ SG_ 2583299584 SID "canboat type: UINT8";
CM_ SG_ 2583299584 RMS_of_Position_Uncertainty "canboat type: LENGTH_UFIX16_CM";
CM_ SG_ 2583299584 STD_of_Major_axis "canboat type: LENGTH_UFIX16_CM";
CM_ SG_ 2583299584 STD_of_Minor_axis "canboat type: LENGTH_UFIX16_CM";
CM_ SG_ 2583299584 Orientation_of_Major_axis "canboat type: ANGLE_UFIX16";
CM_ SG_ 2583299584 STD_of_Lat_Error "canboat type: LENGTH_UFIX16_CM";
CM_ SG_ 2583299584 STD_of_Lon_Error "canboat type: LENGTH_UFIX16_CM";
CM_ SG_ 2583299584 STD_of_Alt_Error "canboat type: LENGTH_UFIX16_CM";
CM_ SG_ 2583300352 SID "canboat type: UINT8";
CM_ SG_ 2583300352 Integrity_flag "canboat type: LOOKUP";
CM_ SG_ 2583300352 Latitude_expected_error "canboat type: DISTANCE_FIX16_CM";
CM_ SG_ 2583300352 Longitude_expected_error "canboat type: DISTANCE_FIX16_CM";
CM_ SG_ 2583300352 Altitude_expected_error "canboat type: DISTANCE_FIX16_CM";
CM_ SG_ 2583300352 SV_ID_of_most_likely_failed_sat "canboat type: UINT8";
CM_ SG_ 2583300352 Probability_of_missed_detection "canboat type: DISTANCE_FIX16_CM";
CM_ SG_ 2583300352 Estimate_of_pseudorange_bias "canboat type: DISTANCE_FIX16_CM";
CM_ SG_ 2583300352 Std_Deviation_of_bias "canboat type: DISTANCE_FIX16_CM";
CM_ SG_ 2583300608 Radial_Position_Error_Maximum_Threshold "canboat type: LENGTH_UFIX16_CM";
CM_ SG_ 2583300608 Probability_of_False_Alarm "canboat type: PERCENTAGE_INT8";
CM_ SG_ 2583300608 Probability_of_Missed_Detection "canboat type: PERCENTAGE_INT8";
CM_ SG_ 2583300608 Pseudorange_Residual_Filtering_Time_Constant "canboat type: DURATION_UFIX16_S";
CM_ SG_ 2583300864 SID "canboat type: UINT8";
CM_ SG_ 2583300864 RMS_Std_Dev_of_Range_Inputs "canboat type: LENGTH_UFIX16_CM";
CM_ SG_ 2583300864 Std_Dev_of_Major_error_ellipse "canboat type: LENGTH_UFIX16_CM";
CM_ SG_ 2583300864 Std_Dev_of_Minor_error_ellipse "canboat type: LENGTH_UFIX16_CM";
CM_ SG_ 2583300864 Orientation_of_error_ellipse "canboat type: ANGLE_UFIX16";
CM_ SG_ 2583300864 Std_Dev_Lat_Error "canboat type: LENGTH_UFIX16_CM";
CM_ SG_ 2583300864 Std_Dev_Lon_Error "canboat type: LENGTH_UFIX16_CM";
CM_ SG_ 2583300864 Std_Dev_Alt_Error "canboat type: LENGTH_UFIX16_CM";
CM_ SG_ 2583301376 SID "canboat type: UINT8";
CM_ SG_ 2583301376 Reference_Station_ID "canboat type: UNSIGNED_INTEGER";
CM_ SG_ 2583301376 Reference_Station_Type "canboat type: LOOKUP";
CM_ SG_ 2583301376 Time_of_corrections "canboat type: DURATION_UFIX16_DS";
CM_ SG_ 2583301376 Station_Health "canboat type: LOOKUP";
CM_ SG_ 2583301376 Satellite_ID "canboat type: UINT8";
CM_ SG_ 2583301376 PRC "canboat type: DISTANCE_FIX32_DMM";
CM_ SG_ 2583301376 RRC "canboat type: SPEED_FIX16_DMM";
CM_ SG_ 2583301376 UDRE "canboat type: LENGTH_UFIX16_CM";
CM_ SG_ 2583301376 IOD "canboat type: UINT8";
CM_ SG_ 2583301632 Channel "canboat type: UINT8";
CM_ SG_ 2583301632 Frequency "canboat type: RADIO_FREQUENCY_UFIX32";
CM_ SG_ 2583301632 Serial_Interface_Bit_Rate "canboat type: LOOKUP";
CM_ SG_ 2583301632 Serial_Interface_Detection_Mode "canboat type: LOOKUP";
CM_ SG_ 2583301632 Differential_Source "canboat type: LOOKUP";
CM_ SG_ 2583301632 Differential_Operation_Mode "canboat type: LOOKUP";
CM_ SG_ 2583301888 SID "canboat type: UINT8";
CM_ SG_ 2583301888 Channel "canboat type: UINT8";
CM_ SG_ 2583301888 Signal_Strength "Signal strength in dB relative to 1 uV/m; canboat type: SIGNALSTRENGTH_FIX32";
CM_ SG_ 2583301888 Signal_SNR "canboat type: SIGNALTONOISERATIO_FIX16";
CM_ SG_ 2583301888 Frequency "canboat type: RADIO_FREQUENCY_UFIX32";
CM_ SG_ 2583301888 Station_Type "canboat type: LOOKUP";
CM_ SG_ 2583301888 Reference_Station_ID "canboat type: UNSIGNED_INTEGER";
CM_ SG_ 2583301888 Differential_Signal_Bit_Rate "canboat type: LOOKUP";
CM_ SG_ 2583301888 Differential_Signal_Detection_Mode "canboat type: LOOKUP";
CM_ SG_ 2583301888 Used_as_Correction_Source "canboat type: LOOKUP";
CM_ SG_ 2583301888 Differential_Source "canboat type: LOOKUP";
CM_ SG_ 2583301888 Time_since_Last_Sat_Differential_Sync "Age of differential corrections; canboat type: DURATION_UFIX16_CS";
CM_ SG_ 2583301888 Satellite_Service_ID_No_ "canboat type: UINT16";
CM_ SG_ 2583303168 PRN "Satellite ID number; canboat type: UINT8";
CM_ SG_ 2583303168 NA "Calendar day count within the four year period beginning with the previous leap year; canboat type: UINT16";
CM_ SG_ 2583303168 CnA "Generalized health of the satellite; canboat type: UNSIGNED_INTEGER";
CM_ SG_ 2583303168 HnA "Carrier frequency number; canboat type: UNSIGNED_INTEGER";
CM_ SG_ 2583303168 _epsilon_nA "Eccentricity; canboat type: UINT16";
CM_ SG_ 2583303168 _deltaTnA_DOT "Rate of change of the draconitic circling time; canboat type: UINT8";
CM_ SG_ 2583303168 _omega_nA "Rate of change of the draconitic circling time; canboat type: UINT16";
CM_ SG_ 2583303168 _delta_TnA "Correction to the average value of the draconitic circling time; canboat type: UINT24";
CM_ SG_ 2583303168 tnA "Time of the ascension node; canboat type: UINT24";
CM_ SG_ 2583303168 _lambda_nA "Greenwich longitude of the ascension node; canboat type: UINT24";
CM_ SG_ 2583303168 _delta_inA "Correction to the average value of the inclination angle; canboat type: UINT24";
CM_ SG_ 2583303168 _tau_cA "System time scale correction; canboat type: UNSIGNED_INTEGER";
CM_ SG_ 2583303168 _tau_nA "Course value of the time scale shift; canboat type: UNSIGNED_INTEGER";
CM_ SG_ 2583363584 Message_ID "canboat type: LOOKUP";
CM_ SG_ 2583363584 Repeat_Indicator "canboat type: UNSIGNED_INTEGER";
CM_ SG_ 2583363584 Source_ID "canboat type: MMSI";
CM_ SG_ 2583363584 AIS_Transceiver_information "canboat type: LOOKUP";
CM_ SG_ 2583363584 Spare "canboat type: SPARE";
CM_ SG_ 2583363584 Longitude "canboat type: GEO_LON_FIX32";
CM_ SG_ 2583363584 Latitude "canboat type: GEO_LAT_FIX32";
CM_ SG_ 2583363584 Spare_1 "canboat type: SPARE";
CM_ SG_ 2583363584 Number_of_Bits_in_Binary_Data_Field "canboat type: UINT16";
CM_ SG_ 2583363584 Binary_Data "canboat type: BINARY";
CM_ SG_ 2650472704 Message_ID "canboat type: LOOKUP";
CM_ SG_ 2650472704 Repeat_Indicator "canboat type: LOOKUP";
CM_ SG_ 2650472704 User_ID "canboat type: MMSI";
CM_ SG_ 2650472704 Longitude "canboat type: GEO_LON_FIX32";
CM_ SG_ 2650472704 Latitude "canboat type: GEO_LAT_FIX32";
CM_ SG_ 2650472704 Position_Accuracy "canboat type: LOOKUP";
CM_ SG_ 2650472704 RAIM "canboat type: LOOKUP";
CM_ SG_ 2650472704 Position_Time "Seconds since midnight; canboat type: TIME";
CM_ SG_ 2650472704 Communication_State "Information used by the TDMA slot allocation algorithm and synchronization information; canboat type: BINARY";
CM_ SG_ 2650472704 AIS_Transceiver_information "canboat type: LOOKUP";
CM_ SG_ 2650472704 Position_Date "canboat type: DATE";
CM_ SG_ 2650472704 GNSS_type "canboat type: LOOKUP";
CM_ SG_ 2650472704 Spare "canboat type: SPARE";
CM_ SG_ 2650472704 Sequence_ID "canboat type: UINT8";
CM_ SG_ 2583364096 Message_ID "canboat type: LOOKUP";
CM_ SG_ 2583364096 Repeat_Indicator "canboat type: LOOKUP";
CM_ SG_ 2583364096 User_ID "canboat type: MMSI";
CM_ SG_ 2583364096 IMO_number "canboat type: UINT32";
CM_ SG_ 2583364096 Callsign "canboat type: STRING_FIX";
CM_ SG_ 2583364096 Name "canboat type: STRING_FIX";
CM_ SG_ 2583364096 Type_of_ship "canboat type: LOOKUP";
CM_ SG_ 2583364096 Length "canboat type: LENGTH_UFIX16_DM";
CM_ SG_ 2583364096 Beam "canboat type: LENGTH_UFIX16_DM";
CM_ SG_ 2583364096 Position_reference_from_Starboard "canboat type: LENGTH_UFIX16_DM";
CM_ SG_ 2583364096 Position_reference_from_Bow "canboat type: LENGTH_UFIX16_DM";
CM_ SG_ 2583364096 ETA_Date "canboat type: DATE";
CM_ SG_ 2583364096 ETA_Time "Seconds since midnight; canboat type: TIME";
CM_ SG_ 2583364096 Draft "canboat type: LENGTH_UFIX16_CM";
CM_ SG_ 2583364096 Destination "canboat type: STRING_FIX";
CM_ SG_ 2583364096 AIS_version_indicator "canboat type: LOOKUP";
CM_ SG_ 2583364096 GNSS_type "canboat type: LOOKUP";
CM_ SG_ 2583364096 DTE "canboat type: LOOKUP";
CM_ SG_ 2583364096 AIS_Transceiver_information "canboat type: LOOKUP";
CM_ SG_ 2583364096 Sequence_ID "canboat type: UINT8";
CM_ SG_ 2516255488 Message_ID "canboat type: LOOKUP";
CM_ SG_ 2516255488 Repeat_Indicator "canboat type: LOOKUP";
CM_ SG_ 2516255488 Source_ID "canboat type: MMSI";
CM_ SG_ 2516255488 AIS_Transceiver_information "canboat type: LOOKUP";
CM_ SG_ 2516255488 Sequence_Number "canboat type: UNSIGNED_INTEGER";
CM_ SG_ 2516255488 Destination_ID "canboat type: MMSI";
CM_ SG_ 2516255488 Retransmit_flag "canboat type: LOOKUP";
CM_ SG_ 2516255488 Number_of_Bits_in_Binary_Data_Field "canboat type: UINT16";
CM_ SG_ 2516255488 Binary_Data "canboat type: BINARY";
CM_ SG_ 2650473472 Message_ID "canboat type: LOOKUP";
CM_ SG_ 2650473472 Repeat_Indicator "canboat type: LOOKUP";
CM_ SG_ 2650473472 Source_ID "canboat type: MMSI";
CM_ SG_ 2650473472 AIS_Transceiver_information "canboat type: LOOKUP";
CM_ SG_ 2650473472 Spare "canboat type: SPARE";
CM_ SG_ 2650473472 field48 "canboat type: NUMBER";
CM_ SG_ 2516256000 Message_ID "canboat type: LOOKUP";
CM_ SG_ 2516256000 Repeat_Indicator "canboat type: LOOKUP";
CM_ SG_ 2516256000 Source_ID "canboat type: MMSI";
CM_ SG_ 2516256000 AIS_Transceiver_information "canboat type: LOOKUP";
CM_ SG_ 2516256000 Spare "canboat type: SPARE";
CM_ SG_ 2516256000 Number_of_Bits_in_Binary_Data_Field "canboat type: UINT16";
CM_ SG_ 2516256000 Binary_Data "canboat type: BINARY";
CM_ SG_ 2449147392 Message_ID "canboat type: LOOKUP";
CM_ SG_ 2449147392 Repeat_Indicator "canboat type: LOOKUP";
CM_ SG_ 2449147392 User_ID "canboat type: MMSI";
CM_ SG_ 2449147392 Longitude "canboat type: GEO_LON_FIX32";
CM_ SG_ 2449147392 Latitude "canboat type: GEO_LAT_FIX32";
CM_ SG_ 2449147392 Position_Accuracy "canboat type: LOOKUP";
CM_ SG_ 2449147392 RAIM "canboat type: LOOKUP";
CM_ SG_ 2449147392 Time_Stamp "canboat type: LOOKUP";
CM_ SG_ 2449147392 COG "canboat type: ANGLE_UFIX16";
CM_ SG_ 2449147392 SOG "Originally this used the same resolution as SOG for boats (0.01 m/s), but this did not allow for speeds over 180 km/h so in some addendum this has been amended to have a resolution of 0.1 m/s; canboat type: SPEED_UFIX16_DM";
CM_ SG_ 2449147392 Communication_State "Information used by the TDMA slot allocation algorithm and synchronization information; canboat type: BINARY";
CM_ SG_ 2449147392 AIS_Transceiver_information "canboat type: LOOKUP";
CM_ SG_ 2449147392 Altitude "canboat type: DISTANCE_FIX32_CM";
CM_ SG_ 2449147392 Reserved_for_Regional_Applications "canboat type: BINARY";
CM_ SG_ 2449147392 DTE "canboat type: LOOKUP";
CM_ SG_ 2449147392 Spare "canboat type: SPARE";
CM_ SG_ 2382038784 Rx_Frequency "canboat type: RADIO_FREQUENCY_UFIX32";
CM_ SG_ 2382038784 Tx_Frequency "canboat type: RADIO_FREQUENCY_UFIX32";
CM_ SG_ 2382038784 Radio_Channel "MF/HF telephone channels to have first digit 3 followed by ITU channel numbers with leading zeros as required. MF/HF teletype channels to have first digit 4; the second and third digit give the frequency bands; and the fourth to sixth digits ITU channel numbers; each with leading zeros as required. VHF channels to have the first digit 9 followed by zero. The next digit is 1 indicating the ship stations transmit frequency is being used as a simplex channel frequency, or 2 indicating the coast stations transmit frequency is being used as a simplex channel frequency, 0 otherwise. The remaining three numbers are the VHF channel numbers with leading zeros as required.; canboat type: STRING_FIX";
CM_ SG_ 2382038784 Tx_Power "canboat type: POWER_UINT16";
CM_ SG_ 2382038784 Mode "canboat type: LOOKUP";
CM_ SG_ 2382038784 Channel_Bandwidth "canboat type: FREQUENCY_UFIX16";
CM_ SG_ 2650474496 Message_ID "canboat type: LOOKUP";
CM_ SG_ 2650474496 Repeat_Indicator "canboat type: LOOKUP";
CM_ SG_ 2650474496 Source_ID "canboat type: MMSI";
CM_ SG_ 2650474496 AIS_Transceiver_information "canboat type: LOOKUP";
CM_ SG_ 2650474496 Spare "canboat type: SPARE";
CM_ SG_ 2650474496 Destination_ID "canboat type: MMSI";
CM_ SG_ 2516257024 Message_ID "canboat type: LOOKUP";
CM_ SG_ 2516257024 Repeat_Indicator "canboat type: LOOKUP";
CM_ SG_ 2516257024 Source_ID "canboat type: MMSI";
CM_ SG_ 2516257024 AIS_Transceiver_information "canboat type: LOOKUP";
CM_ SG_ 2516257024 Sequence_Number "canboat type: UNSIGNED_INTEGER";
CM_ SG_ 2516257024 Destination_ID "canboat type: MMSI";
CM_ SG_ 2516257024 Retransmit_flag "canboat type: LOOKUP";
CM_ SG_ 2516257024 Spare "canboat type: SPARE";
CM_ SG_ 2516257024 Safety_Related_Text "canboat type: STRING_LAU";
CM_ SG_ 2516257280 Message_ID "canboat type: LOOKUP";
CM_ SG_ 2516257280 Repeat_Indicator "canboat type: LOOKUP";
CM_ SG_ 2516257280 Source_ID "canboat type: MMSI";
CM_ SG_ 2516257280 AIS_Transceiver_information "canboat type: LOOKUP";
CM_ SG_ 2516257280 Spare "canboat type: SPARE";
CM_ SG_ 2516257280 Safety_Related_Text "canboat type: STRING_LAU";
CM_ SG_ 2650475264 Message_ID "canboat type: LOOKUP";
CM_ SG_ 2650475264 Repeat_Indicator "canboat type: LOOKUP";
CM_ SG_ 2650475264 Source_ID "canboat type: MMSI";
CM_ SG_ 2650475264 AIS_Transceiver_information "canboat type: LOOKUP";
CM_ SG_ 2650475264 Spare "canboat type: SPARE";
CM_ SG_ 2650475264 Destination_ID_1 "canboat type: MMSI";
CM_ SG_ 2650475264 Message_ID_1_1 "canboat type: LOOKUP";
CM_ SG_ 2650475264 Slot_Offset_1_1 "canboat type: UINT16";
CM_ SG_ 2650475264 Spare_1 "canboat type: SPARE";
CM_ SG_ 2650475264 Message_ID_1_2 "canboat type: LOOKUP";
CM_ SG_ 2650475264 Slot_Offset_1_2 "canboat type: UINT16";
CM_ SG_ 2650475264 Destination_ID_2 "canboat type: MMSI";
CM_ SG_ 2650475264 Message_ID_2_1 "canboat type: LOOKUP";
CM_ SG_ 2650475264 Slot_Offset_2_1 "canboat type: UINT16";
CM_ SG_ 2650475264 Spare_2 "canboat type: SPARE";
CM_ SG_ 2650475264 SID "canboat type: UINT8";
CM_ SG_ 2650475520 Message_ID "canboat type: LOOKUP";
CM_ SG_ 2650475520 Repeat_Indicator "canboat type: LOOKUP";
CM_ SG_ 2650475520 Source_ID "canboat type: MMSI";
CM_ SG_ 2650475520 AIS_Transceiver_information "canboat type: LOOKUP";
CM_ SG_ 2650475520 Spare "canboat type: SPARE";
CM_ SG_ 2650475520 Destination_ID_A "canboat type: MMSI";
CM_ SG_ 2650475520 Offset_A "Offset from current slot to first assigned slot; canboat type: UINT16";
CM_ SG_ 2650475520 Increment_A "Increment to next assigned slot; canboat type: UINT16";
CM_ SG_ 2650475520 Destination_ID_B "canboat type: MMSI";
CM_ SG_ 2650475520 Offset_B "Offset from current slot to first assigned slot; canboat type: UINT16";
CM_ SG_ 2650475520 Increment_B "Increment to next assigned slot; canboat type: UINT16";
CM_ SG_ 2650475520 Spare_1 "canboat type: SPARE";
VAL_ 2582645504 Alert_Type 1 "Emergency Alarm" 2 "Alarm" 5 "Warning" 8 "Caution" ;
VAL_ 2582645504 Alert_Category 0 "Navigational" 1 "Technical" ;
VAL_ 2582645760 Alert_Type 1 "Emergency Alarm" 2 "Alarm" 5 "Warning" 8 "Caution" ;
VAL_ 2582645760 Alert_Category 0 "Navigational" 1 "Technical" ;
VAL_ 2381320192 Source 0 "GPS" 1 "GLONASS" 2 "Radio Station" 3 "Local Cesium clock" 4 "Local Rubidium clock" 5 "Local Crystal clock" ;
VAL_ 2649755904 Controller_1_State 0 "Error Active" 1 "Error Passive" 2 "Bus Off" ;
VAL_ 2649755904 Controller_2_State 0 "Error Active" 1 "Error Passive" 2 "Bus Off" ;
VAL_ 2649755904 Equipment_Status 0 "Operational" 1 "Fault" ;
VAL_ 2582647808 Certification_Level 0 "Level A" 1 "Level B" ;
VAL_ 2582708480 Man_Overboard_Status 0 "MOB Emitter Activated" 1 "Manual on-board MOB Button Activation" 2 "Test mode" 3 "MOB Not Active" ;
VAL_ 2582708480 Position_Source 0 "Position estimated by the vessel" 1 "Position reported by MOB emitter" ;
VAL_ 2582708480 COG_Reference 0 "True" 1 "Magnetic" 2 "Error" ;
VAL_ 2582708480 MOB_Emitter_Battery_Low_Status 0 "Good" 1 "Low" ;
VAL_ 2314274048 Rudder_Limit_Exceeded 0 "No" 1 "Yes" ;
VAL_ 2314274048 Off_Heading_Limit_Exceeded 0 "No" 1 "Yes" ;
VAL_ 2314274048 Off_Track_Limit_Exceeded 0 "No" 1 "Yes" ;
VAL_ 2314274048 Override 0 "No" 1 "Yes" ;
VAL_ 2314274048 Steering_Mode 0 "Main Steering" 1 "Non-Follow-Up Device" 2 "Follow-Up Device" 3 "Heading Control Standalone" 4 "Heading Control" 5 "Track Control" ;
VAL_ 2314274048 Turn_Mode 0 "Rudder limit controlled" 1 "Turn rate controlled" 2 "Radius controlled" ;
VAL_ 2314274048 Heading_Reference 0 "True" 1 "Magnetic" 2 "Error" ;
VAL_ 2314274048 Commanded_Rudder_Direction 0 "No Order" 1 "Move to starboard" 2 "Move to port" ;
VAL_ 2314276096 Direction_Order 0 "No Order" 1 "Move to starboard" 2 "Move to port" ;
VAL_ 2314277376 Reference 0 "True" 1 "Magnetic" 2 "Error" ;
VAL_ 2649823744 Source 0 "Manual" 1 "Automatic Chart" 2 "Automatic Table" 3 "Automatic Calculation" 4 "WMM 2000" 5 "WMM 2005" 6 "WMM 2010" 7 "WMM 2015" 8 "WMM 2020" 9 "WMM 2025" ;
VAL_ 2314338304 Instance 0 "Single Engine or Dual Engine Port" 1 "Dual Engine Starboard" ;
VAL_ 2314338560 Instance 0 "Single Engine or Dual Engine Port" 1 "Dual Engine Starboard" ;
VAL_ 2314339584 Instance 0 "Single Engine or Dual Engine Port" 1 "Dual Engine Starboard" ;
VAL_ 2314339584 Transmission_Gear 0 "Forward" 1 "Neutral" 2 "Reverse" ;
VAL_ 2515667200 Instance 0 "Single Engine or Dual Engine Port" 1 "Dual Engine Starboard" ;
VAL_ 2515667456 Instance 0 "Single Engine or Dual Engine Port" 1 "Dual Engine Starboard" ;
VAL_ 2381450496 Indicator1 0 "Off" 1 "On" ;
VAL_ 2381450496 Indicator2 0 "Off" 1 "On" ;
VAL_ 2381450496 Indicator3 0 "Off" 1 "On" ;
VAL_ 2381450496 Indicator4 0 "Off" 1 "On" ;
VAL_ 2381450496 Indicator5 0 "Off" 1 "On" ;
VAL_ 2381450496 Indicator6 0 "Off" 1 "On" ;
VAL_ 2381450496 Indicator7 0 "Off" 1 "On" ;
VAL_ 2381450496 Indicator8 0 "Off" 1 "On" ;
VAL_ 2381450496 Indicator9 0 "Off" 1 "On" ;
VAL_ 2381450496 Indicator10 0 "Off" 1 "On" ;
VAL_ 2381450496 Indicator11 0 "Off" 1 "On" ;
VAL_ 2381450496 Indicator12 0 "Off" 1 "On" ;
VAL_ 2381450496 Indicator13 0 "Off" 1 "On" ;
VAL_ 2381450496 Indicator14 0 "Off" 1 "On" ;
VAL_ 2381450496 Indicator15 0 "Off" 1 "On" ;
VAL_ 2381450496 Indicator16 0 "Off" 1 "On" ;
VAL_ 2381450496 Indicator17 0 "Off" 1 "On" ;
VAL_ 2381450496 Indicator18 0 "Off" 1 "On" ;
VAL_ 2381450496 Indicator19 0 "Off" 1 "On" ;
VAL_ 2381450496 Indicator20 0 "Off" 1 "On" ;
VAL_ 2381450496 Indicator21 0 "Off" 1 "On" ;
VAL_ 2381450496 Indicator22 0 "Off" 1 "On" ;
VAL_ 2381450496 Indicator23 0 "Off" 1 "On" ;
VAL_ 2381450496 Indicator24 0 "Off" 1 "On" ;
VAL_ 2381450496 Indicator25 0 "Off" 1 "On" ;
VAL_ 2381450496 Indicator26 0 "Off" 1 "On" ;
VAL_ 2381450496 Indicator27 0 "Off" 1 "On" ;
VAL_ 2381450496 Indicator28 0 "Off" 1 "On" ;
VAL_ 2381450752 Switch1 0 "Off" 1 "On" 2 "Reserved" 3 "Take no action (no change)" ;
VAL_ 2381450752 Switch2 0 "Off" 1 "On" 2 "Reserved" 3 "Take no action (no change)" ;
VAL_ 2381450752 Switch3 0 "Off" 1 "On" 2 "Reserved" 3 "Take no action (no change)" ;
VAL_ 2381450752 Switch4 0 "Off" 1 "On" 2 "Reserved" 3 "Take no action (no change)" ;
VAL_ 2381450752 Switch5 0 "Off" 1 "On" 2 "Reserved" 3 "Take no action (no change)" ;
VAL_ 2381450752 Switch6 0 "Off" 1 "On" 2 "Reserved" 3 "Take no action (no change)" ;
VAL_ 2381450752 Switch7 0 "Off" 1 "On" 2 "Reserved" 3 "Take no action (no change)" ;
VAL_ 2381450752 Switch8 0 "Off" 1 "On" 2 "Reserved" 3 "Take no action (no change)" ;
VAL_ 2381450752 Switch9 0 "Off" 1 "On" 2 "Reserved" 3 "Take no action (no change)" ;
VAL_ 2381450752 Switch10 0 "Off" 1 "On" 2 "Reserved" 3 "Take no action (no change)" ;
VAL_ 2381450752 Switch11 0 "Off" 1 "On" 2 "Reserved" 3 "Take no action (no change)" ;
VAL_ 2381450752 Switch12 0 "Off" 1 "On" 2 "Reserved" 3 "Take no action (no change)" ;
VAL_ 2381450752 Switch13 0 "Off" 1 "On" 2 "Reserved" 3 "Take no action (no change)" ;
VAL_ 2381450752 Switch14 0 "Off" 1 "On" 2 "Reserved" 3 "Take no action (no change)" ;
VAL_ 2381450752 Switch15 0 "Off" 1 "On" 2 "Reserved" 3 "Take no action (no change)" ;
VAL_ 2381450752 Switch16 0 "Off" 1 "On" 2 "Reserved" 3 "Take no action (no change)" ;
VAL_ 2381450752 Switch17 0 "Off" 1 "On" 2 "Reserved" 3 "Take no action (no change)" ;
VAL_ 2381450752 Switch18 0 "Off" 1 "On" 2 "Reserved" 3 "Take no action (no change)" ;
VAL_ 2381450752 Switch19 0 "Off" 1 "On" 2 "Reserved" 3 "Take no action (no change)" ;
VAL_ 2381450752 Switch20 0 "Off" 1 "On" 2 "Reserved" 3 "Take no action (no change)" ;
VAL_ 2381450752 Switch21 0 "Off" 1 "On" 2 "Reserved" 3 "Take no action (no change)" ;
VAL_ 2381450752 Switch22 0 "Off" 1 "On" 2 "Reserved" 3 "Take no action (no change)" ;
VAL_ 2381450752 Switch23 0 "Off" 1 "On" 2 "Reserved" 3 "Take no action (no change)" ;
VAL_ 2381450752 Switch24 0 "Off" 1 "On" 2 "Reserved" 3 "Take no action (no change)" ;
VAL_ 2381450752 Switch25 0 "Off" 1 "On" 2 "Reserved" 3 "Take no action (no change)" ;
VAL_ 2381450752 Switch26 0 "Off" 1 "On" 2 "Reserved" 3 "Take no action (no change)" ;
VAL_ 2381450752 Switch27 0 "Off" 1 "On" 2 "Reserved" 3 "Take no action (no change)" ;
VAL_ 2381450752 Switch28 0 "Off" 1 "On" 2 "Reserved" 3 "Take no action (no change)" ;
VAL_ 2582778112 Type 0 "Fuel" 1 "Water" 2 "Gray water" 3 "Live well" 4 "Oil" 5 "Black water" ;
VAL_ 2582778368 DC_Type 0 "Battery" 1 "Alternator" 2 "Convertor" 3 "Solar cell" 4 "Wind generator" ;
VAL_ 2582778624 Operating_State 0 "Not charging" 1 "Bulk" 2 "Absorption" 3 "Overcharge" 4 "Equalise" 5 "Float" 6 "No float" 7 "Constant VI" 8 "Disabled" 9 "Fault" ;
VAL_ 2582778624 Charge_Mode 0 "Standalone" 1 "Primary" 2 "Secondary" 3 "Echo" ;
VAL_ 2582778624 Enabled 0 "Off" 1 "On" ;
VAL_ 2582778624 Equalization_Pending 0 "Off" 1 "On" ;
VAL_ 2582779136 Operating_State 0 "Invert" 1 "AC passthru" 2 "Load sense" 3 "Fault" 4 "Disabled" ;
VAL_ 2582779136 Inverter_Enable 0 "Off" 1 "On" ;
VAL_ 2582779392 Charger_Enable_Disable 0 "Off" 1 "On" ;
VAL_ 2582779392 Charging_Algorithm 0 "Trickle" 1 "Constant voltage / Constant current" 2 "2 stage (no float)" 3 "3 stage" ;
VAL_ 2582779392 Charger_Mode 0 "Standalone" 1 "Primary" 2 "Secondary" 3 "Echo" ;
VAL_ 2582779392 Estimated_Temperature 0 "Cold" 1 "Warm" 2 "Hot" ;
VAL_ 2582779392 Equalize_One_Time_Enable_Disable 0 "Off" 1 "On" ;
VAL_ 2582779392 Over_Charge_Enable_Disable 0 "Off" 1 "On" ;
VAL_ 2582779648 Inverter_Enable_Disable 0 "Off" 1 "On" ;
VAL_ 2582779648 Inverter_Mode 0 "Standalone" 1 "Series Master" 2 "Series Slave" 3 "Parallel Master" 4 "Parallel Slave" ;
VAL_ 2582779648 Load_Sense_Enable_Disable 0 "Off" 1 "On" ;
VAL_ 2582779904 AGS_Mode 0 "Off" 1 "On" 2 "Automatic" ;
VAL_ 2582780160 Battery_Type 0 "Flooded" 1 "Gel" 2 "AGM" ;
VAL_ 2582780160 Supports_Equalization 0 "No" 1 "Yes" ;
VAL_ 2582780160 Nominal_Voltage 0 "6V" 1 "12V" 2 "24V" 3 "32V" 4 "36V" 5 "42V" 6 "48V" ;
VAL_ 2582780160 Chemistry 0 "Pb (Lead)" 1 "Li" 2 "NiCd" 3 "ZnO" 4 "NiMH" ;
VAL_ 2582780416 AGS_Operating_State 0 "Quiet time" 1 "Auto on" 2 "Auto off" 3 "Manual On" 4 "Manual Off" 5 "Generator shutdown" 6 "External shutdown" 7 "Fault" 8 "Suspend" 9 "Not operating" ;
VAL_ 2582780416 Generator_State 0 "Preheating" 1 "Start delay" 2 "Cranking" 3 "Starter cooling" 4 "Warming up" 5 "Cooling down" 6 "Spinning up" 7 "Shutdown bypass" 8 "Stopping" 9 "Running" 10 "Stopped" 11 "Crank delaty" ;
VAL_ 2582780416 Generator_On_Reason 0 "Not on" 1 "DC voltage low" 2 "Battery state of charge low" 3 "AC current high" 4 "Contact closed" 5 "Manual on" 6 "Exercise" 7 "Non Quiet time" 8 "External on via AGS" 9 "External on via generator" 10 "Unable to stop" ;
VAL_ 2582780416 Generator_Off_Reason 0 "Not off" 1 "DC voltage high" 2 "Battery state of charge high" 3 "AC current low" 4 "Contact opened" 5 "Reached absorption" 6 "Reached float" 7 "Manual off" 8 "Max run time" 9 "Max auto cycle" 10 "Exercise done" 11 "Quiet time" 12 "External off via AGS" 13 "Safe mode" 14 "External off via generator" 15 "External shutdown" 16 "Auto off" 17 "Fault" 18 "Unable to start" ;
VAL_ 2582840832 Operating_State 0 "Off" 1 "Low Power Mode" 2 "Fault" 3 "Bulk" 4 "Absorption" 5 "Float" 6 "Storage" 7 "Equalize" 8 "Pass thru" 9 "Inverting" 10 "Assisting" ;
VAL_ 2582840832 Temperature_State 0 "Good" 1 "Warning" 2 "Error" ;
VAL_ 2582840832 Overload_State 0 "Good" 1 "Warning" 2 "Error" ;
VAL_ 2582840832 Low_DC_Voltage_State 0 "Good" 1 "Warning" 2 "Error" ;
VAL_ 2582840832 Ripple_State 0 "Good" 1 "Warning" 2 "Error" ;
VAL_ 2582906368 Direction_Control 0 "Off" 1 "Ready" 2 "To Port" 3 "To Starboard" ;
VAL_ 2582906368 Power_Enabled 0 "Off" 1 "On" ;
VAL_ 2582906368 Retract_Control 0 "Off" 1 "Extend" 2 "Retract" ;
VAL_ 2582906624 Motor_Type 0 "12VDC" 1 "24VDC" 2 "48VDC" 3 "24VAC" 4 "Hydraulic" ;
VAL_ 2314535680 Speed_Water_Referenced_Type 0 "Paddle wheel" 1 "Pitot tube" 2 "Doppler" 3 "Correlation (ultra sound)" 4 "Electro Magnetic" ;
VAL_ 2314602496 Track_Status 0 "Cancelled" 1 "Acquiring" 2 "Tracking" 3 "Lost" ;
VAL_ 2314602496 Reported_Target 0 "No" 1 "Yes" ;
VAL_ 2314602496 Target_Acquisition 0 "Manual" 1 "Automatic" ;
VAL_ 2314602496 Bearing_Reference 0 "True" 1 "Magnetic" 2 "Error" ;
VAL_ 2314602496 Reference_Target 0 "No" 1 "Yes" ;
VAL_ 2583103488 Windlass_Direction_Control 0 "Off" 1 "Down" 2 "Up" ;
VAL_ 2583103488 Anchor_Docking_Control 0 "Off" 1 "On" ;
VAL_ 2583103488 Speed_Control_Type 0 "Single speed" 1 "Dual speed" 2 "Proportional speed" ;
VAL_ 2583103488 Power_Enable 0 "Off" 1 "On" ;
VAL_ 2583103488 Mechanical_Lock 0 "Off" 1 "On" ;
VAL_ 2583103488 Deck_and_Anchor_Wash 0 "Off" 1 "On" ;
VAL_ 2583103488 Anchor_Light 0 "Off" 1 "On" ;
VAL_ 2583103744 Windlass_Direction_Control 0 "Off" 1 "Down" 2 "Up" ;
VAL_ 2583103744 Windlass_Motion_Status 0 "Windlass stopped" 1 "Deployment occurring" 2 "Retrieval occurring" ;
VAL_ 2583103744 Rode_Type_Status 0 "Chain presently detected" 1 "Rope presently detected" ;
VAL_ 2583103744 Anchor_Docking_Status 0 "Not docked" 1 "Fully docked" ;
VAL_ 2314732032 COG_Reference 0 "True" 1 "Magnetic" 2 "Error" ;
VAL_ 2314732544 GNSS_Quality 0 "no GNSS" 1 "GNSS fix" 2 "DGNSS fix" 3 "Precise GNSS" 4 "RTK Fixed Integer" 5 "RTK float" 6 "Estimated (DR) mode" 7 "Manual Input" 8 "Simulate mode" ;
VAL_ 2314732544 Direction 0 "True" 1 "Magnetic" 2 "Error" ;
VAL_ 2381841664 GNSS_type 0 "GPS" 1 "GLONASS" 2 "GPS+GLONASS" 3 "GPS+SBAS/WAAS" 4 "GPS+SBAS/WAAS+GLONASS" 5 "Chayka" 6 "integrated" 7 "surveyed" 8 "Galileo" ;
VAL_ 2381841664 Method 0 "no GNSS" 1 "GNSS fix" 2 "DGNSS fix" 3 "Precise GNSS" 4 "RTK Fixed Integer" 5 "RTK float" 6 "Estimated (DR) mode" 7 "Manual Input" 8 "Simulate mode" ;
VAL_ 2381841664 Integrity 0 "No integrity checking" 1 "Safe" 2 "Caution" 3 "Unsafe" ;
VAL_ 2448952832 Message_ID 1 "Scheduled Class A position report" 2 "Assigned scheduled Class A position report" 3 "Interrogated Class A position report" 4 "Base station report" 5 "Static and voyage related data" 6 "Binary addressed message" 7 "Binary acknowledgement" 8 "Binary broadcast message" 9 "Standard SAR aircraft position report" 10 "UTC/date inquiry" 11 "UTC/date response" 12 "Safety related addressed message" 13 "Safety related acknowledgement" 14 "Satety related broadcast message" 15 "Interrogation" 16 "Assignment mode command" 17 "DGNSS broadcast binary message" 18 "Standard Class B position report" 19 "Extended Class B position report" 20 "Data link management message" 21 "ATON report" 22 "Channel management" 23 "Group assignment command" 24 "Static data report" 25 "Single slot binary message" 26 "Multiple slot binary message" 27 "Position report for long range applications" ;
VAL_ 2448952832 Repeat_Indicator 0 "Initial" 1 "First retransmission" 2 "Second retransmission" 3 "Final retransmission" ;
VAL_ 2448952832 Position_Accuracy 0 "Low" 1 "High" ;
VAL_ 2448952832 RAIM 0 "not in use" 1 "in use" ;
VAL_ 2448952832 Time_Stamp 60 "Not available" 61 "Manual input mode" 62 "Dead reckoning mode" 63 "Positioning system is inoperative" ;
VAL_ 2448952832 AIS_Transceiver_information 0 "Channel A VDL reception" 1 "Channel B VDL reception" 2 "Channel A VDL transmission" 3 "Channel B VDL transmission" 4 "Own information not broadcast" 5 "Reserved" ;
VAL_ 2448952832 Nav_Status 0 "Under way using engine" 1 "At anchor" 2 "Not under command" 3 "Restricted maneuverability" 4 "Constrained by her draught" 5 "Moored" 6 "Aground" 7 "Engaged in Fishing" 8 "Under way sailing" 9 "Hazardous material - High Speed" 10 "Hazardous material - Wing in Ground" 11 "Power-driven vessel towing astern" 12 "Power-driven vessel pushing ahead or towing alongside" 14 "AIS-SART" ;
VAL_ 2448952832 Special_Maneuver_Indicator 0 "Not available" 1 "Not engaged in special maneuver" 2 "Engaged in special maneuver" 3 "Reserved" ;
VAL_ 2448953088 Message_ID 1 "Scheduled Class A position report" 2 "Assigned scheduled Class A position report" 3 "Interrogated Class A position report" 4 "Base station report" 5 "Static and voyage related data" 6 "Binary addressed message" 7 "Binary acknowledgement" 8 "Binary broadcast message" 9 "Standard SAR aircraft position report" 10 "UTC/date inquiry" 11 "UTC/date response" 12 "Safety related addressed message" 13 "Safety related acknowledgement" 14 "Satety related broadcast message" 15 "Interrogation" 16 "Assignment mode command" 17 "DGNSS broadcast binary message" 18 "Standard Class B position report" 19 "Extended Class B position report" 20 "Data link management message" 21 "ATON report" 22 "Channel management" 23 "Group assignment command" 24 "Static data report" 25 "Single slot binary message" 26 "Multiple slot binary message" 27 "Position report for long range applications" ;
VAL_ 2448953088 Repeat_Indicator 0 "Initial" 1 "First retransmission" 2 "Second retransmission" 3 "Final retransmission" ;
VAL_ 2448953088 Position_Accuracy 0 "Low" 1 "High" ;
VAL_ 2448953088 RAIM 0 "not in use" 1 "in use" ;
VAL_ 2448953088 Time_Stamp 60 "Not available" 61 "Manual input mode" 62 "Dead reckoning mode" 63 "Positioning system is inoperative" ;
VAL_ 2448953088 AIS_Transceiver_information 0 "Channel A VDL reception" 1 "Channel B VDL reception" 2 "Channel A VDL transmission" 3 "Channel B VDL transmission" 4 "Own information not broadcast" 5 "Reserved" ;
VAL_ 2448953088 Unit_type 0 "SOTDMA" 1 "CS" ;
VAL_ 2448953088 Integrated_Display 0 "No" 1 "Yes" ;
VAL_ 2448953088 DSC 0 "No" 1 "Yes" ;
VAL_ 2448953088 Band 0 "Top 525 kHz of marine band" 1 "Entire marine band" ;
VAL_ 2448953088 Can_handle_Msg_22 0 "No" 1 "Yes" ;
VAL_ 2448953088 AIS_mode 0 "Autonomous" 1 "Assigned" ;
VAL_ 2448953088 AIS_communication_state 0 "SOTDMA" 1 "ITDMA" ;
VAL_ 2448953344 Message_ID 1 "Scheduled Class A position report" 2 "Assigned scheduled Class A position report" 3 "Interrogated Class A position report" 4 "Base station report" 5 "Static and voyage related data" 6 "Binary addressed message" 7 "Binary acknowledgement" 8 "Binary broadcast message" 9 "Standard SAR aircraft position report" 10 "UTC/date inquiry" 11 "UTC/date response" 12 "Safety related addressed message" 13 "Safety related acknowledgement" 14 "Satety related broadcast message" 15 "Interrogation" 16 "Assignment mode command" 17 "DGNSS broadcast binary message" 18 "Standard Class B position report" 19 "Extended Class B position report" 20 "Data link management message" 21 "ATON report" 22 "Channel management" 23 "Group assignment command" 24 "Static data report" 25 "Single slot binary message" 26 "Multiple slot binary message" 27 "Position report for long range applications" ;
VAL_ 2448953344 Repeat_Indicator 0 "Initial" 1 "First retransmission" 2 "Second retransmission" 3 "Final retransmission" ;
VAL_ 2448953344 Position_Accuracy 0 "Low" 1 "High" ;
VAL_ 2448953344 RAIM 0 "not in use" 1 "in use" ;
VAL_ 2448953344 Time_Stamp 60 "Not available" 61 "Manual input mode" 62 "Dead reckoning mode" 63 "Positioning system is inoperative" ;
VAL_ 2448953344 Type_of_ship 0 "Unavailable" 20 "Wing In Ground" 21 "Wing In Ground (hazard cat X)" 22 "Wing In Ground (hazard cat Y)" 23 "Wing In Ground (hazard cat Z)" 24 "Wing In Ground (hazard cat OS)" 29 "Wing In Ground (no additional information)" 30 "Fishing" 31 "Towing" 32 "Towing exceeds 200m or wider than 25m" 33 "Engaged in dredging or underwater operations" 34 "Engaged in diving operations" 35 "Engaged in military operations" 36 "Sailing" 37 "Pleasure" 40 "High speed craft" 41 "High speed craft (hazard cat X)" 42 "High speed craft (hazard cat Y)" 43 "High speed craft (hazard cat Z)" 44 "High speed craft (hazard cat OS)" 49 "High speed craft (no additional information)" 50 "Pilot vessel" 51 "SAR" 52 "Tug" 53 "Port tender" 54 "Anti-pollution" 55 "Law enforcement" 56 "Spare" 57 "Spare #2" 58 "Medical" 59 "Ships and aircraft of States not parties to an armed conflict" 60 "Passenger ship" 61 "Passenger ship (hazard cat X)" 62 "Passenger ship (hazard cat Y)" 63 "Passenger ship (hazard cat Z)" 64 "Passenger ship (hazard cat OS)" 69 "Passenger ship (no additional information)" 70 "Cargo ship" 71 "Cargo ship (hazard cat X)" 72 "Cargo ship (hazard cat Y)" 73 "Cargo ship (hazard cat Z)" 74 "Cargo ship (hazard cat OS)" 79 "Cargo ship (no additional information)" 80 "Tanker" 81 "Tanker (hazard cat X)" 82 "Tanker (hazard cat Y)" 83 "Tanker (hazard cat Z)" 84 "Tanker (hazard cat OS)" 89 "Tanker (no additional information)" 90 "Other" 91 "Other (hazard cat X)" 92 "Other (hazard cat Y)" 93 "Other (hazard cat Z)" 94 "Other (hazard cat OS)" 99 "Other (no additional information)" ;
VAL_ 2448953344 GNSS_type 0 "Default: undefined" 1 "GPS" 2 "GLONASS" 3 "Combined GPS/GLONASS" 4 "Loran-C" 5 "Chayka" 6 "Integrated navigation system" 7 "Surveyed" 8 "Galileo" ;
VAL_ 2448953344 DTE 0 "Available" 1 "Not available" ;
VAL_ 2448953344 AIS_mode 0 "Autonomous" 1 "Assigned" ;
VAL_ 2448953344 AIS_Transceiver_information 0 "Channel A VDL reception" 1 "Channel B VDL reception" 2 "Channel A VDL transmission" 3 "Channel B VDL transmission" 4 "Own information not broadcast" 5 "Reserved" ;
VAL_ 2448953600 Message_ID 1 "Scheduled Class A position report" 2 "Assigned scheduled Class A position report" 3 "Interrogated Class A position report" 4 "Base station report" 5 "Static and voyage related data" 6 "Binary addressed message" 7 "Binary acknowledgement" 8 "Binary broadcast message" 9 "Standard SAR aircraft position report" 10 "UTC/date inquiry" 11 "UTC/date response" 12 "Safety related addressed message" 13 "Safety related acknowledgement" 14 "Satety related broadcast message" 15 "Interrogation" 16 "Assignment mode command" 17 "DGNSS broadcast binary message" 18 "Standard Class B position report" 19 "Extended Class B position report" 20 "Data link management message" 21 "ATON report" 22 "Channel management" 23 "Group assignment command" 24 "Static data report" 25 "Single slot binary message" 26 "Multiple slot binary message" 27 "Position report for long range applications" ;
VAL_ 2448953600 Repeat_Indicator 0 "Initial" 1 "First retransmission" 2 "Second retransmission" 3 "Final retransmission" ;
VAL_ 2448953600 Position_Accuracy 0 "Low" 1 "High" ;
VAL_ 2448953600 RAIM 0 "not in use" 1 "in use" ;
VAL_ 2448953600 Time_Stamp 60 "Not available" 61 "Manual input mode" 62 "Dead reckoning mode" 63 "Positioning system is inoperative" ;
VAL_ 2448953600 AtoN_Type 0 "Default: Type of AtoN not specified" 1 "Reference point" 2 "RACON" 3 "Fixed structure off-shore" 4 "Reserved for future use" 5 "Fixed light: without sectors" 6 "Fixed light: with sectors" 7 "Fixed leading light front" 8 "Fixed leading light rear" 9 "Fixed beacon: cardinal N" 10 "Fixed beacon: cardinal E" 11 "Fixed beacon: cardinal S" 12 "Fixed beacon: cardinal W" 13 "Fixed beacon: port hand" 14 "Fixed beacon: starboard hand" 15 "Fixed beacon: preferred channel port hand" 16 "Fixed beacon: preferred channel starboard hand" 17 "Fixed beacon: isolated danger" 18 "Fixed beacon: safe water" 19 "Fixed beacon: special mark" 20 "Floating AtoN: cardinal N" 21 "Floating AtoN: cardinal E" 22 "Floating AtoN: cardinal S" 23 "Floating AtoN: cardinal W" 24 "Floating AtoN: port hand mark" 25 "Floating AtoN: starboard hand mark" 26 "Floating AtoN: preferred channel port hand" 27 "Floating AtoN: preferred channel starboard hand" 28 "Floating AtoN: isolated danger" 29 "Floating AtoN: safe water" 30 "Floating AtoN: special mark" 31 "Floating AtoN: light vessel/LANBY/rigs" ;
VAL_ 2448953600 Off_Position_Indicator 0 "No" 1 "Yes" ;
VAL_ 2448953600 Virtual_AtoN_Flag 0 "No" 1 "Yes" ;
VAL_ 2448953600 Assigned_Mode_Flag 0 "Autonomous and continuous" 1 "Assigned mode" ;
VAL_ 2448953600 Position_Fixing_Device_Type 0 "Default: undefined" 1 "GPS" 2 "GLONASS" 3 "Combined GPS/GLONASS" 4 "Loran-C" 5 "Chayka" 6 "Integrated navigation system" 7 "Surveyed" 8 "Galileo" ;
VAL_ 2448953600 AIS_Transceiver_information 0 "Channel A VDL reception" 1 "Channel B VDL reception" 2 "Channel A VDL transmission" 3 "Channel B VDL transmission" 4 "Own information not broadcast" 5 "Reserved" ;
VAL_ 2381906688 XTE_mode 0 "Autonomous" 1 "Differential enhanced" 2 "Estimated" 3 "Simulator" 4 "Manual" ;
VAL_ 2381906688 Navigation_Terminated 0 "No" 1 "Yes" ;
VAL_ 2381906944 Course_Bearing_reference 0 "True" 1 "Magnetic" 2 "Error" ;
VAL_ 2381906944 Perpendicular_Crossed 0 "No" 1 "Yes" ;
VAL_ 2381906944 Arrival_Circle_Entered 0 "No" 1 "Yes" ;
VAL_ 2381906944 Calculation_Type 0 "Great Circle" 1 "Rhumbline" ;
VAL_ 2583233792 Navigation_direction_in_route 0 "Forward" 1 "Reverse" ;
VAL_ 2583233792 Supplementary_Route_WP_data_available 0 "Off" 1 "On" ;
VAL_ 2381908736 Set_Reference 0 "True" 1 "Magnetic" 2 "Error" ;
VAL_ 2381911296 Mark_Type 0 "Collision" 1 "Turning point" 2 "Reference" 3 "Wheelover" 4 "Waypoint" ;
VAL_ 2583238144 Bearing_Reference 0 "True" 1 "Magnetic" 2 "Error" ;
VAL_ 2583238144 Calculation_Type 0 "Great Circle" 1 "Rhumbline" ;
VAL_ 2583238144 Origin_Mark_Type 0 "Collision" 1 "Turning point" 2 "Reference" 3 "Wheelover" 4 "Waypoint" ;
VAL_ 2583238144 Destination_Mark_Type 0 "Collision" 1 "Turning point" 2 "Reference" 3 "Wheelover" 4 "Waypoint" ;
VAL_ 2583298560 GNSS_Mode__desired_ 0 "1D" 1 "2D" 2 "3D" 3 "Auto" ;
VAL_ 2583298560 DGNSS_Mode__desired_ 0 "None" 1 "SBAS if available" 3 "SBAS" ;
VAL_ 2583298560 Position_Velocity_Filter 0 "No" 1 "Yes" ;
VAL_ 2583298560 Use_Antenna_Altitude_for_2D_Mode 0 "No" 1 "Yes" ;
VAL_ 2583298816 Desired_Mode 0 "1D" 1 "2D" 2 "3D" 3 "Auto" ;
VAL_ 2583298816 Actual_Mode 0 "1D" 1 "2D" 2 "3D" 3 "Auto" ;
VAL_ 2583299072 Range_Residual_Mode 0 "Range residuals were used to calculate data" 1 "Range residuals were calculated after the position" ;
VAL_ 2583300352 Integrity_flag 0 "No integrity checking" 1 "Safe" 2 "Caution" 3 "Unsafe" ;
VAL_ 2583301376 Reference_Station_Type 0 "GPS" 1 "GLONASS" 2 "GPS+GLONASS" 3 "GPS+SBAS/WAAS" 4 "GPS+SBAS/WAAS+GLONASS" 5 "Chayka" 6 "integrated" 7 "surveyed" 8 "Galileo" ;
VAL_ 2583301376 Station_Health 0 "Not Working" 1 "Unmonitored" 2 "Healthy Operational" 3 "Healthy Test Mode" 4 "Test Mode" ;
VAL_ 2583301632 Serial_Interface_Bit_Rate 0 "25" 1 "50" 2 "100" 3 "200" 4 "300" 5 "600" 6 "1200" 7 "2400" 8 "4800" 9 "9600" 10 "19200" 11 "38400" 12 "57600" ;
VAL_ 2583301632 Serial_Interface_Detection_Mode 0 "Auto bit rate" 1 "Manual bit rate" ;
VAL_ 2583301632 Differential_Source 0 "Auto" 1 "Loran" 2 "MSK Beacon" 3 "FM Subcarrier" 4 "AIS" 5 "Ground based radio" 6 "SBAS" 7 "Satellite" ;
VAL_ 2583301632 Differential_Operation_Mode 0 "Manual" 1 "Auto Power" 2 "Auto Range" ;
VAL_ 2583301888 Station_Type 0 "GPS" 1 "GLONASS" 2 "GPS+GLONASS" 3 "GPS+SBAS/WAAS" 4 "GPS+SBAS/WAAS+GLONASS" 5 "Chayka" 6 "integrated" 7 "surveyed" 8 "Galileo" ;
VAL_ 2583301888 Differential_Signal_Bit_Rate 0 "25" 1 "50" 2 "100" 3 "200" 4 "300" 5 "600" 6 "1200" 7 "2400" 8 "4800" 9 "9600" 10 "19200" 11 "38400" 12 "57600" ;
VAL_ 2583301888 Differential_Signal_Detection_Mode 0 "Auto bit rate" 1 "Manual bit rate" ;
VAL_ 2583301888 Used_as_Correction_Source 0 "No" 1 "Yes" ;
VAL_ 2583301888 Differential_Source 0 "Auto" 1 "Loran" 2 "MSK Beacon" 3 "FM Subcarrier" 4 "AIS" 5 "Ground based radio" 6 "SBAS" 7 "Satellite" ;
VAL_ 2583363584 Message_ID 1 "Scheduled Class A position report" 2 "Assigned scheduled Class A position report" 3 "Interrogated Class A position report" 4 "Base station report" 5 "Static and voyage related data" 6 "Binary addressed message" 7 "Binary acknowledgement" 8 "Binary broadcast message" 9 "Standard SAR aircraft position report" 10 "UTC/date inquiry" 11 "UTC/date response" 12 "Safety related addressed message" 13 "Safety related acknowledgement" 14 "Satety related broadcast message" 15 "Interrogation" 16 "Assignment mode command" 17 "DGNSS broadcast binary message" 18 "Standard Class B position report" 19 "Extended Class B position report" 20 "Data link management message" 21 "ATON report" 22 "Channel management" 23 "Group assignment command" 24 "Static data report" 25 "Single slot binary message" 26 "Multiple slot binary message" 27 "Position report for long range applications" ;
VAL_ 2583363584 AIS_Transceiver_information 0 "Channel A VDL reception" 1 "Channel B VDL reception" 2 "Channel A VDL transmission" 3 "Channel B VDL transmission" 4 "Own information not broadcast" 5 "Reserved" ;
VAL_ 2650472704 Message_ID 1 "Scheduled Class A position report" 2 "Assigned scheduled Class A position report" 3 "Interrogated Class A position report" 4 "Base station report" 5 "Static and voyage related data" 6 "Binary addressed message" 7 "Binary acknowledgement" 8 "Binary broadcast message" 9 "Standard SAR aircraft position report" 10 "UTC/date inquiry" 11 "UTC/date response" 12 "Safety related addressed message" 13 "Safety related acknowledgement" 14 "Satety related broadcast message" 15 "Interrogation" 16 "Assignment mode command" 17 "DGNSS broadcast binary message" 18 "Standard Class B position report" 19 "Extended Class B position report" 20 "Data link management message" 21 "ATON report" 22 "Channel management" 23 "Group assignment command" 24 "Static data report" 25 "Single slot binary message" 26 "Multiple slot binary message" 27 "Position report for long range applications" ;
VAL_ 2650472704 Repeat_Indicator 0 "Initial" 1 "First retransmission" 2 "Second retransmission" 3 "Final retransmission" ;
VAL_ 2650472704 Position_Accuracy 0 "Low" 1 "High" ;
VAL_ 2650472704 RAIM 0 "not in use" 1 "in use" ;
VAL_ 2650472704 AIS_Transceiver_information 0 "Channel A VDL reception" 1 "Channel B VDL reception" 2 "Channel A VDL transmission" 3 "Channel B VDL transmission" 4 "Own information not broadcast" 5 "Reserved" ;
VAL_ 2650472704 GNSS_type 0 "Default: undefined" 1 "GPS" 2 "GLONASS" 3 "Combined GPS/GLONASS" 4 "Loran-C" 5 "Chayka" 6 "Integrated navigation system" 7 "Surveyed" 8 "Galileo" ;
VAL_ 2583364096 Message_ID 1 "Scheduled Class A position report" 2 "Assigned scheduled Class A position report" 3 "Interrogated Class A position report" 4 "Base station report" 5 "Static and voyage related data" 6 "Binary addressed message" 7 "Binary acknowledgement" 8 "Binary broadcast message" 9 "Standard SAR aircraft position report" 10 "UTC/date inquiry" 11 "UTC/date response" 12 "Safety related addressed message" 13 "Safety related acknowledgement" 14 "Satety related broadcast message" 15 "Interrogation" 16 "Assignment mode command" 17 "DGNSS broadcast binary message" 18 "Standard Class B position report" 19 "Extended Class B position report" 20 "Data link management message" 21 "ATON report" 22 "Channel management" 23 "Group assignment command" 24 "Static data report" 25 "Single slot binary message" 26 "Multiple slot binary message" 27 "Position report for long range applications" ;
VAL_ 2583364096 Repeat_Indicator 0 "Initial" 1 "First retransmission" 2 "Second retransmission" 3 "Final retransmission" ;
VAL_ 2583364096 Type_of_ship 0 "Unavailable" 20 "Wing In Ground" 21 "Wing In Ground (hazard cat X)" 22 "Wing In Ground (hazard cat Y)" 23 "Wing In Ground (hazard cat Z)" 24 "Wing In Ground (hazard cat OS)" 29 "Wing In Ground (no additional information)" 30 "Fishing" 31 "Towing" 32 "Towing exceeds 200m or wider than 25m" 33 "Engaged in dredging or underwater operations" 34 "Engaged in diving operations" 35 "Engaged in military operations" 36 "Sailing" 37 "Pleasure" 40 "High speed craft" 41 "High speed craft (hazard cat X)" 42 "High speed craft (hazard cat Y)" 43 "High speed craft (hazard cat Z)" 44 "High speed craft (hazard cat OS)" 49 "High speed craft (no additional information)" 50 "Pilot vessel" 51 "SAR" 52 "Tug" 53 "Port tender" 54 "Anti-pollution" 55 "Law enforcement" 56 "Spare" 57 "Spare #2" 58 "Medical" 59 "Ships and aircraft of States not parties to an armed conflict" 60 "Passenger ship" 61 "Passenger ship (hazard cat X)" 62 "Passenger ship (hazard cat Y)" 63 "Passenger ship (hazard cat Z)" 64 "Passenger ship (hazard cat OS)" 69 "Passenger ship (no additional information)" 70 "Cargo ship" 71 "Cargo ship (hazard cat X)" 72 "Cargo ship (hazard cat Y)" 73 "Cargo ship (hazard cat Z)" 74 "Cargo ship (hazard cat OS)" 79 "Cargo ship (no additional information)" 80 "Tanker" 81 "Tanker (hazard cat X)" 82 "Tanker (hazard cat Y)" 83 "Tanker (hazard cat Z)" 84 "Tanker (hazard cat OS)" 89 "Tanker (no additional information)" 90 "Other" 91 "Other (hazard cat X)" 92 "Other (hazard cat Y)" 93 "Other (hazard cat Z)" 94 "Other (hazard cat OS)" 99 "Other (no additional information)" ;
VAL_ 2583364096 AIS_version_indicator 0 "ITU-R M.1371-1" 1 "ITU-R M.1371-3" 2 "ITU-R M.1371-5" 3 "ITU-R M.1371 future edition" ;
VAL_ 2583364096 GNSS_type 0 "Default: undefined" 1 "GPS" 2 "GLONASS" 3 "Combined GPS/GLONASS" 4 "Loran-C" 5 "Chayka" 6 "Integrated navigation system" 7 "Surveyed" 8 "Galileo" ;
VAL_ 2583364096 DTE 0 "Available" 1 "Not available" ;
VAL_ 2583364096 AIS_Transceiver_information 0 "Channel A VDL reception" 1 "Channel B VDL reception" 2 "Channel A VDL transmission" 3 "Channel B VDL transmission" 4 "Own information not broadcast" 5 "Reserved" ;
VAL_ 2516255488 Message_ID 1 "Scheduled Class A position report" 2 "Assigned scheduled Class A position report" 3 "Interrogated Class A position report" 4 "Base station report" 5 "Static and voyage related data" 6 "Binary addressed message" 7 "Binary acknowledgement" 8 "Binary broadcast message" 9 "Standard SAR aircraft position report" 10 "UTC/date inquiry" 11 "UTC/date response" 12 "Safety related addressed message" 13 "Safety related acknowledgement" 14 "Satety related broadcast message" 15 "Interrogation" 16 "Assignment mode command" 17 "DGNSS broadcast binary message" 18 "Standard Class B position report" 19 "Extended Class B position report" 20 "Data link management message" 21 "ATON report" 22 "Channel management" 23 "Group assignment command" 24 "Static data report" 25 "Single slot binary message" 26 "Multiple slot binary message" 27 "Position report for long range applications" ;
VAL_ 2516255488 Repeat_Indicator 0 "Initial" 1 "First retransmission" 2 "Second retransmission" 3 "Final retransmission" ;
VAL_ 2516255488 AIS_Transceiver_information 0 "Channel A VDL reception" 1 "Channel B VDL reception" 2 "Channel A VDL transmission" 3 "Channel B VDL transmission" 4 "Own information not broadcast" 5 "Reserved" ;
VAL_ 2516255488 Retransmit_flag 0 "No" 1 "Yes" ;
VAL_ 2650473472 Message_ID 1 "Scheduled Class A position report" 2 "Assigned scheduled Class A position report" 3 "Interrogated Class A position report" 4 "Base station report" 5 "Static and voyage related data" 6 "Binary addressed message" 7 "Binary acknowledgement" 8 "Binary broadcast message" 9 "Standard SAR aircraft position report" 10 "UTC/date inquiry" 11 "UTC/date response" 12 "Safety related addressed message" 13 "Safety related acknowledgement" 14 "Satety related broadcast message" 15 "Interrogation" 16 "Assignment mode command" 17 "DGNSS broadcast binary message" 18 "Standard Class B position report" 19 "Extended Class B position report" 20 "Data link management message" 21 "ATON report" 22 "Channel management" 23 "Group assignment command" 24 "Static data report" 25 "Single slot binary message" 26 "Multiple slot binary message" 27 "Position report for long range applications" ;
VAL_ 2650473472 Repeat_Indicator 0 "Initial" 1 "First retransmission" 2 "Second retransmission" 3 "Final retransmission" ;
VAL_ 2650473472 AIS_Transceiver_information 0 "Channel A VDL reception" 1 "Channel B VDL reception" 2 "Channel A VDL transmission" 3 "Channel B VDL transmission" 4 "Own information not broadcast" 5 "Reserved" ;
VAL_ 2516256000 Message_ID 1 "Scheduled Class A position report" 2 "Assigned scheduled Class A position report" 3 "Interrogated Class A position report" 4 "Base station report" 5 "Static and voyage related data" 6 "Binary addressed message" 7 "Binary acknowledgement" 8 "Binary broadcast message" 9 "Standard SAR aircraft position report" 10 "UTC/date inquiry" 11 "UTC/date response" 12 "Safety related addressed message" 13 "Safety related acknowledgement" 14 "Satety related broadcast message" 15 "Interrogation" 16 "Assignment mode command" 17 "DGNSS broadcast binary message" 18 "Standard Class B position report" 19 "Extended Class B position report" 20 "Data link management message" 21 "ATON report" 22 "Channel management" 23 "Group assignment command" 24 "Static data report" 25 "Single slot binary message" 26 "Multiple slot binary message" 27 "Position report for long range applications" ;
VAL_ 2516256000 Repeat_Indicator 0 "Initial" 1 "First retransmission" 2 "Second retransmission" 3 "Final retransmission" ;
VAL_ 2516256000 AIS_Transceiver_information 0 "Channel A VDL reception" 1 "Channel B VDL reception" 2 "Channel A VDL transmission" 3 "Channel B VDL transmission" 4 "Own information not broadcast" 5 "Reserved" ;
VAL_ 2449147392 Message_ID 1 "Scheduled Class A position report" 2 "Assigned scheduled Class A position report" 3 "Interrogated Class A position report" 4 "Base station report" 5 "Static and voyage related data" 6 "Binary addressed message" 7 "Binary acknowledgement" 8 "Binary broadcast message" 9 "Standard SAR aircraft position report" 10 "UTC/date inquiry" 11 "UTC/date response" 12 "Safety related addressed message" 13 "Safety related acknowledgement" 14 "Satety related broadcast message" 15 "Interrogation" 16 "Assignment mode command" 17 "DGNSS broadcast binary message" 18 "Standard Class B position report" 19 "Extended Class B position report" 20 "Data link management message" 21 "ATON report" 22 "Channel management" 23 "Group assignment command" 24 "Static data report" 25 "Single slot binary message" 26 "Multiple slot binary message" 27 "Position report for long range applications" ;
VAL_ 2449147392 Repeat_Indicator 0 "Initial" 1 "First retransmission" 2 "Second retransmission" 3 "Final retransmission" ;
VAL_ 2449147392 Position_Accuracy 0 "Low" 1 "High" ;
VAL_ 2449147392 RAIM 0 "not in use" 1 "in use" ;
VAL_ 2449147392 Time_Stamp 60 "Not available" 61 "Manual input mode" 62 "Dead reckoning mode" 63 "Positioning system is inoperative" ;
VAL_ 2449147392 AIS_Transceiver_information 0 "Channel A VDL reception" 1 "Channel B VDL reception" 2 "Channel A VDL transmission" 3 "Channel B VDL transmission" 4 "Own information not broadcast" 5 "Reserved" ;
VAL_ 2449147392 DTE 0 "Available" 1 "Not available" ;
VAL_ 2382038784 Mode 0 "F3E/G3E simplex, telephone" 1 "F3E/G3E duplex, telephone" 2 "J3E, telephone" 3 "H3E, telephone" 4 "F1B/J2B FEC NBDP, telex/teleprinter" 5 "F1B/J2B ARQ NBDP, telex/teleprinter" 6 "F1B/J2B receive only, teleprinter/DSC" 7 "F1B/J2B, teleprinter/DSC" 8 "A1A Morse, tape recorder" 9 "A1A Morse, Morse key/head set" 10 "F1C/F2C/F3C, FAX machine" ;
VAL_ 2650474496 Message_ID 1 "Scheduled Class A position report" 2 "Assigned scheduled Class A position report" 3 "Interrogated Class A position report" 4 "Base station report" 5 "Static and voyage related data" 6 "Binary addressed message" 7 "Binary acknowledgement" 8 "Binary broadcast message" 9 "Standard SAR aircraft position report" 10 "UTC/date inquiry" 11 "UTC/date response" 12 "Safety related addressed message" 13 "Safety related acknowledgement" 14 "Satety related broadcast message" 15 "Interrogation" 16 "Assignment mode command" 17 "DGNSS broadcast binary message" 18 "Standard Class B position report" 19 "Extended Class B position report" 20 "Data link management message" 21 "ATON report" 22 "Channel management" 23 "Group assignment command" 24 "Static data report" 25 "Single slot binary message" 26 "Multiple slot binary message" 27 "Position report for long range applications" ;
VAL_ 2650474496 Repeat_Indicator 0 "Initial" 1 "First retransmission" 2 "Second retransmission" 3 "Final retransmission" ;
VAL_ 2650474496 AIS_Transceiver_information 0 "Channel A VDL reception" 1 "Channel B VDL reception" 2 "Channel A VDL transmission" 3 "Channel B VDL transmission" 4 "Own information not broadcast" 5 "Reserved" ;
VAL_ 2516257024 Message_ID 1 "Scheduled Class A position report" 2 "Assigned scheduled Class A position report" 3 "Interrogated Class A position report" 4 "Base station report" 5 "Static and voyage related data" 6 "Binary addressed message" 7 "Binary acknowledgement" 8 "Binary broadcast message" 9 "Standard SAR aircraft position report" 10 "UTC/date inquiry" 11 "UTC/date response" 12 "Safety related addressed message" 13 "Safety related acknowledgement" 14 "Satety related broadcast message" 15 "Interrogation" 16 "Assignment mode command" 17 "DGNSS broadcast binary message" 18 "Standard Class B position report" 19 "Extended Class B position report" 20 "Data link management message" 21 "ATON report" 22 "Channel management" 23 "Group assignment command" 24 "Static data report" 25 "Single slot binary message" 26 "Multiple slot binary message" 27 "Position report for long range applications" ;
VAL_ 2516257024 Repeat_Indicator 0 "Initial" 1 "First retransmission" 2 "Second retransmission" 3 "Final retransmission" ;
VAL_ 2516257024 AIS_Transceiver_information 0 "Channel A VDL reception" 1 "Channel B VDL reception" 2 "Channel A VDL transmission" 3 "Channel B VDL transmission" 4 "Own information not broadcast" 5 "Reserved" ;
VAL_ 2516257024 Retransmit_flag 0 "No" 1 "Yes" ;
VAL_ 2516257280 Message_ID 1 "Scheduled Class A position report" 2 "Assigned scheduled Class A position report" 3 "Interrogated Class A position report" 4 "Base station report" 5 "Static and voyage related data" 6 "Binary addressed message" 7 "Binary acknowledgement" 8 "Binary broadcast message" 9 "Standard SAR aircraft position report" 10 "UTC/date inquiry" 11 "UTC/date response" 12 "Safety related addressed message" 13 "Safety related acknowledgement" 14 "Satety related broadcast message" 15 "Interrogation" 16 "Assignment mode command" 17 "DGNSS broadcast binary message" 18 "Standard Class B position report" 19 "Extended Class B position report" 20 "Data link management message" 21 "ATON report" 22 "Channel management" 23 "Group assignment command" 24 "Static data report" 25 "Single slot binary message" 26 "Multiple slot binary message" 27 "Position report for long range applications" ;
VAL_ 2516257280 Repeat_Indicator 0 "Initial" 1 "First retransmission" 2 "Second retransmission" 3 "Final retransmission" ;
VAL_ 2516257280 AIS_Transceiver_information 0 "Channel A VDL reception" 1 "Channel B VDL reception" 2 "Channel A VDL transmission" 3 "Channel B VDL transmission" 4 "Own information not broadcast" 5 "Reserved" ;
VAL_ 2650475264 Message_ID 1 "Scheduled Class A position report" 2 "Assigned scheduled Class A position report" 3 "Interrogated Class A position report" 4 "Base station report" 5 "Static and voyage related data" 6 "Binary addressed message" 7 "Binary acknowledgement" 8 "Binary broadcast message" 9 "Standard SAR aircraft position report" 10 "UTC/date inquiry" 11 "UTC/date response" 12 "Safety related addressed message" 13 "Safety related acknowledgement" 14 "Satety related broadcast message" 15 "Interrogation" 16 "Assignment mode command" 17 "DGNSS broadcast binary message" 18 "Standard Class B position report" 19 "Extended Class B position report" 20 "Data link management message" 21 "ATON report" 22 "Channel management" 23 "Group assignment command" 24 "Static data report" 25 "Single slot binary message" 26 "Multiple slot binary message" 27 "Position report for long range applications" ;
VAL_ 2650475264 Repeat_Indicator 0 "Initial" 1 "First retransmission" 2 "Second retransmission" 3 "Final retransmission" ;
VAL_ 2650475264 AIS_Transceiver_information 0 "Channel A VDL reception" 1 "Channel B VDL reception" 2 "Channel A VDL transmission" 3 "Channel B VDL transmission" 4 "Own information not broadcast" 5 "Reserved" ;
VAL_ 2650475264 Message_ID_1_1 1 "Scheduled Class A position report" 2 "Assigned scheduled Class A position report" 3 "Interrogated Class A position report" 4 "Base station report" 5 "Static and voyage related data" 6 "Binary addressed message" 7 "Binary acknowledgement" 8 "Binary broadcast message" 9 "Standard SAR aircraft position report" 10 "UTC/date inquiry" 11 "UTC/date response" 12 "Safety related addressed message" 13 "Safety related acknowledgement" 14 "Satety related broadcast message" 15 "Interrogation" 16 "Assignment mode command" 17 "DGNSS broadcast binary message" 18 "Standard Class B position report" 19 "Extended Class B position report" 20 "Data link management message" 21 "ATON report" 22 "Channel management" 23 "Group assignment command" 24 "Static data report" 25 "Single slot binary message" 26 "Multiple slot binary message" 27 "Position report for long range applications" ;
VAL_ 2650475264 Message_ID_1_2 1 "Scheduled Class A position report" 2 "Assigned scheduled Class A position report" 3 "Interrogated Class A position report" 4 "Base station report" 5 "Static and voyage related data" 6 "Binary addressed message" 7 "Binary acknowledgement" 8 "Binary broadcast message" 9 "Standard SAR aircraft position report" 10 "UTC/date inquiry" 11 "UTC/date response" 12 "Safety related addressed message" 13 "Safety related acknowledgement" 14 "Satety related broadcast message" 15 "Interrogation" 16 "Assignment mode command" 17 "DGNSS broadcast binary message" 18 "Standard Class B position report" 19 "Extended Class B position report" 20 "Data link management message" 21 "ATON report" 22 "Channel management" 23 "Group assignment command" 24 "Static data report" 25 "Single slot binary message" 26 "Multiple slot binary message" 27 "Position report for long range applications" ;
VAL_ 2650475264 Message_ID_2_1 1 "Scheduled Class A position report" 2 "Assigned scheduled Class A position report" 3 "Interrogated Class A position report" 4 "Base station report" 5 "Static and voyage related data" 6 "Binary addressed message" 7 "Binary acknowledgement" 8 "Binary broadcast message" 9 "Standard SAR aircraft position report" 10 "UTC/date inquiry" 11 "UTC/date response" 12 "Safety related addressed message" 13 "Safety related acknowledgement" 14 "Satety related broadcast message" 15 "Interrogation" 16 "Assignment mode command" 17 "DGNSS broadcast binary message" 18 "Standard Class B position report" 19 "Extended Class B position report" 20 "Data link management message" 21 "ATON report" 22 "Channel management" 23 "Group assignment command" 24 "Static data report" 25 "Single slot binary message" 26 "Multiple slot binary message" 27 "Position report for long range applications" ;
VAL_ 2650475520 Message_ID 1 "Scheduled Class A position report" 2 "Assigned scheduled Class A position report" 3 "Interrogated Class A position report" 4 "Base station report" 5 "Static and voyage related data" 6 "Binary addressed message" 7 "Binary acknowledgement" 8 "Binary broadcast message" 9 "Standard SAR aircraft position report" 10 "UTC/date inquiry" 11 "UTC/date response" 12 "Safety related addressed message" 13 "Safety related acknowledgement" 14 "Satety related broadcast message" 15 "Interrogation" 16 "Assignment mode command" 17 "DGNSS broadcast binary message" 18 "Standard Class B position report" 19 "Extended Class B position report" 20 "Data link management message" 21 "ATON report" 22 "Channel management" 23 "Group assignment command" 24 "Static data report" 25 "Single slot binary message" 26 "Multiple slot binary message" 27 "Position report for long range applications" ;
VAL_ 2650475520 Repeat_Indicator 0 "Initial" 1 "First retransmission" 2 "Second retransmission" 3 "Final retransmission" ;
VAL_ 2650475520 AIS_Transceiver_information 0 "Channel A VDL reception" 1 "Channel B VDL reception" 2 "Channel A VDL transmission" 3 "Channel B VDL transmission" 4 "Own information not broadcast" 5 "Reserved" ;
CM_ SG_ 2582647808 Model_ID "STRING field: decode bytes as ASCII (0x00/@/0xFF = terminator); canboat type: STRING_FIX";
CM_ SG_ 2582647808 Software_Version_Code "STRING field: decode bytes as ASCII (0x00/@/0xFF = terminator); canboat type: STRING_FIX";
CM_ SG_ 2582647808 Model_Version "STRING field: decode bytes as ASCII (0x00/@/0xFF = terminator); canboat type: STRING_FIX";
CM_ SG_ 2582647808 Model_Serial_Code "STRING field: decode bytes as ASCII (0x00/@/0xFF = terminator); canboat type: STRING_FIX";
CM_ SG_ 2582648320 Installation_Description__1 "STRING field: decode bytes as ASCII (0x00/@/0xFF = terminator); canboat type: STRING_LAU";
CM_ SG_ 2582648320 Installation_Description__2 "STRING field: decode bytes as ASCII (0x00/@/0xFF = terminator); canboat type: STRING_LAU";
CM_ SG_ 2582648320 Manufacturer_Information "STRING field: decode bytes as ASCII (0x00/@/0xFF = terminator); canboat type: STRING_LAU";
CM_ SG_ 2515667456 VIN "STRING field: decode bytes as ASCII (0x00/@/0xFF = terminator); canboat type: STRING_LAU";
CM_ SG_ 2515667456 Software_ID "STRING field: decode bytes as ASCII (0x00/@/0xFF = terminator); canboat type: STRING_LAU";
CM_ SG_ 2314602496 Name "STRING field: decode bytes as ASCII (0x00/@/0xFF = terminator); canboat type: STRING_LAU";
CM_ SG_ 2448953344 Name "STRING field: decode bytes as ASCII (0x00/@/0xFF = terminator); canboat type: STRING_FIX";
CM_ SG_ 2448953600 AtoN_Name "STRING field: decode bytes as ASCII (0x00/@/0xFF = terminator); canboat type: STRING_LAU";
CM_ SG_ 2583172096 Local_Datum "STRING field: decode bytes as ASCII (0x00/@/0xFF = terminator); canboat type: STRING_FIX";
CM_ SG_ 2583172096 Reference_Datum "STRING field: decode bytes as ASCII (0x00/@/0xFF = terminator); canboat type: STRING_FIX";
CM_ SG_ 2583172352 Datum_Name "STRING field: decode bytes as ASCII (0x00/@/0xFF = terminator); canboat type: STRING_FIX";
CM_ SG_ 2583233792 Route_Name "STRING field: decode bytes as ASCII (0x00/@/0xFF = terminator); canboat type: STRING_LAU";
CM_ SG_ 2583364096 Callsign "STRING field: decode bytes as ASCII (0x00/@/0xFF = terminator); canboat type: STRING_FIX";
CM_ SG_ 2583364096 Name "STRING field: decode bytes as ASCII (0x00/@/0xFF = terminator); canboat type: STRING_FIX";
CM_ SG_ 2583364096 Destination "STRING field: decode bytes as ASCII (0x00/@/0xFF = terminator); canboat type: STRING_FIX";
CM_ SG_ 2382038784 Radio_Channel "STRING field: decode bytes as ASCII (0x00/@/0xFF = terminator); canboat type: STRING_FIX";
CM_ SG_ 2516257024 Safety_Related_Text "STRING field: decode bytes as ASCII (0x00/@/0xFF = terminator); canboat type: STRING_LAU";
CM_ SG_ 2516257280 Safety_Related_Text "STRING field: decode bytes as ASCII (0x00/@/0xFF = terminator); canboat type: STRING_LAU";

BA_DEF_ BO_ "GenMsgCycleTime" INT 0 60000;
BA_DEF_ BO_ "ProtocolType" STRING;

BA_DEF_ BO_ "J1939PGN" INT 0 262143;
BA_ "J1939PGN" BO_ 2582645504 126987;
BA_ "J1939PGN" BO_ 2582645760 126988;
BA_ "J1939PGN" BO_ 2381320192 126992;
BA_ "GenMsgCycleTime" BO_ 2381320192 1000;
BA_ "J1939PGN" BO_ 2649755904 126993;
BA_ "GenMsgCycleTime" BO_ 2649755904 60000;
BA_ "J1939PGN" BO_ 2582647808 126996;
BA_ "J1939PGN" BO_ 2582648320 126998;
BA_ "J1939PGN" BO_ 2582708480 127233;
BA_ "J1939PGN" BO_ 2314274048 127237;
BA_ "GenMsgCycleTime" BO_ 2314274048 250;
BA_ "J1939PGN" BO_ 2314276096 127245;
BA_ "GenMsgCycleTime" BO_ 2314276096 100;
BA_ "J1939PGN" BO_ 2314277376 127250;
BA_ "GenMsgCycleTime" BO_ 2314277376 100;
BA_ "J1939PGN" BO_ 2314277632 127251;
BA_ "GenMsgCycleTime" BO_ 2314277632 100;
BA_ "J1939PGN" BO_ 2381386752 127252;
BA_ "J1939PGN" BO_ 2381388032 127257;
BA_ "GenMsgCycleTime" BO_ 2381388032 1000;
BA_ "J1939PGN" BO_ 2649823744 127258;
BA_ "GenMsgCycleTime" BO_ 2649823744 1000;
BA_ "J1939PGN" BO_ 2314338304 127488;
BA_ "GenMsgCycleTime" BO_ 2314338304 100;
BA_ "J1939PGN" BO_ 2314338560 127489;
BA_ "GenMsgCycleTime" BO_ 2314338560 500;
BA_ "J1939PGN" BO_ 2582774272 127490;
BA_ "J1939PGN" BO_ 2582774528 127491;
BA_ "J1939PGN" BO_ 2314339584 127493;
BA_ "GenMsgCycleTime" BO_ 2314339584 100;
BA_ "J1939PGN" BO_ 2582775296 127494;
BA_ "J1939PGN" BO_ 2582775552 127495;
BA_ "J1939PGN" BO_ 2515666944 127496;
BA_ "GenMsgCycleTime" BO_ 2515666944 1000;
BA_ "J1939PGN" BO_ 2515667200 127497;
BA_ "GenMsgCycleTime" BO_ 2515667200 1000;
BA_ "J1939PGN" BO_ 2515667456 127498;
BA_ "J1939PGN" BO_ 2582776832 127500;
BA_ "J1939PGN" BO_ 2381450496 127501;
BA_ "J1939PGN" BO_ 2381450752 127502;
BA_ "J1939PGN" BO_ 2582777600 127503;
BA_ "GenMsgCycleTime" BO_ 2582777600 1500;
BA_ "J1939PGN" BO_ 2582777856 127504;
BA_ "GenMsgCycleTime" BO_ 2582777856 1500;
BA_ "J1939PGN" BO_ 2582778112 127505;
BA_ "GenMsgCycleTime" BO_ 2582778112 2500;
BA_ "J1939PGN" BO_ 2582778368 127506;
BA_ "GenMsgCycleTime" BO_ 2582778368 1500;
BA_ "J1939PGN" BO_ 2582778624 127507;
BA_ "GenMsgCycleTime" BO_ 2582778624 1500;
BA_ "J1939PGN" BO_ 2582778880 127508;
BA_ "GenMsgCycleTime" BO_ 2582778880 1500;
BA_ "J1939PGN" BO_ 2582779136 127509;
BA_ "GenMsgCycleTime" BO_ 2582779136 1500;
BA_ "J1939PGN" BO_ 2582779392 127510;
BA_ "J1939PGN" BO_ 2582779648 127511;
BA_ "J1939PGN" BO_ 2582779904 127512;
BA_ "J1939PGN" BO_ 2582780160 127513;
BA_ "J1939PGN" BO_ 2582780416 127514;
BA_ "GenMsgCycleTime" BO_ 2582780416 1500;
BA_ "J1939PGN" BO_ 2582839296 127744;
BA_ "J1939PGN" BO_ 2582839552 127745;
BA_ "J1939PGN" BO_ 2582839808 127746;
BA_ "J1939PGN" BO_ 2582840064 127747;
BA_ "J1939PGN" BO_ 2582840320 127748;
BA_ "J1939PGN" BO_ 2582840576 127749;
BA_ "J1939PGN" BO_ 2582840832 127750;
BA_ "J1939PGN" BO_ 2582841088 127751;
BA_ "J1939PGN" BO_ 2582904832 128000;
BA_ "J1939PGN" BO_ 2582905088 128001;
BA_ "J1939PGN" BO_ 2582905344 128002;
BA_ "J1939PGN" BO_ 2582905600 128003;
BA_ "J1939PGN" BO_ 2582906368 128006;
BA_ "J1939PGN" BO_ 2582906624 128007;
BA_ "J1939PGN" BO_ 2582906880 128008;
BA_ "J1939PGN" BO_ 2314535680 128259;
BA_ "GenMsgCycleTime" BO_ 2314535680 1000;
BA_ "J1939PGN" BO_ 2381646592 128267;
BA_ "GenMsgCycleTime" BO_ 2381646592 1000;
BA_ "J1939PGN" BO_ 2582975232 128275;
BA_ "GenMsgCycleTime" BO_ 2582975232 1000;
BA_ "J1939PGN" BO_ 2314602496 128520;
BA_ "GenMsgCycleTime" BO_ 2314602496 1000;
BA_ "J1939PGN" BO_ 2583042560 128538;
BA_ "J1939PGN" BO_ 2583101440 128768;
BA_ "J1939PGN" BO_ 2583101696 128769;
BA_ "J1939PGN" BO_ 2583103488 128776;
BA_ "J1939PGN" BO_ 2583103744 128777;
BA_ "J1939PGN" BO_ 2583104000 128778;
BA_ "J1939PGN" BO_ 2583104512 128780;
BA_ "J1939PGN" BO_ 2314731776 129025;
BA_ "GenMsgCycleTime" BO_ 2314731776 100;
BA_ "J1939PGN" BO_ 2314732032 129026;
BA_ "GenMsgCycleTime" BO_ 2314732032 250;
BA_ "J1939PGN" BO_ 2314732288 129027;
BA_ "GenMsgCycleTime" BO_ 2314732288 100;
BA_ "J1939PGN" BO_ 2314732544 129028;
BA_ "GenMsgCycleTime" BO_ 2314732544 100;
BA_ "J1939PGN" BO_ 2381841664 129029;
BA_ "GenMsgCycleTime" BO_ 2381841664 1000;
BA_ "J1939PGN" BO_ 2381842688 129033;
BA_ "GenMsgCycleTime" BO_ 2381842688 1000;
BA_ "J1939PGN" BO_ 2448952832 129038;
BA_ "J1939PGN" BO_ 2448953088 129039;
BA_ "J1939PGN" BO_ 2448953344 129040;
BA_ "J1939PGN" BO_ 2448953600 129041;
BA_ "J1939PGN" BO_ 2583172096 129044;
BA_ "GenMsgCycleTime" BO_ 2583172096 10000;
BA_ "J1939PGN" BO_ 2583172352 129045;
BA_ "J1939PGN" BO_ 2381906688 129283;
BA_ "GenMsgCycleTime" BO_ 2381906688 1000;
BA_ "J1939PGN" BO_ 2381906944 129284;
BA_ "GenMsgCycleTime" BO_ 2381906944 1000;
BA_ "J1939PGN" BO_ 2583233792 129285;
BA_ "J1939PGN" BO_ 2381908736 129291;
BA_ "GenMsgCycleTime" BO_ 2381908736 1000;
BA_ "J1939PGN" BO_ 2381911296 129301;
BA_ "GenMsgCycleTime" BO_ 2381911296 1000;
BA_ "J1939PGN" BO_ 2583238144 129302;
BA_ "J1939PGN" BO_ 2583298560 129538;
BA_ "J1939PGN" BO_ 2583298816 129539;
BA_ "GenMsgCycleTime" BO_ 2583298816 1000;
BA_ "J1939PGN" BO_ 2583299072 129540;
BA_ "GenMsgCycleTime" BO_ 2583299072 1000;
BA_ "J1939PGN" BO_ 2583299328 129541;
BA_ "J1939PGN" BO_ 2583299584 129542;
BA_ "GenMsgCycleTime" BO_ 2583299584 1000;
BA_ "J1939PGN" BO_ 2583300352 129545;
BA_ "J1939PGN" BO_ 2583300608 129546;
BA_ "J1939PGN" BO_ 2583300864 129547;
BA_ "J1939PGN" BO_ 2583301376 129549;
BA_ "J1939PGN" BO_ 2583301632 129550;
BA_ "J1939PGN" BO_ 2583301888 129551;
BA_ "J1939PGN" BO_ 2583303168 129556;
BA_ "J1939PGN" BO_ 2583363584 129792;
BA_ "J1939PGN" BO_ 2650472704 129793;
BA_ "J1939PGN" BO_ 2583364096 129794;
BA_ "J1939PGN" BO_ 2516255488 129795;
BA_ "J1939PGN" BO_ 2650473472 129796;
BA_ "J1939PGN" BO_ 2516256000 129797;
BA_ "J1939PGN" BO_ 2449147392 129798;
BA_ "J1939PGN" BO_ 2382038784 129799;
BA_ "J1939PGN" BO_ 2650474496 129800;
BA_ "J1939PGN" BO_ 2516257024 129801;
BA_ "J1939PGN" BO_ 2516257280 129802;
BA_ "J1939PGN" BO_ 2650475264 129803;
BA_ "J1939PGN" BO_ 2650475520 129804;
